VERSION ""

NS_ :

BS_:

BU_: RFA_BLEM TCU GWM _delete GENERIC TSTR
VAL_TABLE_ Null_Passive_Active_NotUsed_1 3 "NotUsed_1" 2 "Active" 1 "Passive" 0 "Null" ;
VAL_TABLE_ VehStrtKeySrc_D_Stat 7 "NotUsed_4" 6 "NotUsed_3" 5 "NotUsed_2" 4 "NotUsed_1" 3 "Legacy_Paak" 2 "Peps_and_Ikt" 1 "Digital_Key" 0 "Null" ;
VAL_TABLE_ StopStrtImccActv_D_St 7 "NotUsed_3" 6 "NotUsed_2" 5 "NotUsed_1" 4 "Deactivated" 3 "OnSuspended" 2 "OnActive" 1 "OnNotActive" 0 "Off" ;
VAL_TABLE_ UpftrEnbl_D_Stat 7 "Error" 6 "AuxAcEnable" 5 "PtoOperation" 4 "FuelEcoModeEnable" 3 "Disable" 2 "Enable" 1 "DisableAttempt" 0 "Reset" ;
VAL_TABLE_ Reset_Off_On_Error 3 "Error" 2 "On" 1 "Off" 0 "Reset" ;
VAL_TABLE_ NfcSerial_D_Rq 3 "PresentAndProvisioned" 2 "PresentAndProvAlertAck" 1 "PresentAndUnprovisioned" 0 "NotPresent" ;
VAL_TABLE_ NoRequest_Disable_Enable_NotUsed 3 "NotUsed_1" 2 "Enable" 1 "Disable" 0 "NoRequest" ;
VAL_TABLE_ AwdLckMde_D_Stat 7 "NotUsed_2" 6 "NotUsed_1" 5 "PrimaryAxleSpeedControl" 4 "DualAxleSpeedControl" 3 "EfficiencySplit" 2 "SecondaryAxleTorqueCtrl" 1 "SecondaryAxleSpeedCtrl" 0 "Off" ;
VAL_TABLE_ EngIdlShutDown_D2_Type 3 "Fleet" 2 "Keyless" 1 "Keyed" 0 "Null" ;
VAL_TABLE_ TlghtTestPrecnd_D2_Stat 7 "TrailerNotConnected" 6 "NotStationary" 5 "InteractionPresent" 4 "PreconditionsPassed" 3 "BattSocLessThan75Percent" 2 "TailLightsOn" 1 "IgnitionNotOn" 0 "Null" ;
VAL_TABLE_ TlghtTestLght_D2_Stat 7 "TestingRearFogLights" 6 "AllOff" 5 "TestingReverseLights" 4 "TestingBrakeLights" 3 "TestingLeftTurnSignal" 2 "TestingRightTurnSignal" 1 "ParkingLightsIlluminated" 0 "Null" ;
VAL_TABLE_ PwTrnkFrontRleas_D_Src 15 "NotUsed_5" 14 "NotUsed_4" 13 "NotUsed_3" 12 "NotUsed_2" 11 "NotUsed_1" 10 "SelfTest" 9 "Diagnostics" 8 "EmergencyReleaseSwitch" 7 "ManualCinch" 6 "ExteriorSwitch" 5 "IpSwitch" 4 "Cpp" 3 "Sync" 2 "Keypad" 1 "Remote" 0 "PowerOff" ;
VAL_TABLE_ StrtrMtrCtlMsgTxt_D_Rq2 15 "Not_Used_12" 14 "Not_Used_11" 13 "Not_Used_10" 12 "Not_Used_9" 11 "Not_Used_8" 10 "Not_Used_7" 9 "Not_Used_6" 8 "Not_Used_5" 7 "Not_Used_4" 6 "Not_Used_3" 5 "Not_Used_2" 4 "Not_Used_1" 3 "Fault_UnableToStrtOrStop" 2 "PressTwiceToStart" 1 "Fault_GoToDealer" 0 "NoMessage" ;
VAL_TABLE_ BptStrtStop_D_Stat 3 "NotUsed_1" 2 "Start" 1 "Stop" 0 "NoRequest" ;
VAL_TABLE_ BptMde_D_Stat 7 "NotUsed_4" 6 "NotUsed_3" 5 "NotUsed_2" 4 "NotUsed_1" 3 "Automatic" 2 "Manual" 1 "Off" 0 "Null" ;
VAL_TABLE_ NoData_Faulty_7FFFFE_7FFFFF 8388607 "Faulty" 8388606 "NoDataExists" ;
VAL_TABLE_ NoData_Faulty_3FFFFE_3FFFFF 4194303 "Faulty" 4194302 "NoDataExists" ;
VAL_TABLE_ BattChrgInhbt_D2_Rq 7 "NotUsed_4" 6 "NotUsed_3" 5 "NotUsed_2" 4 "NotUsed_1" 3 "MaintainTargetSoc" 2 "EndAtTarget" 1 "InhibitCharging" 0 "Enable_Charging" ;
VAL_TABLE_ EngIdlShutDownT_D_Stat 255 "NotUsed_13" 254 "NotUsed_12" 253 "NotUsed_11" 252 "NotUsed_10" 251 "NotUsed_9" 250 "NotUsed_8" 249 "NotUsed_7" 248 "NotUsed_6" 247 "NotUsed_5" 246 "NotUsed_4" 245 "NotUsed_3" 244 "NotUsed_2" 243 "NotUsed_1" 242 "Indefinite_Idle" 241 "Selectable_Idle_Not_Active" 240 "IdleMinutes_240" 239 "IdleMinutes_239" 238 "IdleMinutes_238" 237 "IdleMinutes_237" 236 "IdleMinutes_236" 235 "IdleMinutes_235" 234 "IdleMinutes_234" 233 "IdleMinutes_233" 232 "IdleMinutes_232" 231 "IdleMinutes_231" 230 "IdleMinutes_230" 229 "IdleMinutes_229" 228 "IdleMinutes_228" 227 "IdleMinutes_227" 226 "IdleMinutes_226" 225 "IdleMinutes_225" 224 "IdleMinutes_224" 223 "IdleMinutes_223" 222 "IdleMinutes_222" 221 "IdleMinutes_221" 220 "IdleMinutes_220" 219 "IdleMinutes_219" 218 "IdleMinutes_218" 217 "IdleMinutes_217" 216 "IdleMinutes_216" 215 "IdleMinutes_215" 214 "IdleMinutes_214" 213 "IdleMinutes_213" 212 "IdleMinutes_212" 211 "IdleMinutes_211" 210 "IdleMinutes_210" 209 "IdleMinutes_209" 208 "IdleMinutes_208" 207 "IdleMinutes_207" 206 "IdleMinutes_206" 205 "IdleMinutes_205" 204 "IdleMinutes_204" 203 "IdleMinutes_203" 202 "IdleMinutes_202" 201 "IdleMinutes_201" 200 "IdleMinutes_200" 199 "IdleMinutes_199" 198 "IdleMinutes_198" 197 "IdleMinutes_197" 196 "IdleMinutes_196" 195 "IdleMinutes_195" 194 "IdleMinutes_194" 193 "IdleMinutes_193" 192 "IdleMinutes_192" 191 "IdleMinutes_191" 190 "IdleMinutes_190" 189 "IdleMinutes_189" 188 "IdleMinutes_188" 187 "IdleMinutes_187" 186 "IdleMinutes_186" 185 "IdleMinutes_185" 184 "IdleMinutes_184" 183 "IdleMinutes_183" 182 "IdleMinutes_182" 181 "IdleMinutes_181" 180 "IdleMinutes_180" 179 "IdleMinutes_179" 178 "IdleMinutes_178" 177 "IdleMinutes_177" 176 "IdleMinutes_176" 175 "IdleMinutes_175" 174 "IdleMinutes_174" 173 "IdleMinutes_173" 172 "IdleMinutes_172" 171 "IdleMinutes_171" 170 "IdleMinutes_170" 169 "IdleMinutes_169" 168 "IdleMinutes_168" 167 "IdleMinutes_167" 166 "IdleMinutes_166" 165 "IdleMinutes_165" 164 "IdleMinutes_164" 163 "IdleMinutes_163" 162 "IdleMinutes_162" 161 "IdleMinutes_161" 160 "IdleMinutes_160" 159 "IdleMinutes_159" 158 "IdleMinutes_158" 157 "IdleMinutes_157" 156 "IdleMinutes_156" 155 "IdleMinutes_155" 154 "IdleMinutes_154" 153 "IdleMinutes_153" 152 "IdleMinutes_152" 151 "IdleMinutes_151" 150 "IdleMinutes_150" 149 "IdleMinutes_149" 148 "IdleMinutes_148" 147 "IdleMinutes_147" 146 "IdleMinutes_146" 145 "IdleMinutes_145" 144 "IdleMinutes_144" 143 "IdleMinutes_143" 142 "IdleMinutes_142" 141 "IdleMinutes_141" 140 "IdleMinutes_140" 139 "IdleMinutes_139" 138 "IdleMinutes_138" 137 "IdleMinutes_137" 136 "IdleMinutes_136" 135 "IdleMinutes_135" 134 "IdleMinutes_134" 133 "IdleMinutes_133" 132 "IdleMinutes_132" 131 "IdleMinutes_131" 130 "IdleMinutes_130" 129 "IdleMinutes_129" 128 "IdleMinutes_128" 127 "IdleMinutes_127" 126 "IdleMinutes_126" 125 "IdleMinutes_125" 124 "IdleMinutes_124" 123 "IdleMinutes_123" 122 "IdleMinutes_122" 121 "IdleMinutes_121" 120 "IdleMinutes_120" 119 "IdleMinutes_119" 118 "IdleMinutes_118" 117 "IdleMinutes_117" 116 "IdleMinutes_116" 115 "IdleMinutes_115" 114 "IdleMinutes_114" 113 "IdleMinutes_113" 112 "IdleMinutes_112" 111 "IdleMinutes_111" 110 "IdleMinutes_110" 109 "IdleMinutes_109" 108 "IdleMinutes_108" 107 "IdleMinutes_107" 106 "IdleMinutes_106" 105 "IdleMinutes_105" 104 "IdleMinutes_104" 103 "IdleMinutes_103" 102 "IdleMinutes_102" 101 "IdleMinutes_101" 100 "IdleMinutes_100" 99 "IdleMinutes_99" 98 "IdleMinutes_98" 97 "IdleMinutes_97" 96 "IdleMinutes_96" 95 "IdleMinutes_95" 94 "IdleMinutes_94" 93 "IdleMinutes_93" 92 "IdleMinutes_92" 91 "IdleMinutes_91" 90 "IdleMinutes_90" 89 "IdleMinutes_89" 88 "IdleMinutes_88" 87 "IdleMinutes_87" 86 "IdleMinutes_86" 85 "IdleMinutes_85" 84 "IdleMinutes_84" 83 "IdleMinutes_83" 82 "IdleMinutes_82" 81 "IdleMinutes_81" 80 "IdleMinutes_80" 79 "IdleMinutes_79" 78 "IdleMinutes_78" 77 "IdleMinutes_77" 76 "IdleMinutes_76" 75 "IdleMinutes_75" 74 "IdleMinutes_74" 73 "IdleMinutes_73" 72 "IdleMinutes_72" 71 "IdleMinutes_71" 70 "IdleMinutes_70" 69 "IdleMinutes_69" 68 "IdleMinutes_68" 67 "IdleMinutes_67" 66 "IdleMinutes_66" 65 "IdleMinutes_65" 64 "IdleMinutes_64" 63 "IdleMinutes_63" 62 "IdleMinutes_62" 61 "IdleMinutes_61" 60 "IdleMinutes_60" 59 "IdleMinutes_59" 58 "IdleMinutes_58" 57 "IdleMinutes_57" 56 "IdleMinutes_56" 55 "IdleMinutes_55" 54 "IdleMinutes_54" 53 "IdleMinutes_53" 52 "IdleMinutes_52" 51 "IdleMinutes_51" 50 "IdleMinutes_50" 49 "IdleMinutes_49" 48 "IdleMinutes_48" 47 "IdleMinutes_47" 46 "IdleMinutes_46" 45 "IdleMinutes_45" 44 "IdleMinutes_44" 43 "IdleMinutes_43" 42 "IdleMinutes_42" 41 "IdleMinutes_41" 40 "IdleMinutes_40" 39 "IdleMinutes_39" 38 "IdleMinutes_38" 37 "IdleMinutes_37" 36 "IdleMinutes_36" 35 "IdleMinutes_35" 34 "IdleMinutes_34" 33 "IdleMinutes_33" 32 "IdleMinutes_32" 31 "IdleMinutes_31" 30 "IdleMinutes_30" 29 "IdleMinutes_29" 28 "IdleMinutes_28" 27 "IdleMinutes_27" 26 "IdleMinutes_26" 25 "IdleMinutes_25" 24 "IdleMinutes_24" 23 "IdleMinutes_23" 22 "IdleMinutes_22" 21 "IdleMinutes_21" 20 "IdleMinutes_20" 19 "IdleMinutes_19" 18 "IdleMinutes_18" 17 "IdleMinutes_17" 16 "IdleMinutes_16" 15 "IdleMinutes_15" 14 "IdleMinutes_14" 13 "IdleMinutes_13" 12 "IdleMinutes_12" 11 "IdleMinutes_11" 10 "IdleMinutes_10" 9 "IdleMinutes_9" 8 "IdleMinutes_8" 7 "IdleMinutes_7" 6 "IdleMinutes_6" 5 "IdleMinutes_5" 4 "IdleMinutes_4" 3 "IdleMinutes_3" 2 "IdleMinutes_2" 1 "IdleMinute_1" 0 "Null" ;
VAL_TABLE_ Null_Valid 1 "Valid" 0 "Null" ;
VAL_TABLE_ Null_Factory_User_NotUsed_1 3 "NotUsed_1" 2 "User" 1 "Factory" 0 "Null" ;
VAL_TABLE_ Null_Short_Long_NotUsed_1 3 "NotUsed_1" 2 "Long" 1 "Short" 0 "Null" ;
VAL_TABLE_ NfcDevcDetct_D_Stat 15 "NotUsed_7" 14 "NotUsed_6" 13 "NotUsed_5" 12 "NotUsed_4" 11 "NotUsed_3" 10 "NotUsed_2" 9 "NotUsed_1" 8 "Int2Charging" 7 "Int1Starting" 6 "Ext6FrontEndReader" 5 "Ext5DBackEndReader" 4 "Ext4RrDoorReader" 3 "Ext3RlDoorReader" 2 "Ext2FrDoorReader" 1 "Ext1FlDoorReader" 0 "Null" ;
VAL_TABLE_ NfcDevc_D_Cmd 7 "NotUsed_4" 6 "NotUsed_3" 5 "NotUsed_2" 4 "NotUsed_1" 3 "RemoveAll" 2 "Remove" 1 "Add" 0 "Null" ;
VAL_TABLE_ Null_Fail_Success_NotUsed_1 3 "NotUsed_1" 2 "Success" 1 "Fail" 0 "Null" ;
VAL_TABLE_ NoEve_0_NotSup_FE_Faulty_FF 255 "Faulty" 254 "Not Supported" 0 "No Event" ;
VAL_TABLE_ NoEve_0_NotSup_1FFE_Faulty_1FFF 8191 "Faulty" 8190 "Not Supported" 0 "No Event" ;
VAL_TABLE_ NfcDevc_D_Dsply 15 "Message 15" 14 "Message 14" 13 "Message 13" 12 "Message 12" 11 "Message 11" 10 "Message 10" 9 "Message 9" 8 "Message 8" 7 "Message 7" 6 "Message 6" 5 "Message 5" 4 "Message 4" 3 "Message 3" 2 "Message 2" 1 "Message 1" 0 "No message" ;
VAL_TABLE_ SecondRowBuckle2 7 "Faulty" 6 "OccupiedBelted" 5 "SeatAbsent" 4 "EmptyUnbelted" 3 "OccupiedUnbelted" 2 "BatteryLow" 1 "NotDetermined" 0 "EmptyBelted" ;
VAL_TABLE_ VehOnSrc_D_Stat 15 "NotUsed_11" 14 "NotUsed_10" 13 "NotUsed_9" 12 "NotUsed_8" 11 "NotUsed_7" 10 "NotUsed_6" 9 "EsclRssd" 8 "AutonomousVehicle" 7 "SecureIdle" 6 "FleetVehicleInhibit" 5 "StolenVehicleInhibit" 4 "OverTheAir" 3 "RemoteParkAssist" 2 "RemoteStart" 1 "Manual" 0 "Off" ;
VAL_TABLE_ StrtrMtrCtlMsgTxt_D2_Rq 3 "NoRequestPcmStartingMsgCtl" 2 "ShiftToNeutralToStart" 1 "ShiftToParkToStart" 0 "NoRequestBcmStartingMsgCtl" ;
VAL_TABLE_ GearPrkLck_D_Stat 7 "NotUsed_1" 6 "FetLifeLimitReached" 5 "FetOpenCircuit" 4 "FetOutputShortToPower" 3 "FetOutputShortToGround" 2 "FetNotControlled" 1 "OnPowerToLoad" 0 "OffNoPowerToLoad" ;
VAL_TABLE_ PaakAddErase_D_Rq 3 "EraseAll" 2 "Erase" 1 "Add" 0 "Null" ;
VAL_TABLE_ LcwaMsgTxt_D_Stat 3 "SodXFaulty" 2 "SodXBlocked" 1 "TrailerConnected" 0 "NoMessage" ;
VAL_TABLE_ CamraRearOn_D2_Stat2 7 "Faulty" 6 "NotUsed_3" 5 "NotUsed_2" 4 "NotUsed_1" 3 "Decommission" 2 "Activate" 1 "Deactivate" 0 "Null" ;
VAL_TABLE_ BattChrgTrgtSoC_D_Rq 7 "Percent_50" 6 "Percent_60" 5 "Percent_70" 4 "Percent_80" 3 "Percent_85" 2 "Percent_90" 1 "Percent_95" 0 "Percent_100" ;
VAL_TABLE_ KeyPadCodeProg_D_Rq 7 "NotUsed_3" 6 "NotUsed_2" 5 "NotUsed_1" 4 "DeleteAll" 3 "Delete" 2 "Add" 1 "ProgrammingMode" 0 "Null" ;
VAL_TABLE_ KeyPadCodeProg_D_Stat 7 "NotUsed_2" 6 "Duplicate" 5 "ProgrammingFailure" 4 "DeleteAll" 3 "Delete" 2 "Add" 1 "LearningMode" 0 "NormalMode" ;
VAL_TABLE_ FobTrgtZone_D_Rq 15 "NotUsed_9" 14 "NotUsed_8" 13 "NotUsed_7" 12 "NotUsed_6" 11 "NotUsed_5" 10 "NotUsed_4" 9 "NotUsed_3" 8 "NotUsed_2" 7 "NotUsed_1" 6 "Approach" 5 "RearInterior" 4 "RearExterior" 3 "Passenger" 2 "Driver" 1 "Interior" 0 "Null" ;
VAL_TABLE_ FobTrgtType_D_Rq 7 "NotUsed_4" 6 "NotUsed_3" 5 "NotUsed_2" 4 "NotUsed_1" 3 "Polling" 2 "Registry" 1 "Crypto" 0 "Null" ;
VAL_TABLE_ ModemReset_D_Rq 15 "NotUsed_11" 14 "NotUsed_10" 13 "NotUsed_9" 12 "NotUsed_8" 11 "NotUsed_7" 10 "NotUsed_6" 9 "NotUsed_5" 8 "NotUsed_4" 7 "NotUsed_3" 6 "BrandConnectReset2" 5 "BrandConnectReset1" 4 "CcsReset" 3 "OnlineTrafficReset" 2 "PaakReset" 1 "WifiHotspotReset" 0 "Null" ;
VAL_TABLE_ RstrnOnPsngr_D_RqMnu 15 "Faulty" 14 "NotUsed_11" 13 "NotUsed_10" 12 "ConfiguredOff" 11 "NotUsed_9" 10 "On" 9 "NotUsed_8" 8 "NotUsed_7" 7 "NotUsed_6" 6 "NotUsed_5" 5 "Off" 4 "NotUsed_4" 3 "NotUsed_3" 2 "NotUsed_2" 1 "NotUsed_1" 0 "NoAction" ;
VAL_TABLE_ Null_Low_Med_High 3 "High" 2 "Medium" 1 "Low" 0 "Null" ;
VAL_TABLE_ Null_NotPressed_Pressed 3 "NotUsed" 2 "Pressed" 1 "NotPressed" 0 "Null" ;
VAL_TABLE_ Null_NotAvail_Avail 3 "NotUsed" 2 "Available" 1 "NotAvailable" 0 "Null" ;
VAL_TABLE_ NotDiagnose_FailPass 3 "NotUsed" 2 "Pass" 1 "Fail" 0 "Not_Diagnose_Yet" ;
VAL_TABLE_ Off_On_NotUsed 3 "NotUsed_2" 2 "NotUsed_1" 1 "On" 0 "Off" ;
VAL_TABLE_ OffNoPowerToLoad 7 "FetLowSideOpenOrShort" 6 "FetLifeLimitReached" 5 "FetOpenCircuit" 4 "FetOutputShortToPower" 3 "FetOutputShortToGround" 2 "FetNotControlled" 1 "OnPowerToLoad" 0 "OffNoPowerToLoad" ;
VAL_TABLE_ BrkAppl_D_RqPt 3 "BrakesSlowRelease" 2 "BrakesFastRelease" 1 "BrakesEngage" 0 "NotActive" ;
VAL_TABLE_ Mtr2State_D_ActlMntr 7 "Faulty" 6 "NoDataExists" 5 "NotUsed_1" 4 "ReadinessState" 3 "DeactivationState" 2 "PowerGeneration" 1 "PowerConsumption" 0 "Null" ;
VAL_TABLE_ HybVehMde_D_ActlMntr 7 "Faulty" 6 "NoDataExists" 5 "NotUsed_2" 4 "NotUsed_1" 3 "Fuel" 2 "HybridElectric" 1 "AllElectric" 0 "Null" ;
VAL_TABLE_ ChrgStat_D_ActlMntr 7 "Faulty" 6 "NoDataExists" 5 "NotUsed" 4 "ChargingCompleted" 3 "NotCharging" 2 "ChargingInDrivingState" 1 "ChargingInParkingState" 0 "Null" ;
VAL_TABLE_ Inactive_Enable_Disable_NotUsed 0 "Inactive" 2 "Disable" 1 "Enable" ;
VAL_TABLE_ TrailCtl_D_Stat 7 "Faulty" 6 "DescentOnly" 5 "EnabledDeny" 4 "StandbyOverThreshold" 3 "StandbyOverride" 2 "Active" 1 "EnabledDescent" 0 "Off" ;
VAL_TABLE_ NoFault_Fault 1 "Fault" 0 "NoFault" ;
VAL_TABLE_ PaakTrgtType_D_Rq 7 "NotUsed_4" 6 "NotUsed_3" 5 "NotUsed_2" 4 "NotUsed_1" 3 "Polling" 2 "Registry" 1 "Crypto" 0 "Null" ;
VAL_TABLE_ PaakTrgtZone_D_Rq 15 "NotUsed_9" 14 "NotUsed_8" 13 "NotUsed_7" 12 "NotUsed_6" 11 "NotUsed_5" 10 "NotUsed_4" 9 "NotUsed_3" 8 "NotUsed_2" 7 "NotUsed_1" 6 "Approach" 5 "RearInterior" 4 "RearExterior" 3 "Passenger" 2 "Driver" 1 "Interior" 0 "Null" ;
VAL_TABLE_ PaakTrgtData_D_Rq 5 "NotUsed_2" 4 "Not_Used1" 3 "Target1_IdBlock2" 2 "Target1_IdBlock1" 1 "Challenge" 0 "Idle" 7 "NotUsed_4" 6 "NotUsed_3" ;
VAL_TABLE_ PaakCtlActv_D_Rq 31 "NotUsed_13" 30 "NotUsed_12" 29 "NotUsed_11" 28 "NotUsed_10" 27 "NotUsed_9" 26 "NotUsed_8" 25 "NotUsed_7" 24 "NotUsed_6" 23 "NotUsed_5" 22 "NotUsed_4" 21 "NotUsed_3" 20 "TrunkFrontRelease" 19 "RemoteStop" 18 "RemoteStart" 17 "PowerDecklid" 16 "RightPowerSlidingDoor" 15 "LeftPowerSlidingDoor" 14 "PowerLiftgate" 13 "GlobalClose" 12 "GlobalOpen" 11 "PanicOff" 10 "PanicOn" 9 "LiftgateGlassRelease" 8 "LiftgateRelease" 7 "DecklidRelease" 6 "DoubleLock" 5 "LockAll" 4 "UnlockAllDoorsPlusCargo" 3 "UnlockCargoDoor" 2 "UnlockAllDoors" 1 "UnlockDriverDoor" 0 "Null" ;
VAL_TABLE_ Null_Invalid_Valid 3 "NotUsed" 2 "Valid" 1 "Invalid" 0 "Null" ;
VAL_TABLE_ PaakCtlData_D_Stat 7 "NotUsed_3" 6 "NotUsed_2" 5 "NotUsed_1" 4 "Response" 3 "EchoTargetIdBlock1" 2 "RequestTargetIdBlock2" 1 "RequestTargetIdBlock1" 0 "Idle" ;
VAL_TABLE_ ElPwPoint_D_Rq 3 "On" 2 "Off2" 1 "Off1" 0 "Null" ;
VAL_TABLE_ EngExhMdeQuiet_D2_Rq 7 "NotUsed_3" 6 "NotUsed_2" 5 "NotUsed_1" 4 "Track" 3 "Sport" 2 "Normal" 1 "Stealth" 0 "Null" ;
VAL_TABLE_ NoInhibit_Inhibit 1 "Inhibit" 0 "NoInhibit" ;
VAL_TABLE_ BattTracChiller_D_Stat 3 "NotUsed" 2 "ChillerNotAvailable" 1 "ChillerBrieflyAvailable" 0 "ChillerAvailable" ;
VAL_TABLE_ CakActvtn_D_ 3 "DeactivatedAll" 2 "Deactivated" 1 "Activated" 0 "Null" ;
VAL_TABLE_ Null_NotInUse_InUse 3 "NotUsed" 2 "InUse" 1 "NotInUse" 0 "Null" ;
VAL_TABLE_ PaaKMyKeyChng_D_Stat 3 "NotUsed" 2 "ClearAll" 1 "MyKey" 0 "Null" ;
VAL_TABLE_ FALSE_TRUE 1 "TRUE" 0 "FALSE" ;
VAL_TABLE_ ApnlPsswrdType_D_Stat 15 "NotUsed_3" 14 "NotUsed_2" 13 "NotUsed_1" 12 "ElevatedVehicleBackup" 11 "Elevated" 10 "DriverVehicleBackup" 9 "Driver" 8 "ServiceVehicleBackup" 7 "Service" 6 "UnloaderBackup" 5 "Unloader" 4 "LoaderBackup" 3 "Loader" 2 "RiderBackup" 1 "Rider" 0 "Null" ;
VAL_TABLE_ AuthctnStatChnl_D_Stat 15 "NotUsed_7" 14 "NotUsed_6" 13 "NotUsed_5" 12 "NotUsed_4" 11 "NotUsed_3" 10 "NotUsed_2" 9 "NotUsed_1" 8 "Sync" 7 "SDM_D" 6 "SDM_C" 5 "SDM_B" 4 "SDM_A" 3 "DAP_R" 2 "DAP_L" 1 "Mobile" 0 "Null" ;
VAL_TABLE_ AuthctnInfoLoc_D_Stat 7 "NotUsed_1" 6 "Approach" 5 "RearInterior" 4 "RearExterior" 3 "Passenger" 2 "Driver" 1 "Interior" 0 "Null" ;
VAL_TABLE_ Null_NotAuthen_AuthenFailed_Auth 3 "Authenticated" 2 "AuthenticationFailed" 1 "NotAuthenticated" 0 "Null" ;
VAL_TABLE_ Null_Failed_NotValid_Success 3 "Success" 2 "NotValid" 1 "Failed" 0 "Null" ;
VAL_TABLE_ VehCurbside_D_Stat 7 "NotUsed_3" 6 "NotUsed_2" 5 "NotUsed_1" 4 "Neither" 3 "Both" 2 "Right" 1 "Left" 0 "Null" ;
VAL_TABLE_ VehTvf_D_Stat 223 "NotUsed_202" 222 "NotUsed_201" 221 "NotUsed_200" 220 "NotUsed_199" 219 "NotUsed_198" 218 "NotUsed_197" 217 "NotUsed_196" 216 "NotUsed_195" 215 "NotUsed_194" 214 "NotUsed_193" 213 "NotUsed_192" 212 "NotUsed_191" 211 "NotUsed_190" 210 "NotUsed_189" 209 "NotUsed_188" 208 "NotUsed_187" 207 "NotUsed_186" 206 "NotUsed_185" 205 "NotUsed_184" 204 "NotUsed_183" 203 "NotUsed_182" 202 "NotUsed_181" 201 "NotUsed_180" 200 "NotUsed_179" 199 "NotUsed_178" 198 "NotUsed_177" 197 "NotUsed_176" 196 "NotUsed_175" 195 "NotUsed_174" 194 "NotUsed_173" 193 "NotUsed_172" 192 "NotUsed_171" 191 "NotUsed_170" 190 "NotUsed_169" 189 "NotUsed_168" 188 "NotUsed_167" 187 "NotUsed_166" 186 "NotUsed_165" 185 "NotUsed_164" 184 "NotUsed_163" 183 "NotUsed_162" 182 "NotUsed_161" 181 "NotUsed_160" 180 "NotUsed_159" 179 "NotUsed_158" 178 "NotUsed_157" 177 "NotUsed_156" 176 "NotUsed_155" 175 "NotUsed_154" 174 "NotUsed_153" 173 "NotUsed_152" 172 "NotUsed_151" 171 "NotUsed_150" 170 "NotUsed_149" 169 "NotUsed_148" 168 "NotUsed_147" 167 "NotUsed_146" 166 "NotUsed_145" 165 "NotUsed_144" 164 "NotUsed_143" 163 "NotUsed_142" 162 "NotUsed_141" 161 "NotUsed_140" 160 "NotUsed_139" 159 "NotUsed_138" 158 "NotUsed_137" 157 "NotUsed_136" 156 "NotUsed_135" 155 "NotUsed_134" 154 "NotUsed_133" 153 "NotUsed_132" 152 "NotUsed_131" 151 "NotUsed_130" 150 "NotUsed_129" 149 "NotUsed_128" 148 "NotUsed_127" 147 "NotUsed_126" 146 "NotUsed_125" 145 "NotUsed_124" 144 "NotUsed_123" 143 "NotUsed_122" 142 "NotUsed_121" 141 "NotUsed_120" 140 "NotUsed_119" 139 "NotUsed_118" 138 "NotUsed_117" 137 "NotUsed_116" 136 "NotUsed_115" 135 "NotUsed_114" 134 "NotUsed_113" 133 "NotUsed_112" 132 "NotUsed_111" 131 "NotUsed_110" 130 "NotUsed_109" 129 "NotUsed_108" 128 "NotUsed_107" 127 "NotUsed_106" 126 "NotUsed_105" 125 "NotUsed_104" 124 "NotUsed_103" 123 "NotUsed_102" 122 "NotUsed_101" 121 "NotUsed_100" 120 "NotUsed_99" 119 "NotUsed_98" 118 "NotUsed_97" 117 "NotUsed_96" 116 "NotUsed_95" 115 "NotUsed_94" 114 "NotUsed_93" 113 "NotUsed_92" 112 "NotUsed_91" 111 "NotUsed_90" 110 "NotUsed_89" 109 "NotUsed_88" 108 "NotUsed_87" 107 "NotUsed_86" 106 "NotUsed_85" 105 "NotUsed_84" 104 "NotUsed_83" 103 "NotUsed_82" 102 "NotUsed_81" 101 "NotUsed_80" 100 "NotUsed_79" 99 "NotUsed_78" 98 "NotUsed_77" 97 "NotUsed_76" 96 "NotUsed_75" 95 "NotUsed_74" 94 "NotUsed_73" 93 "NotUsed_72" 92 "NotUsed_71" 91 "NotUsed_70" 90 "NotUsed_69" 89 "NotUsed_68" 88 "NotUsed_67" 87 "NotUsed_66" 86 "NotUsed_65" 85 "NotUsed_64" 84 "NotUsed_63" 83 "NotUsed_62" 82 "NotUsed_61" 81 "NotUsed_60" 80 "NotUsed_59" 79 "NotUsed_58" 78 "NotUsed_57" 77 "NotUsed_56" 76 "NotUsed_55" 75 "NotUsed_54" 74 "NotUsed_53" 73 "NotUsed_52" 72 "NotUsed_51" 71 "NotUsed_50" 70 "NotUsed_49" 69 "NotUsed_48" 68 "NotUsed_47" 67 "NotUsed_46" 66 "NotUsed_45" 65 "NotUsed_44" 64 "NotUsed_43" 63 "NotUsed_42" 62 "NotUsed_41" 61 "NotUsed_40" 60 "NotUsed_39" 59 "NotUsed_38" 58 "NotUsed_37" 57 "NotUsed_36" 56 "NotUsed_35" 55 "NotUsed_34" 54 "NotUsed_33" 53 "NotUsed_32" 52 "NotUsed_31" 51 "NotUsed_30" 50 "NotUsed_29" 49 "NotUsed_28" 48 "NotUsed_27" 47 "NotUsed_26" 46 "NotUsed_25" 45 "NotUsed_24" 44 "NotUsed_23" 43 "NotUsed_22" 42 "NotUsed_21" 41 "NotUsed_20" 40 "NotUsed_19" 39 "NotUsed_18" 38 "NotUsed_17" 37 "NotUsed_16" 36 "NotUsed_15" 35 "NotUsed_14" 34 "NotUsed_13" 33 "NotUsed_12" 32 "NotUsed_11" 31 "NotUsed_10" 30 "NotUsed_9" 29 "NotUsed_8" 28 "NotUsed_7" 27 "NotUsed_6" 26 "NotUsed_5" 25 "NotUsed_4" 24 "NotUsed_3" 23 "NotUsed_2" 22 "NotUsed_1" 21 "GoodsUnloadAuthenticated" 20 "GoodsLoadAuthenticated" 19 "GoodsUnloading" 18 "GoodsLoading" 17 "ApproachingPickupOccupied" 16 "ApproachingDropoff" 15 "InitDriveOccupied" 14 "OnboardingAuthenticated" 13 "ApproachingPickupUnoccup" 12 "AtLogistics" 11 "OffboardingAndOnboarding" 10 "OffboardingMultiple" 9 "OffboardingSingle" 8 "OnboardingOccupiedToSta" 7 "OnboardingMultiple" 6 "OnboardingSingle" 5 "DrivingToBackup" 4 "DrivingToLogistics" 3 "DrivingToDropOff" 2 "DrivingToPickupOccupied" 1 "DrivingToPickupEmpty" 0 "Unassigned" 255 "NotUsed_234" 254 "NotUsed_233" 253 "NotUsed_232" 252 "NotUsed_231" 251 "NotUsed_230" 250 "NotUsed_229" 249 "NotUsed_228" 248 "NotUsed_227" 247 "NotUsed_226" 246 "NotUsed_225" 245 "NotUsed_224" 244 "NotUsed_223" 243 "NotUsed_222" 242 "NotUsed_221" 241 "NotUsed_220" 240 "NotUsed_219" 239 "NotUsed_218" 238 "NotUsed_217" 237 "NotUsed_216" 236 "NotUsed_215" 235 "NotUsed_214" 234 "NotUsed_213" 233 "NotUsed_212" 232 "NotUsed_211" 231 "NotUsed_210" 230 "NotUsed_209" 229 "NotUsed_208" 228 "NotUsed_207" 227 "NotUsed_206" 226 "NotUsed_205" 225 "NotUsed_204" 224 "NotUsed_203" ;
VAL_TABLE_ AplReas_D_Stat 3 "UserOverride" 2 "SystemOverride" 1 "Faulted" 0 "Commanded" ;
VAL_TABLE_ AprReas_D_Stat 3 "UserOverride" 2 "SystemOverride" 1 "Faulted" 0 "Commanded" ;
VAL_TABLE_ BrkCtlSys_D_Stat 15 "ESCDis_TCSDis" 14 "ESCDis_TCSRed" 13 "ESCDis_TCSFull" 12 "ESCDis_TCSNde" 11 "ESCRed_TCSDis" 10 "ESCRed_TCSRed" 9 "ESCRed_TCSFull" 8 "ESCRed_TCSNde" 7 "ESCFull_TCSDis" 6 "ESCFull_TCSRed" 5 "ESCFull_TCSFull" 4 "ESCFull_TCSNde" 3 "ESCNde_TCSDis" 2 "ESCNde_TCSRed" 1 "ESCNde_TCSFull" 0 "ESCNde_TCSNde" ;
VAL_TABLE_ NoResponse_NotSeen_Seen_NotU 3 "NotUsed_1" 2 "Seen" 1 "NotSeen" 0 "NoResponse" ;
VAL_TABLE_ AprSnd_D_Rq 63 "NotUsed_24" 62 "NotUsed_23" 61 "NotUsed_22" 60 "NotUsed_21" 59 "NotUsed_20" 58 "NotUsed_19" 57 "NotUsed_18" 56 "NotUsed_17" 55 "NotUsed_16" 54 "NotUsed_15" 53 "NotUsed_14" 52 "NotUsed_13" 51 "NotUsed_12" 50 "NotUsed_11" 49 "NotUsed_10" 48 "NotUsed_9" 47 "NotUsed_8" 46 "NotUsed_7" 45 "NotUsed_6" 44 "NotUsed_5" 43 "NotUsed_4" 42 "NotUsed_3" 41 "NotUsed_2" 40 "ROpenDoor" 39 "MgMercOpenDoor" 38 "MgRecAuthFail_Max" 37 "RCustCareCalling" 36 "MgRecCustCareCalling" 35 "RCallCustCare" 34 "MgRecCallCustCare" 33 "RItemDetection" 32 "MgRecItemDetection" 31 "MgMercItemDetection" 30 "MgRecOpenDoor" 29 "MgMercLoadOrder" 28 "MgRecBarcodeError" 27 "MgRecBarcode" 26 "RAuthFailMax" 25 "MgMercAuthFailMax" 24 "RAuthFail" 23 "MgMercAuthFail" 22 "R_6ft" 21 "MgRec_6ft" 20 "RAuthSucc" 19 "MgRecAuthSucc" 18 "MgMercAuthSucc" 17 "RMaxTime" 16 "MgRecMaxTime" 15 "MgMercMaxTime" 14 "RExtendTimeUnloading" 13 "RExtendTimeLoading" 12 "MgReciExtendTime" 11 "MgMercExtendTime" 10 "RTimeOutLoading" 9 "RTimeOutUnloading" 8 "MgMercTimeOut" 7 "MgRecTimeOut" 6 "RBttnPressKeypad" 5 "MgRecBttnPressKeypad" 4 "MgMercBttnPressKeypad" 3 "MgMercBttnPressOrder" 2 "RNudge" 1 "MgMercNudge" 0 "NoSound" ;
VAL_TABLE_ NotAvail_OffOn_Faulty 3 "Faulty" 2 "On" 1 "Off" 0 "NotAvailable" ;
VAL_TABLE_ ApaDrvRq2MsgTxt_D_Rq 15 "NotUsed_7" 14 "NotUsed_6" 13 "NotUsed_5" 12 "NotUsed_4" 11 "NotUsed_3" 10 "NotUsed_2" 9 "NotUsed_1" 8 "CloseDoor" 7 "TakeControl" 6 "ReleaseEpb" 5 "ReleaseSteering" 4 "ReleaseBrake" 3 "DriveBackward" 2 "DriveForward" 1 "Stop" 0 "NoRequest" ;
VAL_TABLE_ ApaDrvRq1MsgTxt_D_Rq 7 "NotUsed" 6 "ExitVehicle" 5 "PressApaButton" 4 "ShiftToP" 3 "ShiftToN" 2 "ShiftToD" 1 "ShiftToR" 0 "NoRequest" ;
VAL_TABLE_ DcacFaltMsgTxt_D2_Rq 35 "NotUsed_1" 34 "FrontTrnkPlgWarnDertExceed" 33 "FrontTrnkPlgWarnDerate" 32 "FrontTrnkPlgWarnFullPw" 31 "IpcPlugWarnDrive" 30 "DcacbOvercurrentLp" 29 "DcacbService" 28 "DcacbNotAvailable" 27 "DcacbAcOnOutput" 26 "DcacbTemperature" 25 "DcacbGfci" 24 "DcacbOvercurrent" 23 "PpoUsageWhenVehlsCharging" 22 "RpsNewKeyCycleWarning" 21 "LowSocRpsWarning" 20 "RpsResetWarn_ChngDrvToPark" 19 "RpsResetWarning" 18 "FirstRpsWarning" 63 "NotUsed_29" 17 "PowerTakeoff" 16 "HevDerate" 15 "HvacOn" 14 "OvercurrentLP" 13 "EngineRun" 12 "Service" 11 "NotAvailable" 10 "PlugWarn" 9 "PlugWarnDrive" 8 "BreakerC" 7 "BreakerB" 6 "BreakerA" 5 "FuelLow" 4 "AcOnOutput" 3 "Temperature" 2 "Gfci" 1 "Overcurrent" 0 "Ok" ;
VAL_TABLE_ Hour5bitNull 31 "NotUsed_7" 30 "NotUsed_6" 29 "NotUsed_5" 28 "NotUsed_4" 27 "NotUsed_3" 26 "NotUsed_2" 25 "NotUsed_1" 24 "Hour23_11pm" 23 "Hour22_10pm" 22 "Hour21_9pm" 21 "Hour20_8pm" 20 "Hour19_7pm" 19 "Hour18_6pm" 18 "Hour17_5pm" 17 "Hour16_4pm" 16 "Hour15_3pm" 15 "Hour14_2pm" 14 "Hour13_1pm" 13 "Hour12_12pm" 12 "Hour11_11am" 11 "Hour10_10am" 10 "Hour9_9am" 9 "Hour8_8am" 8 "Hour7_7am" 7 "Hour6_6am" 6 "Hour5_5am" 5 "Hour4_4am" 4 "Hour3_3am" 3 "Hour2_2am" 2 "Hour1_1am" 1 "Hour0_12am" 0 "Null" ;
VAL_TABLE_ Null_Dis_En_NotConfig 3 "NotConfigured" 2 "Enabled" 1 "Disabled" 0 "Null" ;
VAL_TABLE_ TelematicsSrvc_D_St2 7 "NotUsed_1" 6 "NotifyNotActivatedYet" 5 "NotActivatedYet" 4 "NotifyExpired" 3 "Expired" 2 "ExpiringSoon" 1 "Active" 0 "Null" ;
VAL_TABLE_ Null_8bit_GenericValues 255 "Value254" 2 "Value1_up_to_0xFE_Value253" 1 "Value0" 0 "Null" ;
VAL_TABLE_ RmtCtlConfgSrc_D_Stat 7 "NotUsed_2" 6 "NotUsed_1" 5 "BPO" 4 "ApaHmi" 3 "FAP_Handover" 2 "User" 1 "None" 0 "NotDetermined" ;
VAL_TABLE_ RmtCtlPathPlan_D_Stat 7 "NotUsed_3" 6 "NotUsed_2" 5 "NotUsed_1" 4 "FinishedMovesExceeded" 3 "FinishedDistanceExceeded" 2 "Finished" 1 "Ongoing" 0 "None" ;
VAL_TABLE_ RmtCtlAdas_D_Stat 7 "Paused" 6 "Abort" 5 "ManeuverFinished" 4 "EndPositionReached" 3 "Backward" 2 "Forward" 1 "ManeuverBegin" 0 "Inactive" ;
VAL_TABLE_ RmtCtlSns_D_Stat 3 "Zone3" 2 "Zone2" 1 "Zone1" 0 "Off" ;
VAL_TABLE_ PrkMde_D_ET 3 "NotUsed" 2 "FreeDrive" 1 "ParkIn" 0 "None" ;
VAL_TABLE_ RmtCtlPrkInSlot_D_ET 7 "NotUsed_3" 6 "NotUsed_2" 5 "NotUsed_1" 4 "Right" 3 "Left" 2 "Rear" 1 "Front" 0 "None" ;
VAL_TABLE_ Orientation_D_ET 3 "NotUsed" 2 "Backward" 1 "Forward" 0 "Null" ;
VAL_TABLE_ MoveDir_D_ET 3 "NotUsed" 2 "Backward" 1 "Forward" 0 "None" ;
VAL_TABLE_ RmtCtlOrientAvail_D_ET 7 "NotUsed_3" 6 "NotUsed_2" 5 "NotUsed_1" 4 "Both" 3 "Backward" 2 "Forward" 1 "None" 0 "NotDetermined" ;
VAL_TABLE_ ApaSys_D2_Stat 15 "NotUsed_5" 14 "NotUsed_4" 13 "NotUsed_3" 12 "NotUsed_2" 11 "NotUsed_1" 10 "NoSideSelectable" 9 "RightSideSelectable" 8 "LeftSideSelectable" 7 "BothSidesSelectable" 6 "Faulty" 5 "Finished" 4 "Cancelled" 3 "NotAvailable" 2 "Overspeed" 1 "Pause" 0 "NormalOperation" ;
VAL_TABLE_ ApaSlotTrgt_D_Stat 15 "NotUsed_7" 14 "NotUsed_6" 13 "NotUsed_5" 12 "NotUsed_4" 11 "NotUsed_3" 10 "NotUsed_2" 9 "NotUsed_1" 8 "Front" 7 "Rear" 6 "Right3" 5 "Right2" 4 "Right1" 3 "Left3" 2 "Left2" 1 "Left1" 0 "None" ;
VAL_TABLE_ ApaMsgTxt_D2_Stat 15 "ReducedFunction" 14 "TrailerFeatureNotAvailable" 13 "AcceleratorPedalInactive" 12 "SensorsBlocked" 11 "TrailerAttached" 10 "TcsDeactivated" 9 "WheelSlip" 8 "HighInclination" 7 "DoorOpen" 6 "SteeringInteraction" 5 "WrongDirection" 4 "SpeedLimitExceeded" 3 "BrakeEvent" 2 "ObstacleInPath" 1 "WaitForSteering" 0 "None" ;
VAL_TABLE_ DisplayMode 3 "NotUsed" 2 "FullScreen" 1 "Menu" 0 "Off" ;
VAL_TABLE_ ClrExitAsstMsgTxt_D_Rq 15 "NotUsed_8" 14 "NotUsed_7" 13 "NotUsed_6" 12 "NotUsed_5" 11 "NotUsed_4" 10 "NotUsed_3" 9 "NotUsed_2" 8 "NotUsed_1" 7 "SystemFault" 6 "ChildLockMaintained" 5 "WarningRight" 4 "WarningLeft" 3 "InformationRight" 2 "InformationLeft" 1 "Shutdown" 0 "NoMessage" ;
VAL_TABLE_ ClrExitAsstChime_D_Rq 7 "NotUsed_4" 6 "NotUsed_3" 5 "NotUsed_2" 4 "NotUsed_1" 3 "WarningChimeFront" 2 "WarningChimeRear" 1 "InformationChime" 0 "Off" ;
VAL_TABLE_ Disp_LangSel2_Rq 33 "Ukrainian" 32 "Indian_English" 31 "Thai" 30 "Slovak" 29 "Arabic" 28 "Taiwanese" 27 "Mandarin_Chinese" 26 "Korean" 25 "AU_English" 24 "Japanese" 23 "Braz_Portuguese" 22 "EU_Portuguese" 21 "Finish" 20 "Norwegian" 19 "Danish" 18 "Swedish" 17 "Hungarian" 16 "Greek" 15 "Czech" 14 "Polish" 13 "Flemish" 12 "Dutch" 11 "Russian" 10 "Turkish" 9 "Mex_Spanish" 8 "EU_Spanish" 7 "Cana_French" 6 "EU_French" 5 "Italian" 4 "German" 3 "NA_English" 2 "UK_English" 1 "Unknown" 0 "Invalid" ;
VAL_TABLE_ VehHorn_D_Rq 15 "NotUsed_7" 14 "NotUsed_6" 13 "NotUsed_5" 12 "NotUsed_4" 11 "NotUsed_3" 10 "NotUsed_2" 9 "NotUsed_1" 8 "Chirp_3" 7 "ManualOn" 6 "Honk" 5 "ChirpHonk" 4 "Chirp_2H" 3 "Chirp_2" 2 "Chirp_1" 1 "Null" 0 "Off" ;
VAL_TABLE_ Audio_Demo_CMND 2 "On" 1 "Off" 0 "Inactive" ;
VAL_TABLE_ Audio_Visualizer 2 "On" 1 "Off" 0 "Inactive" ;
VAL_TABLE_ Disengaged_Engaged 1 "Engaged" 0 "Disengaged" ;
VAL_TABLE_ AplSnd_D_Rq 63 "NotUsed_24" 62 "NotUsed_23" 61 "NotUsed_22" 60 "NotUsed_21" 59 "NotUsed_20" 58 "NotUsed_19" 57 "NotUsed_18" 56 "NotUsed_17" 55 "NotUsed_16" 54 "NotUsed_15" 53 "NotUsed_14" 52 "NotUsed_13" 51 "NotUsed_12" 50 "NotUsed_11" 49 "NotUsed_10" 48 "NotUsed_9" 47 "NotUsed_8" 46 "NotUsed_7" 45 "NotUsed_6" 44 "NotUsed_5" 43 "NotUsed_4" 42 "NotUsed_3" 41 "NotUsed_2" 40 "ROpenDoor" 39 "MgMercOpenDoor" 38 "MgRecAuthFail_Max" 37 "RCustCareCalling" 36 "MgRecCustCareCalling" 35 "RCallCustCare" 34 "MgRecCallCustCare" 33 "RItemDetection" 32 "MgRecItemDetection" 31 "MgMercItemDetection" 30 "MgRecOpenDoor" 29 "MgMercLoadOrder" 28 "MgRecBarcodeError" 27 "MgRecBarcode" 26 "RAuthFailMax" 25 "MgMercAuthFailMax" 24 "RAuthFail" 23 "MgMercAuthFail" 22 "R_6ft" 21 "MgRec_6ft" 20 "RAuthSucc" 19 "MgRecAuthSucc" 18 "MgMercAuthSucc" 17 "RMaxTime" 16 "MgRecMaxTime" 15 "MgMercMaxTime" 14 "RExtendTimeUnloading" 13 "RExtendTimeLoading" 12 "MgReciExtendTime" 11 "MgMercExtendTime" 10 "RTimeOutLoading" 9 "RTimeOutUnloading" 8 "MgMercTimeOut" 7 "MgRecTimeOut" 6 "RBttnPressKeypad" 5 "MgRecBttnPressKeypad" 4 "MgMercBttnPressKeypad" 3 "MgMercBttnPressOrder" 2 "RNudge" 1 "MgMercNudge" 0 "NoSound" ;
VAL_TABLE_ NoCallRequest_RequestCall_Cancel 3 "PwFailed" 2 "CancelCall" 1 "RequestCall" 0 "NoCallRequest" ;
VAL_TABLE_ TrnkFrontRleas_D_Src 7 "NotUsed_3" 6 "NotUsed_2" 5 "NotUsed_1" 4 "Cpp" 3 "Sync" 2 "Keypad" 1 "Remote" 0 "Null" ;
VAL_TABLE_ Null_InProcess_Complete 3 "NotUsed" 2 "Complete" 1 "InProcess" 0 "Null" ;
VAL_TABLE_ TrlrAlarmSpprt_D_Stat 3 "SupportedByBrakesAndLights" 2 "SupportedByLights" 1 "SupportedByBrakes" 0 "NotSupported" ;
VAL_TABLE_ Null_Extend_Retract 3 "NotUsed" 2 "Retract" 1 "Extend" 0 "Null" ;
VAL_TABLE_ CellLock_D_Rq_Rsm 7 "NotUsed3" 6 "NotUsed2" 5 "NotUsed1" 4 "TrunkRelPopGlassLgCargo" 3 "LockAllDoorsandTailgate" 2 "UnlockDriversDoor" 1 "UnlockAllDoorsandTailgate" 0 "NoRequest" ;
VAL_TABLE_ VehInhbtMde_D_Stat 7 "NotUsed_3" 6 "NotUsed_2" 5 "NotUsed_1" 4 "FullVehicleOta" 3 "Iviota" 2 "SyncOta" 1 "NoOtaSupport" 0 "Unconfigured" ;
VAL_TABLE_ RmtCtlTrgt_D_Rq 3 "NotUsed" 2 "Null" 1 "RemoteParkAssist" 0 "ManeuverId" ;
VAL_TABLE_ RmtCtlBody_D_Stat 15 "NotUsed_6" 14 "NotUsed_5" 13 "NotUsed_4" 12 "NotUsed_3" 11 "NotUsed_2" 10 "NotUsed_1" 9 "Shutdown" 8 "ManeuverFinished" 7 "ReadyForResume" 6 "Pause" 5 "Maneuvering" 4 "ReadyForManeuvering" 3 "Activation" 2 "Initialize" 1 "Preparation" 0 "Disabled" ;
VAL_TABLE_ RmtCtl_D_RqBody 7 "NotUsed_2" 6 "NotUsed_1" 5 "Error" 4 "Abort" 3 "PauseKeypad" 2 "PauseHazard" 1 "PauseDoorHandle" 0 "Null" ;
VAL_TABLE_ Null_Disabled_Enabled 3 "NotUsed" 2 "Enabled" 1 "Disabled" 0 "Null" ;
VAL_TABLE_ RmtCtlRngSet_D_Rq 3 "NotUsed" 2 "RangeSetB" 1 "RangeSetA" 0 "None" ;
VAL_TABLE_ Null_NoPolling_Polling 3 "NotUsed" 2 "Polling" 1 "NoPolling" 0 "Null" ;
VAL_TABLE_ RmtCtl_D_Stat 15 "Faulty" 14 "NotUsed_5" 13 "NotUsed_4" 12 "NotUsed_3" 11 "NotUsed_2" 10 "NotUsed_1" 9 "Shutdown" 8 "ManeuverFinished" 7 "ReadyForResume" 6 "Pause" 5 "Maneuvering" 4 "ReadyForManeuvering" 3 "Activation" 2 "Initialize" 1 "Preparation" 0 "Disabled" ;
VAL_TABLE_ PaakLoclzd_D_Stat 15 "NotUsed_12" 14 "NotUsed_11" 13 "NotUsed_10" 12 "NotUsed_9" 11 "NotUsed_8" 10 "NotUsed_7" 9 "NotUsed_6" 8 "NotUsed_5" 7 "NotUsed_4" 6 "NotUsed_3" 5 "NotUsed_2" 4 "NotUsed_1" 3 "FullLoc" 2 "PausedLoc" 1 "MaintainLink" 0 "BackgroundScan" ;
VAL_TABLE_ SelDrvMdeChassis2_D_Rq 31 "Faulty" 30 "NotUsed17" 29 "NotUsed16" 28 "NotUsed15" 27 "NotUsed14" 26 "NotUsed13" 25 "NotUsed12" 24 "NotUsed11" 23 "NotUsed10" 22 "NotUsed9" 21 "NotUsed8" 20 "NotUsed7" 19 "NotUsed6" 18 "NotUsed5" 17 "NotUsed4" 16 "OnePedalDrive" 15 "DragMode" 14 "RoughRoadMode" 13 "TrackMode" 12 "HighSpeedDesertMode" 11 "TowHaulMode" 10 "RockCrawlMode" 9 "SandMode" 8 "MudAndRutsMode" 7 "LowMuMode" 6 "ComfortAdaptiveMode" 5 "ComfortMode" 4 "SportAdaptiveMode" 3 "SportMode" 2 "EconomyMode" 1 "NormalAdaptiveMode" 0 "NormalMode" ;
VAL_TABLE_ CCOI_Policy 15 "NotUsed_4" 14 "NotUsed_3" 13 "NotUsed_2" 12 "NotUsed_1" 11 "DataStorageError" 10 "StateMachineInconsistent" 9 "UnrecoverableSyncError" 8 "OnBoardSyncFailed" 7 "OnBoardImplemented" 6 "OnBoardSynchronized" 5 "OnBoardSynchronizing" 4 "OnBoardSyncNeeded" 3 "OffBoardUpdatePending" 2 "OnBoardUpdatePending" 1 "Waiting" 0 "Null" ;
VAL_TABLE_ TelematicsSrvc_D_St 7 "NotUsed" 6 "NotifyNotActivatedYet" 5 "NotActivatedYet" 4 "NotifyExpired" 3 "Expired" 2 "ExpiringSoon" 1 "Active" 0 "Null" ;
VAL_TABLE_ TCU_ESN_D_Rq 3 "NotUsed" 2 "TCU_ESN_Request" 1 "NoRequest" 0 "Inactive" ;
VAL_TABLE_ FactoryReset_Rq 1 "ResetFactoryDefaults" 0 "Inactive" ;
VAL_TABLE_ Telematics_D_Falt 7 "NotUsed_5" 6 "NotUsed_4" 5 "NotUsed_3" 4 "NotUsed_2" 3 "NotUsed_1" 2 "RunTimeError" 1 "ChipsetInitializationFailu" 0 "Null" ;
VAL_TABLE_ Null_NotConnected_Conn 3 "NotUsed" 2 "Connected" 1 "NotConnected" 0 "Null" ;
VAL_TABLE_ Null_Disable_Enable 3 "NotUsed" 2 "Enable" 1 "Disable" 0 "Null" ;
VAL_TABLE_ WaitToStartLamp_D_Falt 3 "NotUsed" 2 "Wait_to_start_lamp_failed" 1 "Diagnosis_not_ready" 0 "Wait_to_start_lamp_OK" ;
VAL_TABLE_ WifiHtsptTrial_D_RqDrv 3 "NotUsed_1" 2 "StopReminders" 1 "RemindMeLater" 0 "Null" ;
VAL_TABLE_ ModemTechnology_D2_Stat 7 "Lte" 6 "HspaPlus" 5 "Umts" 4 "Edge" 3 "Gprs" 2 "Gsm" 1 "NoNetwork" 0 "Null" ;
VAL_TABLE_ BattClntVlvOvrrd_D_Rq 3 "NotUsed" 2 "OverrideTbcvToChiller" 1 "OverrideTbcvToRadiator" 0 "NoOverrideToTbcvCLogic" ;
VAL_TABLE_ AutoTowAllw_D_StatMnu 3 "TowHaulCommandedOn" 2 "AutoTowHaulEnabled" 1 "AutoTowHaulDisabled" 0 "NoSelection" ;
VAL_TABLE_ EmgcyCall_D_Stat 7 "NotUsed_3" 6 "NotUsed_2" 5 "NotUsed_1" 4 "ManualEmergencyCall" 3 "AutoEmergencyCall" 2 "NoEvent" 1 "EmergencyCallNotSupported" 0 "Null" ;
VAL_TABLE_ NotAsserted_Asserted 1 "Asserted" 0 "NotAsserted" ;
VAL_TABLE_ GearLvr_D_ActlDrv 15 "Fault" 14 "Unknown_Position" 13 "NotUsed_2" 12 "NotUsed_1" 11 "Range6" 10 "Range5" 9 "Range4" 8 "Range3_M3_L3" 7 "Range2_M2_L2" 6 "Range1_M1_L1" 5 "Low" 4 "Sport_DriveSport_Mposition" 3 "Drive" 2 "Neutral" 1 "Reverse" 0 "Park" ;
VAL_TABLE_ TrnPrkSys_D_Actl 15 "Faulty" 14 "NotUsed_5" 13 "NotUsed_4" 12 "NotUsed_3" 11 "NotUsed_2" 10 "NotUsed_1" 9 "FrequencyError" 8 "OutOfRangeHigh" 7 "OutOfRangeLow" 6 "Override" 5 "OutOfPark" 4 "TransitionCloseToOutOfPark" 3 "AtNoSpring" 2 "TransitionCloseToPark" 1 "Park" 0 "NotKnown" ;
VAL_TABLE_ OKLowUnknownInvalid 3 "Invalid" 2 "Unknown" 1 "Low" 0 "OK" ;
VAL_TABLE_ PrkAidDrvDir_D_Stat 7 "NotUsed_2" 6 "NotUsed_1" 5 "BackwardNegative" 4 "ForwardNegative" 3 "BackwardPositive" 2 "ForwardPositive" 1 "NoMotion" 0 "DirectionNotKnown" ;
VAL_TABLE_ Pers1Phone_D_Stat 7 "SevenPhoneAssociated" 6 "SixPhoneAssociated" 5 "FivePhoneAssociated" 4 "FourPhoneAssociated" 3 "ThreePhoneAssociated" 2 "TwoPhoneAssociated" 1 "OnePhoneAssociated" 0 "NoPhoneAssociated" ;
VAL_TABLE_ EmgcyCallHmi_D_Stat 15 "NotUsed_1" 14 "Standby" 13 "Disabled" 12 "Malfunction" 11 "CallCompleted" 10 "CallDisconnected" 9 "CallNotPossible" 8 "CallCancelled" 7 "CallRetry" 6 "CallConnected" 5 "CallInProgress" 4 "CallMsdTransfer" 3 "CallDial" 2 "CallCancelTimer" 1 "NoEvent" 0 "Null" ;
VAL_TABLE_ GasPrtc_D_RqDsply 7 "NotUsed_5" 6 "NotUsed_4" 5 "NotUsed_3" 4 "NotUsed_2" 3 "NotUsed_1" 2 "GpfOverLimit" 1 "GpfAtLimit" 0 "NormalOperation" ;
VAL_TABLE_ EmgcyCallMute_D_Stat 7 "NotUsed4" 6 "NotUsed3" 5 "NotUsed2" 4 "NotUsed1" 3 "ManualEmergencyCallMute" 2 "AutomaticEmergencyCallMute" 1 "EmergencyCallUnmute" 0 "Null" ;
VAL_TABLE_ WifiHtsptEnbl_D_Rq 3 "Not used" 2 "On" 1 "Off" 0 "Null" ;
VAL_TABLE_ WifiHtsptVisbl_D_Rq 3 "Not used" 2 "On" 1 "Off" 0 "Null" ;
VAL_TABLE_ WifiRemoveDevc_D_Rq 3 "NotUsed_1" 2 "FromBlockedList" 1 "FromConnectedList" 0 "Null" ;
VAL_TABLE_ WifiHtsptEnbl_D_Stat 3 "OnDisabled" 2 "On" 1 "Off" 0 "Null" ;
VAL_TABLE_ WifiDevcListNew_B_Stat 1 "Available" 0 "NotAvailable" ;
VAL_TABLE_ WifiHtsptScrty_D_Rq 3 "NotUsed_1" 2 "Wapi" 1 "Wpa2_Wpa" 0 "Null" ;
VAL_TABLE_ WifiDevcList_D_Rq 3 "NoEntry" 2 "BlockedList" 1 "ConnectedList" 0 "Null" ;
VAL_TABLE_ WifiCarrierInfo_B_Rq 1 "Request" 0 "No  request" ;
VAL_TABLE_ WifiHtsptScrty_D_Stat 3 "NotUsed_1" 2 "Wapi" 1 "Wpa2_Wpa" 0 "Null" ;
VAL_TABLE_ WifiDataUsage_D_Rq 3 "RetriveDataFromBackend" 2 "RefreshData" 1 "CurrentData" 0 "Null" ;
VAL_TABLE_ WifiHtsptVisbl_D_Stat 3 "Not  used" 2 "On" 1 "Off" 0 "Null" ;
VAL_TABLE_ ModemSigStren_D_Stat 7 "NotUsed_1" 6 "NotDetermined" 5 "FiveBars" 4 "FourBars" 3 "ThreeBars" 2 "TwoBars" 1 "OneBar" 0 "ZeroBars" ;
VAL_TABLE_ WifiHtsptMacAddr_B_Rq 1 "Request" 0 "No request" ;
VAL_TABLE_ WifiDataUsage_D_Stat 3 "PercentDataUsed" 2 "DataPlanExpired" 1 "FreeTrialPeriodWaiting" 0 "Null" ;
VAL_TABLE_ WakeAlarm0_B_Typ 1 "CanAndEcuDriveCircuit" 0 "CanOnly" ;
VAL_TABLE_ WiprFront_D_Stat2 15 "NO_DATA_EXISTS" 14 "STALLED" 13 "NotUsed" 12 "AUTO_ADJUST" 11 "COURTESYWIPE" 10 "AUTO_HIGH" 9 "AUTO_LOW" 8 "WASH" 7 "MIST_FLICK" 6 "MAN_HIGH" 5 "MAN_LOW" 4 "MAN_INT_ON" 3 "MAN_INT_OFF" 2 "OFF_MOVING" 1 "AUTO_OFF" 0 "OFF" ;
VAL_TABLE_ TurnLghtSwtch_D_Stat2 3 "NotUsed" 2 "Right" 1 "Left" 0 "Off" ;
VAL_TABLE_ Closed_Open_Active_Denied 3 "Denied" 2 "Active" 1 "Open" 0 "Closed" ;
VAL_TABLE_ Fault_Occupied_Empty_Un 3 "Unknown" 2 "Empty" 1 "Occupied" 0 "Fault" ;
VAL_TABLE_ KeyOffMde_D_Actl 15 "NotUsed_11" 14 "NotUsed_10" 13 "NotUsed_9" 12 "NotUsed_8" 11 "NotUsed_7" 10 "NotUsed_6" 9 "NotUsed_5" 8 "NotUsed_4" 7 "NotUsed_3" 6 "NotUsed_2" 5 "NotUsed_1" 4 "CriticalBattery" 3 "Hibernate" 2 "Transport" 1 "Factory" 0 "Normal" ;
VAL_TABLE_ IaccVLim_D_Rq 252 "NotUsed_2" 250 "LimitSpeed_250" 240 "LimitSpeed_240" 230 "LimitSpeed_230" 220 "LimitSpeed_220" 210 "LimitSpeed_210" 200 "LimitSpeed_200" 190 "LimitSpeed_190" 150 "LimitSpeed_150" 140 "LimitSpeed_140" 130 "LimitSpeed_130" 120 "LimitSpeed_120" 110 "LimitSpeed_110" 100 "LimitSpeed_100" 90 "LimitSpeed_90" 80 "LimitSpeed_80" 70 "LimitSpeed_70" 60 "LimitSpeed_60" 50 "LimitSpeed_50" 40 "LimitSpeed_40" 30 "LimitSpeed_30" 20 "LimtSpeed_20" 251 "NotUsed_1" 255 "Faulty" 254 "NoDataExists" 253 "NotUsed_3" 180 "LimitSpeed_180" 179 "LimitSpeed_179" 178 "LimitSpeed_178" 177 "LimitSpeed_177" 176 "LimitSpeed_176" 175 "LimitSpeed_175" 174 "LimitSpeed_174" 173 "LimitSpeed_173" 172 "LimitSpeed_172" 171 "LimitSpeed_171" 170 "LimitSpeed_170" 169 "LimitSpeed_169" 168 "LimitSpeed_168" 167 "LimitSpeed_167" 166 "LimitSpeed_166" 165 "LimitSpeed_165" 164 "LimitSpeed_164" 163 "LimitSpeed_163" 162 "LimitSpeed_162" 161 "LimitSpeed_161" 160 "LimitSpeed_160" 15 "LimitSpeed_15" 14 "LimitSpeed_14" 13 "LimitSpeed_13" 12 "LimitSpeed_12" 11 "LimitSpeed_11" 10 "LimitSpeed_10" 9 "LimitSpeed_9" 8 "LimitSpeed_8" 7 "LimitSpeed_7" 6 "LimitSpeed_6" 5 "LimitSpeed_5" 4 "LimitSpeed_4" 3 "LimitSpeed_3" 2 "LimitSpeed_2" 1 "LimitSpeed_1" 0 "LimitSpeed_0" ;
VAL_TABLE_ IaccVLimUnit_D_Rq 3 "NoDataExists" 2 "Mph" 1 "Kph" 0 "Null" ;
VAL_TABLE_ SelDrvMdeAwd_D_Rq 31 "Faulty" 30 "NotUsed_17" 29 "NotUsed_16" 28 "NotUsed_15" 27 "NotUsed_14" 26 "NotUsed_13" 25 "NotUsed_12" 24 "NotUsed_11" 23 "NotUsed_10" 22 "NotUsed_9" 21 "NotUsed_8" 20 "CustomMode" 19 "OnePedalDrive" 18 "DragMode" 17 "EvLaterChargeMode" 16 "EvNowMode" 15 "TrackMode" 14 "RoughRoadMode" 13 "NotAvailable" 12 "HighSpeedDesertMode_Baja" 11 "SportAdaptiveMode" 10 "RockCrawlMode" 9 "MudRutsMode" 8 "SandMode" 7 "EconomyMode" 6 "GrassGravelSnow" 5 "TowHaulMode" 4 "SportMode" 3 "Normal_4L" 2 "Normal_4A" 1 "Normal_2H" 0 "NormalMode" ;
VAL_TABLE_ HeadLghtHiPrmsn_D_Stat 3 "CancelAndSuppress" 2 "Cancel" 1 "Hold" 0 "AllowChange" ;
VAL_TABLE_ SelDrvMdeSwtch 3 "Faulty" 2 "SwitchState2" 1 "SwitchState1" 0 "NotPressed" ;
VAL_TABLE_ AwdDrvMde 7 "Faulty" 6 "NotAvailable" 5 "RockCrawl" 4 "Baja" 3 "MudAndSand" 2 "Weather" 1 "Sport" 0 "Normal" ;
VAL_TABLE_ SelDrvMdePt_D_Rq 31 "Faulty" 30 "NotUsed15" 29 "NotUsed14" 28 "NotUsed13" 27 "NotUsed12" 26 "NotUsed11" 25 "NotUsed10" 24 "NotUsed9" 23 "NotUsed8" 22 "NotUsed7" 21 "CustomMode" 20 "TrackMode" 19 "OnePedalDrive" 18 "EvLaterChargerMode" 17 "EvNowMode" 16 "DragMode" 15 "HighSpeedDesertMode_Baja" 14 "SportAdaptiveMode" 13 "NotAvailable_13" 12 "NotAvailable_12" 11 "NotAvailable_11" 10 "NotAvailable_10" 9 "RockCrawlMode" 8 "MudRutsMode" 7 "SandMode" 6 "EconomyMode" 5 "GrassGravelSnow" 4 "NotAvailable_04" 3 "TowHaulMode" 2 "NotAvailable_02" 1 "SportMode" 0 "NormalMode" ;
VAL_TABLE_ OffLockUnlockFaulty 3 "Faulty" 2 "Unlock" 1 "Lock" 0 "Off" ;
VAL_TABLE_ OffOnOutOfRange 3 "NotUsed" 2 "OutOfRange" 1 "On" 0 "Off" ;
VAL_TABLE_ NoMessage_Msg1_15 15 "Message15" 14 "Message14" 13 "Message13" 12 "Message12" 11 "Message11" 10 "Message10" 9 "Message9" 8 "Message8" 7 "Message7" 6 "Message6" 5 "Message5" 4 "Message4" 3 "Message3" 2 "Message2" 1 "Message1" 0 "NoMessage" ;
VAL_TABLE_ SelDrvMdeChassis_D_Rq 31 "Faulty" 30 "NotUsed17" 29 "NotUsed16" 28 "NotUsed15" 27 "NotUsed14" 26 "NotUsed13" 25 "NotUsed12" 24 "NotUsed11" 23 "NotUsed10" 22 "NotUsed9" 21 "NotUsed8" 20 "NotUsed7" 19 "NotUsed6" 18 "NotUsed5" 17 "NotUsed4" 16 "OnePedalDrive" 15 "DragMode" 14 "RoughRoadMode" 13 "TrackMode" 12 "HighSpeedDesertMode" 11 "TowHaulMode" 10 "RockCrawlMode" 9 "SandMode" 8 "MudAndRutsMode" 7 "LowMuMode" 6 "ComfortAdaptiveMode" 5 "ComfortMode" 4 "SportAdaptiveMode" 3 "SportMode" 2 "EconomyMode" 1 "NormalAdaptiveMode" 0 "NormalMode" ;
VAL_TABLE_ NotAvailable_Available 1 "Available" 0 "NotAvailable" ;
VAL_TABLE_ VehTrvlDir_D_Stat 7 "Faulty" 6 "NoDataExists" 5 "NotUsed2" 4 "NotUsed1" 3 "Reverse" 2 "LikelyReverse" 1 "Forward" 0 "LikelyForward" ;
VAL_TABLE_ ApaBrk_D_Stat 3 "Denied" 2 "Active" 1 "Open" 0 "Closed" ;
VAL_TABLE_ OffLowMedHigh 3 "High" 2 "Medium" 1 "Low" 0 "Off" ;
VAL_TABLE_ HeadLghtHiCtrl_D_RqAhb 7 "NotUsed2" 6 "NotUsed1" 5 "Auto_HiBeam" 4 "Auto_LoBeam" 3 "Flash" 2 "Man_HiBeam" 1 "Man_LoBeam" 0 "Null" ;
VAL_TABLE_ WiprFrontSwtch_D_Stat 15 "NotUsed6" 14 "NotUsed5" 13 "NotUsed4" 12 "NotUsed3" 11 "NotUsed2" 10 "NotUsed1" 9 "PositionNotDetermined" 8 "High" 7 "Low" 6 "Position6" 5 "Position5" 4 "Position4" 3 "Position3" 2 "Position2" 1 "Position1" 0 "Off" ;
VAL_TABLE_ Off_On_Unknown_Invalid 3 "Invalid" 2 "Unknown" 1 "On" 0 "Off" ;
VAL_TABLE_ OffOnNotUsedFaulty 3 "Faulty" 2 "NotUsed" 1 "On" 0 "Off" ;
VAL_TABLE_ HeadLghtOn_D_Rq 7 "NotUsed2" 6 "NotUsed1" 5 "DrlBoth" 4 "DrlRight" 3 "DrlLeft" 2 "High" 1 "Low" 0 "Off" ;
VAL_TABLE_ BrkBstrVac_D_Stat 3 "NotUsed" 2 "BoosterVacEstimator" 1 "BoosterVacSensor" 0 "NoBoosterVacuumMonitor" ;
VAL_TABLE_ AwdMde_D_RqArb 7 "Faulty" 6 "NotUsed2" 5 "NoRequest" 4 "Neutral" 3 "FourByFourLow" 2 "FourByFourHigh" 1 "FourByFourAuto" 0 "FourByTwo" ;
VAL_TABLE_ PoliceIdlMde_D_Stat 15 "NotUsed_7" 14 "NotUsed_6" 13 "NotUsed_5" 12 "NotUsed_4" 11 "NotUsed_3" 10 "UtilityIdleActive" 9 "PepsActive" 8 "Decommissioned" 7 "ActiveFault" 6 "ArmFault" 5 "PrearmedFault" 4 "OffFault" 3 "Active" 2 "Arm" 1 "Prearmed" 0 "Off" ;
VAL_TABLE_ TripComputerMetricImperial 0 "TripComputer_metric" 1 "TripComputer_imperial" ;
VAL_TABLE_ PrkBrkMsgTxt_D_Rq 15 "Message15" 14 "Message14" 13 "Message13" 12 "Message12" 11 "Message11" 10 "Message10" 9 "Message9" 8 "Message8" 7 "Message7" 6 "Message6" 5 "Message5" 4 "Message4" 3 "Message3" 2 "Message2" 1 "Message1" 0 "No_Message" ;
VAL_TABLE_ AutoHoldMsgTxt_D_Rq 15 "Message15" 14 "Message14" 13 "Message13" 12 "Message12" 11 "Message11" 10 "Message10" 9 "Message9" 8 "Message8" 7 "Message7" 6 "Message6" 5 "Message5" 4 "Message4" 3 "Message3" 2 "Message2" 1 "Message1" 0 "NoMessage" ;
VAL_TABLE_ AutoHoldMde_D_Ind 3 "Indication_3" 2 "Indication_2" 1 "Indication_1" 0 "Off" ;
VAL_TABLE_ AutoRgenTxt_B_RqDsply 1 "AutExhFilterCleanOFF" 0 "AutExhFilterCleanON" ;
VAL_TABLE_ EngExhMdeQuiet_D_Stat 3 "Faulty" 2 "QuietExhaust" 1 "LoudExhaust" 0 "Null" ;
VAL_TABLE_ BrkPadMsgTxt_D_Rq 3 "Faulty" 2 "PadsOk" 1 "ReplacePads" 0 "Null" ;
VAL_TABLE_ TracKeyMde_D_Stat 3 "NotUsed" 2 "NotActive" 1 "Active" 0 "ModeNotDetermined" ;
VAL_TABLE_ TrnManShifGear_D_IndDrv 7 "Indicate_Reverse_Gear" 6 "Indicate_Gear6" 5 "Indicate_Gear5" 4 "Indicate_Gear4" 3 "Indicate_Gear3" 2 "Indicate_Gear2" 1 "Indicate_Gear1" 0 "No_Indication" ;
VAL_TABLE_ LsmcBrkDecel_D_Stat 7 "NotUsed_3" 6 "NotUsed_2" 5 "NotUsed_1" 4 "Denied" 3 "FaultDegraded" 2 "FaultExt" 1 "On" 0 "Off" ;
VAL_TABLE_ StePinOffst_D_Stat 3 "FineOffset" 2 "CoarseOffset" 1 "StoredOffset" 0 "OffsetNotCalculated" ;
VAL_TABLE_ OffOn_RampUpDown 3 "Ramp_Down" 2 "Ramp_Up" 1 "On" 0 "Off" ;
VAL_TABLE_ DieslMsgTxt_D_Rq 3 "NotUsed2" 2 "NotUsed1" 1 "ReducedEnginePower" 0 "NoMessage" ;
VAL_TABLE_ NoMessage_Msg1_7 7 "Message7" 6 "Message6" 5 "Message5" 4 "Message4" 3 "Message3" 2 "Message2" 1 "Message1" 0 "NoMessage" ;
VAL_TABLE_ BrkLineLck_D_Rq 3 "Off" 2 "Engage" 1 "Initiate" 0 "NoRequest" ;
VAL_TABLE_ BrkLineLck_D_Stat 7 "NotUsed_3" 6 "NotUsed_2" 5 "NotUsed_1" 4 "NotAvailable" 3 "Off" 2 "Engaged" 1 "Initiated" 0 "Available" ;
VAL_TABLE_ LnchCtlSys_D_Stat 7 "NotUsed" 6 "On_LC_Unavailable_TC_Off" 5 "On_LC_Available_TC_Off" 4 "On_LC_Unavailable_TC_On" 3 "On_LC_Unavailable" 2 "On_LC_Available" 1 "On_LC_Active" 0 "LC_OFF" ;
VAL_TABLE_ Rght_Lefthand_Traffic 1 "Left_Hand_Traffic" 0 "Right_Hand_Traffic" ;
VAL_TABLE_ IsaVLimUnit_D_Rq 3 "NoDataExists" 2 "Mph" 1 "Kph" 0 "Null" ;
VAL_TABLE_ BrkDrvMde_D_Rq 7 "Faulty" 6 "RockCrawl" 5 "Baja" 4 "DragOrMudAndSand" 3 "Track" 2 "Snow_Wet" 1 "Sport" 0 "Normal" ;
VAL_TABLE_ NoYesNoDataFaulty 3 "Faulty" 2 "NoDataExists" 1 "Yes" 0 "No" ;
VAL_TABLE_ PtDrvMde_D_Rq 15 "Faulty" 14 "NotUsed11" 13 "NotUsed10" 12 "NotUsed9" 11 "NotUsed8" 10 "NotUsed7" 9 "NotUsed6" 8 "Track" 7 "Drag" 6 "Rock" 5 "Baja" 4 "Sand" 3 "TowHaulGradeAssist" 2 "SnowWet" 1 "Sport" 0 "Normal" ;
VAL_TABLE_ SteEffort_D_Stat 7 "NotUsed_3" 6 "NotUsed_2" 5 "NotUsed_1" 4 "SpecialMode_2" 3 "SpecialMode_1" 2 "Comfort" 1 "Sport" 0 "Normal" ;
VAL_TABLE_ Null_Off_On 3 "NotUsed" 2 "On" 1 "Off" 0 "Null" ;
VAL_TABLE_ TrlrBrkMde_D_Rq 1 "ElectricOverHydraulic" 0 "Electric" ;
VAL_TABLE_ TrlrAidMsgTxt_D_Rq 31 "Message31" 30 "Message30" 29 "Message29" 28 "Message28" 27 "Message27" 26 "Message26" 25 "Message25" 24 "Message24" 23 "Message23" 22 "Message22" 21 "Message21" 20 "Message20" 19 "Message19" 18 "Message18" 17 "Message17" 16 "Message16" 15 "Message15" 14 "Message14" 13 "Message13" 12 "Message12" 11 "Message11" 10 "Message10" 9 "Message9" 8 "Message8" 7 "Message7" 6 "Message6" 5 "Message5" 4 "Message4" 3 "Message3" 2 "Message2" 1 "Message1" 0 "NoMessage" ;
VAL_TABLE_ Invalid_7F 127 "Invalid" ;
VAL_TABLE_ Faulty_1FFF 8191 "Faulty" ;
VAL_TABLE_ VehStab_D_Stat 15 "Faulty" 14 "No_Data_Exists" 13 "NotUsed6" 12 "NotUsed5" 11 "NotUsed4" 10 "NotUsed3" 9 "NotUsed2" 8 "Combined_OS_and_US" 7 "High_SSRA_no_OS" 6 "Straight" 5 "Post_Oversteer" 4 "Post_Transition" 3 "Countersteer" 2 "Understeer" 1 "Oversteer" 0 "Linear" ;
VAL_TABLE_ NoData_Faulty_1FF_1FE 511 "Faulty" 510 "NoDataExists" ;
VAL_TABLE_ FohEng_D_Rq 3 "AutoEnable_ParkEnable" 2 "AutoDisable_ParkEnable" 1 "AutoEnable_ParkDisable" 0 "Disable_Stop" ;
VAL_TABLE_ OffOn_Null_NotUsed 3 "NotUsed" 2 "Null" 1 "On" 0 "Off" ;
VAL_TABLE_ PrkLckCtlEnbl_D_RqIpc 3 "Rq_Towing" 2 "Rq_Enable" 1 "Rq_Disable" 0 "Null" ;
VAL_TABLE_ PrkLckCtlUnlck_D_Stat 3 "Trans_And_Steer_Unlckd" 2 "Steering_Unlckd" 1 "Transmission_Unlckd" 0 "Null" ;
VAL_TABLE_ VehLckInd_D_Rq 3 "NotUsed" 2 "On_Day" 1 "On_Night" 0 "Off" ;
VAL_TABLE_ PrkBrkDynmc_D_Allw 3 "NotUsed" 2 "EPB_ECD_NotPossible" 1 "EPB_ECD_Possible" 0 "Used_at_Start_Up" ;
VAL_TABLE_ TowBarMsgTxt_D_Rq 7 "NotUsed3" 6 "NotUsed2" 5 "NotUsed1" 4 "TowBar_Ext_No_Trlr" 3 "Error_Dealer_Fix" 2 "Start_Engine_Swivel" 1 "Check_Tow_Bar" 0 "Null" ;
VAL_TABLE_ NoData_Faulty_3E_3F 63 "Faulty" 62 "NoDataExists" ;
VAL_TABLE_ NoData_Faulty_1FFF_1FFE 8191 "Faulty" 8190 "NoDataExists" ;
VAL_TABLE_ AirSusp_D_RqDrv 3 "NotUsed" 2 "On" 1 "Off" 0 "NoModeSelected" ;
VAL_TABLE_ AutoRgen_D_Rq 3 "NotUsed" 2 "AutExhFilterCleanOFF" 1 "AutExhFilterCleanON" 0 "No_Mode_Selected" ;
VAL_TABLE_ TrnSrvcRqd_B_Rq 1 "On" 0 "Off" ;
VAL_TABLE_ immoSecureIdleMode 3 "NotUsed2" 2 "NotUsed1" 1 "Active" 0 "Inactive" ;
VAL_TABLE_ SteMdule_D_Stat 7 "NotUsed" 6 "EPAS_Failure3" 5 "EPAS_Failure2" 4 "System_Failure" 3 "EPAS_Shutdown" 2 "Normal_Op_Full_Assist" 1 "Normal_Op_Limited_Assist" 0 "EPAS_Initialization" ;
VAL_TABLE_ Faulty_FFF 4095 "Faulty" ;
VAL_TABLE_ Faulty_3FF 1023 "Faulty" ;
VAL_TABLE_ NoData_Faulty_FE_FF 255 "Faulty" 254 "NoDataExists" ;
VAL_TABLE_ ChkPlgtoStrt_D_Dsply 3 "NotUsed" 2 "Is_VehicleUnplugged_Prompt" 1 "Check_Plug_to_Start" 0 "No_Message_Display" ;
VAL_TABLE_ PwrFlowTxt_D_Dsply 15 "NotUsed7" 14 "NotUsed6" 13 "NotUsed5" 12 "NotUsed4" 11 "Disply_Rgen_Chrg_Txt" 10 "Disp_Fast_Charge_Txt" 9 "Disp_Fast_Charge_Cmplt_Txt" 8 "Disp_Charge_Cmplt_Txt" 7 "Disp_Remote_Start_Txt" 6 "Disp_Eng_Drv_Txt" 5 "Disp_Elec_Drv_Txt" 4 "Disp_Idle_with_Chrg_Txt" 3 "Disp_Idle_Txt" 2 "Disp_Charg_HV_Batt_Txt" 1 "Disp_Hyb_Drive_Txt" 0 "No_Text" ;
VAL_TABLE_ EngOnMsg_D_Dsply 14 "_0xE_to_1F_NotUsed" 12 "Battery_Temperature" 11 "Hill_Decent_Control" 10 "Fuel_Maintenance" 9 "Oil_Maintenance" 8 "Normal_Operation" 7 "Low_Gear" 6 "Batt_Charging" 5 "Engine_Cold" 4 "Neutral_Gear" 3 "Heater_Setting" 2 "High_Speed" 1 "Acceleration" 0 "No_Display" 13 "Drive_Mode_Selection" ;
VAL_TABLE_ FuelMaintMde_D_Dsply 3 "Feature_Not_Present" 2 "In_Fuel_Maint_Mode" 1 "Close_to_Fuel_Maint" 0 "OK" ;
VAL_TABLE_ DynoMde_B_Cmd 1 "DynomometerMode" 0 "NormalOperation" ;
VAL_TABLE_ HvacPrecondRecirc_D_Rq 3 "Last_User_Setting" 2 "Auto" 1 "Recirc" 0 "Outside" ;
VAL_TABLE_ HvacPrecondAC_D_Rq 3 "Last_User_Setting" 2 "Auto" 1 "On" 0 "Off" ;
VAL_TABLE_ HybMdeLimMsgTxt_D_Rq 3 "Limited_Req_Full_Defrost" 2 "Limited_Climate_Defrost" 1 "Limited_System_Performance" 0 "Null" ;
VAL_TABLE_ NoData_Faulty_FFFE_FFFF 65535 "Faulty" 65534 "NoDataExists" ;
VAL_TABLE_ NoData_Faulty_FFE_FFF 4095 "Faulty" 4094 "NoDataExists" ;
VAL_TABLE_ NoData_Faulty_7FFE_7FFF 32767 "Faulty" 32766 "NoDataExists" ;
VAL_TABLE_ OffOn_NotUsed 3 "NotUsed2" 2 "NotUsed1" 1 "On" 0 "Off" ;
VAL_TABLE_ PepsKeyActv_D_Stat 15 "NotUsed11" 14 "NotUsed10" 13 "NotUsed9" 12 "NotUsed8" 11 "NotUsed7" 10 "NotUsed6" 9 "NotUsed5" 8 "Key4Active" 7 "NotUsed4" 6 "NotUsed3" 5 "NotUsed2" 4 "Key3Active" 3 "NotUsed1" 2 "Key2Active" 1 "Key1Active" 0 "NoKeyActive" ;
VAL_TABLE_ CellRstrt_D_Rq 3 "NotUsed" 2 "RemoteCancel" 1 "RemoteStart" 0 "NoRequest" ;
VAL_TABLE_ CellChirp_D_Rq 7 "NotUsed3" 6 "NotUsed2" 5 "NotUsed1" 4 "Honk" 3 "ChirpHonk" 2 "Chirp2" 1 "Chirp1" 0 "NoRequest" ;
VAL_TABLE_ KeyPadCodeDgt1_D_Stat 15 "NotUsed_4" 14 "NotUsed_3" 13 "NotUsed_2" 12 "NotUsed_1" 11 "Button7_8and9_0" 10 "Button0" 9 "Button9_0or9" 8 "Button8" 7 "Button7_8or7" 6 "Button6" 5 "Button5_6or5" 4 "Button4" 3 "Button3_4or3" 2 "Button2" 1 "Button1_2or1" 0 "EndofString" ;
VAL_TABLE_ ULoBattTransfer_D_Stat 7 "NotUsed_2" 6 "NotUsed_1" 5 "TransferError" 4 "TransferComplete" 3 "TransferThroughGridEnergy" 2 "InsufficientEnergyToXfer" 1 "TransferInProgress" 0 "NoTransfer" ;
VAL_TABLE_ LongCtrlEnbl_D_Rq 7 "Faulty" 6 "NotUsed_3" 5 "NotUsed_2" 4 "NotUsed_1" 3 "RemoteParking" 2 "Autohitch" 1 "AutomaticParking" 0 "None" ;
VAL_TABLE_ BrkHold_D_Stat 7 "NotUsed_3" 6 "NotUsed_2" 5 "NotUsed_1" 4 "HeldSecondary" 3 "HeldSecure" 2 "Held" 1 "Inactive" 0 "Off" ;
VAL_TABLE_ Null_Left_Right 3 "NotUsed" 2 "Right" 1 "Left" 0 "Null" ;
VAL_TABLE_ NoRequest_Up 1 "Up" 0 "NoRequest" ;
VAL_TABLE_ HybMdeMsgTxt_D2_Rq 15 "NotUsed_4" 14 "NotUsed_3" 13 "NotUsed_2" 12 "NotUsed_1" 11 "EvOverride_Avail" 10 "EvLaterActv_EvAuto_NowAvai" 9 "EvNowActv_EvAuto_LaterAvai" 8 "EvAutoActv_EvNow_LaterAvai" 7 "EvAutoActv_NoOtherMdeAvail" 6 "EvChrgActv_EvAutoMdeAvail" 5 "EvAutoActv_EvChrgMdeAvail" 4 "EvChrgActv_AllPhevMdeAvail" 3 "EvLaterActv_AllPhevMdeAvai" 2 "EvNowActv_AllPhevMdeAvail" 1 "EvAutoActv_AllPhevMdeAvail" 0 "Null" ;
VAL_TABLE_ TsrRegionTxt_D_Stat 31 "Faulty" 30 "NotUsed_8" 29 "NotUsed_7" 28 "NotUsed_6" 27 "NotUsed_5" 26 "NotUsed_4" 25 "NotUsed_3" 24 "NotUsed_2" 23 "NotUsed_1" 22 "Region_22" 21 "Region_21" 20 "Region_20" 19 "Region_19" 18 "Region_18" 17 "Region_17" 16 "Region_16" 15 "Region_15" 14 "Region_14" 13 "Region_13" 12 "Region_12" 11 "Region_11" 10 "Region_10" 9 "Region_09" 8 "Region_08" 7 "Region_07" 6 "Region_06" 5 "Region_05" 4 "Region_04" 3 "Region_03" 2 "Region_02" 1 "Region_01" 0 "NotDetermined" ;
VAL_TABLE_ Inactive_On_NotUsed 7 "NotUsed_6" 6 "NotUsed_5" 5 "NotUsed_4" 4 "NotUsed_3" 0 "Inactive" 1 "On" 2 "NotUsed_1" 3 "NotUsed_2" ;
VAL_TABLE_ UpDownNotUsedFaulty 3 "Faulty" 2 "NotUsed" 1 "Down" 0 "Up" ;
VAL_TABLE_ PtWakeReas_D_Stat 15 "NotUsed_9" 14 "NotUsed_8" 13 "NotUsed_7" 12 "NotUsed_6" 11 "NotUsed_5" 10 "NotUsed_4" 9 "NotUsed_3" 8 "NotUsed_2" 7 "NotUsed_1" 6 "ElapsedTime" 5 "ThirdPartyWakeup" 4 "DoorAjar" 3 "EarlyWake" 2 "NonMotiveStart" 1 "MotiveStart" 0 "Null" ;
VAL_TABLE_ ModemAuthrz_D_Stat2 3 "Null" 2 "RemoveKeys" 1 "Authorized" 0 "NotAuthorized" ;
VAL_TABLE_ PaakSerial_D2_Rq2 7 "NotUsed_3" 6 "NotUsed_1" 5 "NotUsed_1" 4 "PresentKeyDelivered" 3 "PresentReadyForKeyDelivery" 2 "PresentBlemProvAlertAck" 1 "PresentUnprovisioned" 0 "NotPresent" ;
VAL_TABLE_ Null_Band1_2 3 "NotUsed_1" 2 "Band_2" 1 "Band_1" 0 "Null" ;
VAL_TABLE_ Null_Error1_15 15 "Error15" 14 "Error14" 13 "Error13" 12 "Error12" 11 "Error11" 10 "Error10" 9 "Error9" 8 "Error8" 7 "Error7" 6 "Error6" 5 "Error5" 4 "Error4" 3 "Error3" 2 "Error2" 1 "Error1" 0 "Null" ;
VAL_TABLE_ WifiHtsptFq_D_Avail 7 "NotUsed_3" 6 "NotUsed_2" 5 "NotUsed_1" 4 "AllAvailable" 3 "Band_2_Only" 2 "Band_1_Only" 1 "AllRestricted" 0 "Null" ;
VAL_TABLE_ BattTracClntVlv_D_Stat 7 "FetLowSideOpenOrShort" 6 "FetLifeLimitReached" 5 "FetOpenCircuit" 4 "FetOutputShortToPower" 3 "FetOutputShortToGround" 2 "FetNotControlled" 1 "OnPowerToLoad" 0 "OffNoPowerToLoad" ;
VAL_TABLE_ ChrgStat_D2_Dsply 15 "ChargeStopCommanded" 14 "ChargeStartCommanded" 13 "ChargeTargetReached" 12 "DriveConditioning" 11 "CabinPreconditioning" 10 "ChargingSystemMaintain" 9 "ChargingInductive" 8 "ChargingDCFastCharge" 7 "ChargingAC" 6 "ChargeScheduled" 5 "EvsePaused" 4 "EvseNotDetected" 3 "EvseNotCompatible" 2 "FaultOutsideCar" 1 "FaultInsideCar" 0 "NotReady" ;
VAL_TABLE_ EngMdeMsgTxt_D_Rq 7 "NotUsed_3" 6 "NotUsed_2" 5 "NotUsed_1" 4 "Charge" 3 "GlowingCharge" 2 "Hybrid" 1 "Ev" 0 "NoMessage" ;
VAL_TABLE_ NoReqHiDecelLowDecel 3 "NotUsed" 2 "LowDecel" 1 "HighDecel" 0 "NoRequest" ;
VAL_TABLE_ OpenClosedRetainDisable 3 "Disable" 2 "Retain" 1 "Closed" 0 "Open" ;
VAL_TABLE_ _S_Inactive_1_Off_2_On 2 "On" 1 "Off" 0 "Inactive" ;
VAL_TABLE_ _S_SurndSndUpmix 4 "Audience" 3 "On_Stage" 2 "Surround" 1 "Stereo" 0 "Inactive" ;
VAL_TABLE_ _S_Level1_to_127_8Bit 255 "NotUsed_127" 254 "NotUsed_126" 253 "NotUsed_125" 252 "NotUsed_124" 251 "NotUsed_123" 250 "NotUsed_122" 249 "NotUsed_121" 248 "NotUsed_120" 247 "NotUsed_119" 246 "NotUsed_118" 245 "NotUsed_117" 244 "NotUsed_116" 243 "NotUsed_115" 242 "NotUsed_114" 241 "NotUsed_113" 240 "NotUsed_112" 239 "NotUsed_111" 238 "NotUsed_110" 237 "NotUsed_109" 236 "NotUsed_108" 235 "NotUsed_107" 234 "NotUsed_106" 233 "NotUsed_105" 232 "NotUsed_104" 231 "NotUsed_103" 230 "NotUsed_102" 229 "NotUsed_101" 228 "NotUsed_100" 227 "NotUsed_99" 226 "NotUsed_98" 225 "NotUsed_97" 224 "NotUsed_96" 223 "NotUsed_95" 222 "NotUsed_94" 221 "NotUsed_93" 220 "NotUsed_92" 219 "NotUsed_91" 218 "NotUsed_90" 217 "NotUsed_89" 216 "NotUsed_88" 215 "NotUsed_87" 214 "NotUsed_86" 213 "NotUsed_85" 212 "NotUsed_84" 211 "NotUsed_83" 210 "NotUsed_82" 209 "NotUsed_81" 208 "NotUsed_80" 207 "NotUsed_79" 206 "NotUsed_78" 205 "NotUsed_77" 204 "NotUsed_76" 203 "NotUsed_75" 202 "NotUsed_74" 201 "NotUsed_73" 200 "NotUsed_72" 199 "NotUsed_71" 198 "NotUsed_70" 197 "NotUsed_69" 196 "NotUsed_68" 195 "NotUsed_67" 194 "NotUsed_66" 193 "NotUsed_65" 192 "NotUsed_64" 191 "NotUsed_63" 190 "NotUsed_62" 189 "NotUsed_61" 188 "NotUsed_60" 187 "NotUsed_59" 186 "NotUsed_58" 185 "NotUsed_57" 184 "NotUsed_56" 183 "NotUsed_55" 182 "NotUsed_54" 181 "NotUsed_53" 180 "NotUsed_52" 179 "NotUsed_51" 178 "NotUsed_50" 177 "NotUsed_49" 176 "NotUsed_48" 175 "NotUsed_47" 174 "NotUsed_46" 173 "NotUsed_45" 172 "NotUsed_44" 171 "NotUsed_43" 170 "NotUsed_42" 169 "NotUsed_41" 168 "NotUsed_40" 167 "NotUsed_39" 166 "NotUsed_38" 165 "NotUsed_37" 164 "NotUsed_36" 163 "NotUsed_35" 162 "NotUsed_34" 161 "NotUsed_33" 160 "NotUsed_32" 159 "NotUsed_31" 158 "NotUsed_30" 157 "NotUsed_29" 156 "NotUsed_28" 155 "NotUsed_27" 154 "NotUsed_26" 153 "NotUsed_25" 152 "NotUsed_24" 151 "NotUsed_23" 150 "NotUsed_22" 149 "NotUsed_21" 148 "NotUsed_20" 147 "NotUsed_19" 146 "NotUsed_18" 145 "NotUsed_17" 144 "NotUsed_16" 143 "NotUsed_15" 142 "NotUsed_14" 141 "NotUsed_13" 140 "NotUsed_12" 139 "NotUsed_11" 138 "NotUsed_10" 137 "NotUsed_9" 136 "NotUsed_8" 135 "NotUsed_7" 134 "NotUsed_6" 133 "NotUsed_5" 132 "NotUsed_4" 131 "NotUsed_3" 130 "NotUsed_2" 129 "NotUsed_1" 128 "Level127" 127 "Level126" 126 "Level125" 125 "Level124" 124 "Level123" 123 "Level122" 122 "Level121" 121 "Level120" 120 "Level119" 119 "Level118" 118 "Level117" 117 "Level116" 116 "Level115" 115 "Level114" 114 "Level113" 113 "Level112" 112 "Level111" 111 "Level110" 110 "Level109" 109 "Level108" 108 "Level107" 107 "Level106" 106 "Level105" 105 "Level104" 104 "Level103" 103 "Level102" 102 "Level101" 101 "Level100" 100 "Level99" 99 "Level98" 98 "Level97" 97 "Level96" 96 "Level95" 95 "Level94" 94 "Level93" 93 "Level92" 92 "Level91" 91 "Level90" 90 "Level89" 89 "Level88" 88 "Level87" 87 "Level86" 86 "Level85" 85 "Level84" 84 "Level83" 83 "Level82" 82 "Level81" 81 "Level80" 80 "Level79" 79 "Level78" 78 "Level77" 77 "Level76" 76 "Level75" 75 "Level74" 74 "Level73" 73 "Level72" 72 "Level71" 71 "Level70" 70 "Level69" 69 "Level68" 68 "Level67" 67 "Level66" 66 "Level65" 65 "Level64" 64 "Level63" 63 "Level62" 62 "Level61" 61 "Level60" 60 "Level59" 59 "Level58" 58 "Level57" 57 "Level56" 56 "Level55" 55 "Level54" 54 "Level53" 53 "Level52" 52 "Level51" 51 "Level50" 50 "Level49" 49 "Level48" 48 "Level47" 47 "Level46" 46 "Level45" 45 "Level44" 44 "Level43" 43 "Level42" 42 "Level41" 41 "Level40" 40 "Level39" 39 "Level38" 38 "Level37" 37 "Level36" 36 "Level35" 35 "Level34" 34 "Level33" 33 "Level32" 32 "Level31" 31 "Level30" 30 "Level29" 29 "Level28" 28 "Level27" 27 "Level26" 26 "Level25" 25 "Level24" 24 "Level23" 23 "Level22" 22 "Level21" 21 "Level20" 20 "Level19" 19 "Level18" 18 "Level17" 17 "Level16" 16 "Level15" 15 "Level14" 14 "Level13" 13 "Level12" 12 "Level11" 11 "Level10" 10 "Level9" 9 "Level8" 8 "Level7" 7 "Level6" 6 "Level5" 5 "Level4" 4 "Level3" 3 "Level2" 2 "Level1" 1 "Level0" 0 "Inactive" ;
VAL_TABLE_ EngIdlShutDwnTxt_D_Rq 3 "NotUsed" 2 "EngineShutdownOnPrevDrive" 1 "FeatureDisabledDueToFault" 0 "NoMessage" ;
VAL_TABLE_ DrvPerfMde 3 "Sport" 2 "Normal" 1 "NotUsed" 0 "NoModeSelected" ;
VAL_TABLE_ NoData_Fault_1FF_1FE 511 "Fault" 510 "NoDataExists" ;
VAL_TABLE_ NoData_Fault_FFE_FFF 4095 "Fault" 4094 "NoDataExists" ;
VAL_TABLE_ EngIdlShutDown_D_Stat 3 "Not_used" 2 "Engine_Shutdown" 1 "Initiated_Countdown" 0 "Normal_Operation" ;
VAL_TABLE_ StopStrtDrvMde_D_RqMnu 3 "NotUsed2" 2 "NotUsed1" 1 "StopStart_Deselected" 0 "StopStart_Selected" ;
VAL_TABLE_ Quality_Faulty 3 "OK" 2 "Degraded" 1 "No_Data_Exists" 0 "Faulty" ;
VAL_TABLE_ Fault_3FFF 16383 "Fault" ;
VAL_TABLE_ NoRequest_Request 1 "Request" 0 "NoRequest" ;
VAL_TABLE_ Fault_FFF_NoData 4094 "NoDataExists" 4095 "Fault" ;
VAL_TABLE_ Fault_3FF_NoData 1022 "NoDataExists" 1023 "Fault" ;
VAL_TABLE_ ActiveStoragePassenger 7 "Unused3" 6 "Unused2" 5 "Unused1" 4 "StoreDipMemoryButton4" 3 "StoreDipMemoryButton3" 2 "StoreDipMemoryButton2" 1 "StoreDipMemoryButton1" 0 "Off" ;
VAL_TABLE_ DipMirror 1 "Dipped" 0 "Off" ;
VAL_TABLE_ WindowCmd 7 "Unused2" 6 "Unused1" 5 "NotDefined" 4 "Audo_Down" 3 "Manual_Down" 2 "Auto_Up" 1 "Manual_Up" 0 "Idle" ;
VAL_TABLE_ MirrorCmd 7 "Unused" 6 "Unfold" 5 "Fold" 4 "Right" 3 "Left" 2 "Down" 1 "Up" 0 "Idle" ;
VAL_TABLE_ WindowPosition 7 "Unused2" 6 "Unused1" 5 "Fully_Open" 4 "Bet60Percent_FullyOpen" 3 "Bet10Percent_60Percent" 2 "BetFully_10PercentOpen" 1 "Fully_Closed" 0 "Undefined" ;
VAL_TABLE_ OKLowVeryLow 3 "NotUsed" 2 "VeryLow" 1 "Low" 0 "OK" ;
VAL_TABLE_ NoMessage_DisplayMessage 1 "DisplayMessage" 0 "NoMessage" ;
VAL_TABLE_ EngineBrakeOff_Active 1 "Engine_Braking_Activated" 0 "Engine_Braking_Off" ;
VAL_TABLE_ EngSrvcRqd_B_Rq 1 "Engine_Service_Required" 0 "No_engine_service_required" ;
VAL_TABLE_ Allowed_Denied 1 "Denied" 0 "Allowed" ;
VAL_TABLE_ FrostWarn_D_Stat 3 "NotUsed" 2 "On_Amber" 1 "On_Red" 0 "Off" ;
VAL_TABLE_ SteWhlLckMsgTxt_D_Rq 3 "Message_3" 2 "Message_2" 1 "Message_1" 0 "No_Message" ;
VAL_TABLE_ GearRvrse_D_Actl 7 "Fault" 6 "NotUsed_3" 5 "NotUsed_2" 4 "NotUsed_1" 3 "Active_confirmed" 2 "Active_not_confirmed" 1 "Inactive_confirmed" 0 "Inactive_not_confirmed" ;
VAL_TABLE_ DcacElPw_D_Rq 3 "NotUsed" 2 "AC_HighPower_Requested" 1 "AC_LowPower_Requested" 0 "AC_Power_NotRequested" ;
VAL_TABLE_ False_True 1 "True" 0 "False" ;
VAL_TABLE_ Null_Ack_Nack_NotUsed 3 "Not_Used" 2 "Nack" 1 "Ack" 0 "Null" ;
VAL_TABLE_ Null_Reset 1 "Reset" 0 "Null" ;
VAL_TABLE_ Unknown_FFFD_Invalid_NotSup 65535 "Not_Supported" 65534 "Invalid" 65533 "Unknown" ;
VAL_TABLE_ immoMsgTxt_D_Rq 15 "Immo_Msg_15" 14 "Immo_Msg_14" 13 "Immo_Msg_13" 12 "Immo_Msg_12" 11 "Immo_Msg_11" 10 "Immo_Msg_10" 9 "Immo_Msg_9" 8 "Immo_Msg_8" 7 "Immo_Msg_7" 6 "Immo_Msg_6" 5 "Immo_Msg_5" 4 "Immo_Msg_4" 3 "Immo_Msg_3" 2 "Immo_Msg_2" 1 "Immo_Msg_1" 0 "Immo_Msg_0_Null" ;
VAL_TABLE_ NoData_Faulty_7E_7F 127 "Faulty" 126 "NoDataExists" ;
VAL_TABLE_ Disp_LangSel_St 31 "Thai" 30 "Slovak" 29 "Arabic" 28 "Taiwanese" 27 "Mandarin_Chinese" 26 "Korean" 25 "AU_English" 24 "Japanese" 23 "Braz_Portuguese" 22 "EU_Portuguese" 21 "Finish" 20 "Norwegian" 19 "Danish" 18 "Swedish" 17 "Hungarian" 16 "Greek" 15 "Czech" 14 "Polish" 13 "Flemish" 12 "Dutch" 11 "Russian" 10 "Turkish" 9 "Mex_Spanish" 8 "EU_Spanish" 7 "Cana_French" 6 "EU_French" 5 "Italian" 4 "German" 3 "NA_English" 2 "UK_English" 1 "Unknown" 0 "Invalid" ;
VAL_TABLE_ Diagnostic_Operation_Rq 7 "SignalStrength" 6 "SDARSESNNumber" 5 "SpeakerWalkAround" 4 "CalibrationPartNumber" 15 "Reserved" 3 "HardwarePartNumber" 2 "SoftwarePartNumber" 1 "GetAllBackgroundDiagRq" 0 "Inactive" ;
VAL_TABLE_ Bezel_Diag_Module_Rq 15 "Reserved" 3 "EFP" 2 "DSP_AMP" 1 "AHU" 0 "Inactive" ;
VAL_TABLE_ Surround_Sound_Upmix 2 "Surround" 1 "Stereo" 0 "Inactive" ;
VAL_TABLE_ HMI_HMIMode_St 7 "NotUsed2" 6 "NotUsed1" 5 "Load_Shed_Active" 0 "Invalid" 1 "OffMode" 2 "On" 3 "Phone" 4 "Climate" ;
VAL_TABLE_ FuelPumpPwr_D_Stat 7 "NotUsed3" 6 "NotUsed2" 5 "NotUsed1" 4 "Power_Off_Default" 3 "Power_Off_Command" 2 "Power_Off_Service" 1 "Power_Off_Impact" 0 "Power_On" ;
VAL_TABLE_ PrmtrAlrmEvnt_D_Stat 15 "Diag_Tamper" 14 "Trailer" 13 "Shock_Sensor" 12 "Post_Crash" 11 "Panic" 10 "Intrusion" 9 "Inclination" 8 "Ign_Tamper" 7 "LG_Door" 6 "Decklid" 5 "Hood" 4 "PR_Door" 3 "PF_Door" 2 "DR_Door" 1 "DF_Door" 0 "Null" ;
VAL_TABLE_ SecurityMsgTxt_D_Rq 3 "Message3" 2 "Message2" 1 "Message1" 0 "NoMessage" ;
VAL_TABLE_ BattChrgInhbt_D_Rq 3 "MaintainTargetSoc" 2 "NotUsed" 1 "InhibitChargingThermal" 0 "Enable_Charging" ;
VAL_TABLE_ PtcHtr_D_Stat 3 "Faulty" 2 "NotUsed" 1 "On" 0 "Off" ;
VAL_TABLE_ PtcHtr_D_Cmd 3 "TurnOn" 2 "AutoMode" 1 "TurnOff" 0 "NoDecision_Initializing" ;
VAL_TABLE_ NoData_Fault_FFFE_FFFF 65535 "Fault" 65534 "NoDataExists" ;
VAL_TABLE_ EngOffTe_B_Dsply 1 "Eng_warm_engh_for_pd" 0 "Eng_not_warm_engh_for_pd" ;
VAL_TABLE_ Fault_1FFF 8191 "Fault" ;
VAL_TABLE_ TrlrBattChrg_D_Stat 3 "Reverse" 2 "Normal" 1 "Low" 0 "Null" ;
VAL_TABLE_ TrlrLampCtl_D_Stat 3 "NotUsed" 2 "TrlrLampCnnctDrvFailure" 1 "TrlrLampNotCnnctDrvFailure" 0 "Null" ;
VAL_TABLE_ ElPw_D_StatStrtStop 15 "NotUsed6" 14 "NotUsed5" 13 "NotUsed4" 12 "NotUsed3" 11 "NotUsed2" 10 "NotUsed1" 9 "Supported_Level_4" 8 "Supported_Level_3" 7 "Supported_Level_2" 6 "Supported_Level_1" 5 "Limited_Support" 4 "Fault_Limited" 3 "LV_Event_in_Progress" 2 "Not_Supported_Imminent" 1 "Supported_All" 0 "Not_Supported" ;
VAL_TABLE_ ImpactEvntFdbck_D_Stat 3 "NotUsed" 2 "EventComplete" 1 "EventInProgress" 0 "Normal" ;
VAL_TABLE_ NoData_Fault_3E_3F 63 "Fault" 62 "NoDataExists" ;
VAL_TABLE_ DrvSte_D_Stat 15 "NotUsed10" 14 "NotUsed9" 13 "NotUsed8" 12 "NotUsed7" 11 "NotUsed6" 10 "NotUsed5" 9 "NotUsed4" 8 "NotUsed3" 7 "NotUsed2" 6 "NotUsed1" 5 "Request_Active" 4 "Ignition_Off" 3 "DSR_in_Normal_Idle_Mode" 2 "EPAS_Comm_Disturbed" 1 "DSR_Request_Not_Applicable" 0 "DSR_Deactivated" ;
VAL_TABLE_ StrtrMtrCtlMsgTxt_D_Rq 7 "Start_In_Gear_Allowed" 6 "Pending_Start_Cancelled" 5 "Start_Pending_Please_Wait" 4 "Cranking_Limit_Exceeded" 3 "Press_Brk_and_Shift_to_P_N" 2 "Press_Clutch_and_Brake" 1 "Press_Clutch_To_Start" 0 "No_Display" ;
VAL_TABLE_ Null_Open 1 "Open" 0 "Null" ;
VAL_TABLE_ TempDegreesC_DegreesF 0 "Temperature_deg_c" 1 "Temperature_deg_f" ;
VAL_TABLE_ Invalid_DayNight 2 "Night" 1 "Day" 0 "Invalid" ;
VAL_TABLE_ Invalid_12h_24h 2 "24h_mode" 1 "12h_mode" 0 "Invalid" ;
VAL_TABLE_ Invalid_Theme1_2 2 "Theme_2" 1 "Theme_1" 0 "Invalid" ;
VAL_TABLE_ LanguageSelect_St 33 "Ukrainian" 32 "Indian_English" 31 "Thai" 30 "Slovak" 29 "Arabic" 28 "Taiwanese" 27 "Mandarin_Chinese" 26 "Korean" 25 "AU_English" 24 "Japanese" 23 "Braz_Portuguese" 22 "EU_Portuguese" 21 "Finish" 20 "Norwegian" 19 "Danish" 18 "Swedish" 17 "Hungarian" 16 "Greek" 15 "Czech" 14 "Polish" 13 "Flemish" 12 "Dutch" 11 "Russian" 10 "Turkish" 9 "Mex_Spanish" 8 "EU_Spanish" 7 "Cana_French" 6 "EU_French" 5 "Italian" 4 "German" 3 "NA_English" 2 "UK_English" 1 "Unknown" 0 "Invalid" ;
VAL_TABLE_ HeadLghtHiFdbck_D_Stat 3 "NotUsed" 2 "Cancel" 1 "Hold" 0 "Allow_Change" ;
VAL_TABLE_ Backlit_LED_Status 15 "Unused3" 14 "Unused2" 13 "Unused1" 12 "Night_12" 11 "Night_11" 10 "Night_10" 9 "Night_9" 8 "Night_8" 7 "Night_7" 6 "Night_6" 5 "Night_5" 4 "Night_4" 3 "Night_3" 2 "Night_2" 1 "Night_1" 0 "Off" ;
VAL_TABLE_ Veh_Lock_Status 3 "UNLOCK_DRV" 2 "UNLOCK_ALL" 1 "LOCK_ALL" 0 "LOCK_DBL" ;
VAL_TABLE_ PrkLckCtlMsgTxt_D_Rq 3 "BTSI_DI_3" 2 "BTSI_DI_2" 1 "BTSI_DI_1" 0 "Null_BTSI_DI" ;
VAL_TABLE_ NoShift_Shift 1 "Shift" 0 "NoShift" ;
VAL_TABLE_ CrashEvnt_D_Stat 3 "Invalid" 2 "Fuel_Cutoff_Event" 1 "Deploy_Event" 0 "No_Event" ;
VAL_TABLE_ ReducedGuard_D_Stat 3 "NotUsed" 2 "Alarm_On" 1 "Alarm_Off_Previously_On" 0 "Alarm_Off" ;
VAL_TABLE_ HvacPrecondBlwr_D_Rq 15 "NotUsed6" 14 "NotUsed5" 13 "NotUsed4" 12 "NotUsed3" 11 "NotUsed2" 10 "NotUsed1" 9 "Last_User_Setting" 8 "Auto" 7 "Speed7" 6 "Speed6" 5 "Speed5" 4 "Speed4" 3 "Speed3" 2 "Speed2" 1 "Speed1" 0 "Off" ;
VAL_TABLE_ HvacPrecondMode_D_Rq 15 "NotUsed4" 14 "NotUsed3" 13 "NotUsed2" 12 "Low_Blower_Auto" 11 "Last_User_Settings" 10 "Auto" 9 "Max_Defrost" 8 "Windshield_Panel_Floor" 7 "Windshield_Panel" 6 "Windshield" 5 "Windshield_Floor" 4 "Floor" 3 "Panel_Floor" 2 "Panel" 1 "MAX_AC" 0 "Off" ;
VAL_TABLE_ ButtonNotPressed 1 "Button_Pressed" 0 "Button_Not_Pressed" ;
VAL_TABLE_ FobComm_D_Stat 3 "NotUsed" 2 "RemEngStartOK" 1 "RemEngStartFail" 0 "Null" ;
VAL_TABLE_ PudLamp_D_Rq 3 "RAMP_DOWN" 2 "RAMP_UP" 1 "ON" 0 "OFF" ;
VAL_TABLE_ WndwGlbl_D_Cmd 7 "NotUsed3" 6 "NotUsed2" 5 "NotUsed1" 4 "GLEARN" 3 "GCLOSE" 2 "GOPEN" 1 "GSTOP" 0 "Null" ;
VAL_TABLE_ LockMsg 7 "MSG7" 6 "MSG6" 5 "MSG5" 4 "MSG4" 3 "MSG3" 2 "MSG2" 1 "MSG1" 0 "NO_WARNING" ;
VAL_TABLE_ ChildLockDisplay 3 "NOT_SUPPORTED" 2 "ERROR" 1 "CHILD_UNLOCK" 0 "CHILD_LOCK" ;
VAL_TABLE_ Null_Lock_Unlock 3 "NotUsed" 2 "Unlock" 1 "Lock" 0 "Null" ;
VAL_TABLE_ Wiper 15 "NO_DATA_EXISTS" 14 "STALLED" 13 "RESERVED" 12 "AUTO_ADJUST" 11 "COURTESYWIPE" 10 "AUTO_HIGH" 9 "AUTO_LOW" 8 "WASH" 7 "MIST_FLICK" 6 "MAN_HIGH" 5 "MAN_LOW" 4 "MAN_INT_ON" 3 "MAN_INT_OFF" 2 "OFF_MOVING" 1 "AUTO_OFF" 0 "OFF" ;
VAL_TABLE_ Turn_switch 3 "Unused_Treat_As_Off" 2 "Right" 1 "Left" 0 "Off" ;
VAL_TABLE_ PrkLght_D_Stat 3 "Park_Both" 2 "Park_Right" 1 "Park_Left" 0 "Off" ;
VAL_TABLE_ LghtAmb_D_Sns 7 "No_Data_Exists" 6 "Unused2" 5 "Unused1" 4 "Tunnel_Off" 3 "Tunnel_On" 2 "Twilight" 1 "Light" 0 "Dark" ;
VAL_TABLE_ HeadLghtSwtch_D_Stat 3 "Autolamp" 2 "Headlamp" 1 "Parklamp" 0 "Off" ;
VAL_TABLE_ EmgcyBrkLamp_D_Rq 3 "NotUsed" 2 "Active_at_standstill" 1 "Active_at_speed" 0 "Inactive" ;
VAL_TABLE_ OpenPressedFault 3 "Fault" 2 "Unused" 1 "Pressed" 0 "Open" ;
VAL_TABLE_ LifeCycMde_D_Actl 3 "Transport" 2 "NotUsed" 1 "Factory" 0 "Normal" ;
VAL_TABLE_ ClimtHeat_D_Rq 7 "NotUsed4" 6 "NotUsed3" 5 "HtrCoreClntFlwOnly" 4 "PtcHtrTestMde" 3 "Defrost_Defog" 2 "FastTempPullDownHeatingReq" 1 "OpportunisticHeatingReq" 0 "NoHeatingRequest" ;
VAL_TABLE_ NoData_Fault_3FE_3FF 1023 "Fault" 1022 "NoDataExists" ;
VAL_TABLE_ ClimtCool_D_Rq 7 "NotUsed4" 6 "NotUsed3" 5 "NotUsed2" 4 "ElACTestMde" 3 "Defrost_Defog" 2 "FastTempPullDownCoolReq" 1 "OpportunisticCoolingReq" 0 "NoCoolingRequest" ;
VAL_TABLE_ EngFuelCutFull_B_Inhbt 1 "Inhibit_DFSO" 0 "Normal" ;
VAL_TABLE_ VehStrtStop_D_Rq 3 "NotUsed" 2 "Vehicle_Start_Request" 1 "Vehicle_Stop_Request" 0 "NoRequest" ;
VAL_TABLE_ PrkBrkStatus 7 "GeneralFault_MaintenceMode" 6 "ECD_by_Brake_ECU_Active" 5 "EPB_Limphome_Active" 4 "Rear_Caliper_Open" 3 "RWU_By_EPB_Active" 2 "Rear_Caliper_Transition" 1 "Rear_Caliper_Closed" 0 "Not_Supported" ;
VAL_TABLE_ BattTracCool 3 "NotUsed" 2 "DCDC_Overtemperature" 1 "CoolingRequiredbyDCDC" 0 "NoCoolingRequiredbyDCDC" ;
VAL_TABLE_ Quality_Data 3 "OK" 2 "Not_Within_Specifications" 1 "Eval_In_Progress" 0 "Fault" ;
VAL_TABLE_ PwSrcULoFalt_D_Stat 3 "Fault_No_Output" 2 "Fault_Reduced_Output" 1 "Fault_NonSpecific" 0 "No_Fault" ;
VAL_TABLE_ Connect_Discon_Loose 1 "Loose_or_Disconnected" 0 "Connected" ;
VAL_TABLE_ DontCare_StartInhibit 1 "Start_Inhibit" 0 "Dont_Care" ;
VAL_TABLE_ BattULoChrg_D_Rq 3 "Low_Battery_Temperature" 2 "Charging_Requested" 1 "Chrg_Requested_HighCurrent" 0 "No_Request" ;
VAL_TABLE_ PwSysULoFalt_D_Stat 15 "Not_Used_6" 14 "LowBatterySOC" 13 "PSS_Shed2_Contin" 12 "Not_Used_4" 11 "Not_Used_3" 10 "Not_Used_2" 9 "BattMonitoringSensorFault" 8 "LowBattVoltDuringPwSrcOn" 7 "LowBatt2_PowerSaveMode" 6 "LowBatt1_Warning" 5 "Overvoltage" 4 "Fault_NoOutput" 3 "Fault_ReducedOutput" 2 "Fault_Nonspecific" 1 "Cluster_Proveout" 0 "No_Fault" ;
VAL_TABLE_ AccStopMde_D_Rq 3 "Stop_Mode_Active" 2 "EPBApplyOrBrakeReleaseWarn" 1 "Limit_Rolling_Speed" 0 "Stop_Mode_Not_Active" ;
VAL_TABLE_ Eng_D_Stat 3 "NotUsed" 2 "EngAutoStopped" 1 "EngOn" 0 "EngOff" ;
VAL_TABLE_ ElPw_D_Stat 7 "NotUsed_3" 6 "NotUsed_2" 5 "NotUsed_1" 4 "Fault_Limited" 3 "LV_Event_In_Progress" 2 "Not_Supported_Imminent" 1 "Supported" 0 "Not_Supported" ;
VAL_TABLE_ PwPckTq_D_Stat 3 "PwPckOn_TqAvailable" 2 "StartInPrgrss_TqNotAvail" 1 "PwPckOn_TqNotAvailable" 0 "PwPckOff_TqNotAvailable" ;
VAL_TABLE_ Fault_FF 255 "Fault" ;
VAL_TABLE_ PsngrFrntDetct_D_Actl 3 "Unknown" 2 "Empty" 0 "Faulty" 1 "Occupied" ;
VAL_TABLE_ Normal_Mode1_2 3 "Undefined" 2 "Mode2" 1 "Mode1" 0 "Normal_Mode" ;
VAL_TABLE_ Fault_3FF 1023 "Fault" ;
VAL_TABLE_ VedsEvnt_6 5 "Unused_3" 4 "Unused_2" 3 "Unused_1" 2 "NotBelted" 1 "Belted" 0 "NoEvent" 7 "Fault" 6 "NotSupported" ;
VAL_TABLE_ VedsEvnt_5 7 "Fault" 6 "NotSupported" 5 "Unused_3" 4 "Unused_2" 3 "Unused_1" 2 "ChildNotDetected" 1 "ChildDetected" 0 "NoEvent" ;
VAL_TABLE_ VedsEvnt_4 7 "Fault" 6 "NotSupported" 5 "Unused_3" 4 "Unused_2" 3 "Unused_1" 2 "NotDeployed" 1 "Deployed" 0 "NoEvent" ;
VAL_TABLE_ VedsEvnt_3 0 "NoEvent" 255 "Fault" 254 "NotSupported" ;
VAL_TABLE_ VedsEvnt_2 7 "Fault" 6 "NotSupported" 5 "Unused_3" 4 "Unused_2" 3 "Unused_1" 2 "Yes" 1 "No" 0 "NoEvent" ;
VAL_TABLE_ VedsEvnt_1 7 "Fault" 6 "NotSupported" 5 "Unused" 4 "Rolllover" 3 "Rear" 2 "Side" 1 "Frontal" 0 "NoEvent" ;
VAL_TABLE_ LockInhibit 1 "Inhibit" 0 "No_Inhibit" ;
VAL_TABLE_ DieslFuelBio_B_ActlDrv 1 "Biodiesel_User" 0 "Non_Biodiesel_User" ;
VAL_TABLE_ Invalid_FFF 4095 "Invalid" ;
VAL_TABLE_ Shed_Feature_Group_ID 16 "PtcHeater" 30 "NotUsed_7" 29 "NotUsed_6" 28 "NotUsed_5" 27 "NotUsed_4" 26 "NotUsed_3" 25 "NotUsed_2" 24 "NotUsed_1" 23 "Dcac" 22 "UpFitter_6" 21 "UpFitter_5" 20 "UpFitter_4" 19 "UpFitter_3" 18 "UpFitter_2" 17 "UpFitter_1" 14 "HtdMirr" 13 "HvacRearBlwr_Third" 12 "HvacRearBlwr_Second" 11 "HvacRearBlwr_First" 31 "All LSHED1 Features" 10 "Htd_Windscrn" 9 "SpltHtdBcklight_HtdMirr" 8 "HtdBcklight_HtdMirr" 7 "HtdCoolSeat_FrtDriver" 6 "HtdCoolSeat_FrtPass" 5 "HtdCoolSeat_RearPass" 4 "HtdCoolSeat_RearDriver" 3 "SmartTrlrTowBattCharge" 2 "Htd_StrWhl" 1 "Htd_Washer_Fluid" 0 "No_LSHED1_Features" 15 "Engine_Coolant_Fan" ;
VAL_TABLE_ CoolantFanStepAct 31 "Unused7" 30 "Unused6" 29 "Unused5" 28 "Unused4" 27 "Unused3" 26 "Unused2" 25 "Unused1" 23 "Step23" 22 "Step22" 21 "Step21" 20 "Step20" 19 "Step19" 18 "Step18" 17 "Step17" 16 "Step16" 15 "Step15" 14 "Step14" 13 "Step13" 12 "Step12" 11 "Step11" 10 "Step10" 9 "Step9" 8 "Step8" 7 "Step7" 6 "Step6" 5 "Step5" 4 "Step4" 3 "Step3" 2 "Step2" 1 "Step1" 24 "Max_Fan_Speed_Req" 0 "Fan_Cmd_Off" ;
VAL_TABLE_ Null_Cancel 1 "Cancel" 0 "Null" ;
VAL_TABLE_ Veh_Lock_Requestor 31 "Walk_Away_Locking" 30 "Remote_Park_Assist" 29 "DoorsOffToOn_Smart_Unlock" 28 "Rgtm_Shutlock_Switch" 27 "Boundary_Alert" 26 "Transit_Vehicle_Relock" 25 "Transit_Cargo_Relock" 24 "Transit_Ajar_Lock" 23 "Diagnostics" 22 "Console_Lock" 21 "Child_Lock" 20 "Double_Lock" 19 "Passive_Pasenger" 18 "Passive_Driver" 17 "Slam_Lock_Protect" 16 "SYNC" 15 "Passport" 14 "Passive_Smart_Unlock" 13 "Autorelock" 12 "RemoteStart" 0 "Null" 1 "Autolock" 11 "Smart_Unlock" 10 "Sliding_Door" 9 "Passive" 8 "Remote" 7 "Programming" 6 "Powerslide" 5 "Keypad" 4 "Key_Cylinder" 3 "Interior" 2 "Auto_Unlock" ;
VAL_TABLE_ EPAS_FAILURE 3 "SERVICE_POWER_STEERING_NOW" 2 "SERVICE_POWER_STEERING" 1 "POWER_STRG_ASSIST_FAULT" 0 "EPAS_OK_NO_MESSAGE" ;
VAL_TABLE_ Perimeter_Alarm_Mode 3 "Activated" 2 "Armed" 1 "Prearmed" 0 "Disarmed" ;
VAL_TABLE_ Invalid_FFFF 65535 "Invalid" ;
VAL_TABLE_ OilPressureWarning 1 "Low_Pressure_Lamp_On" 0 "Normal_Pressure_Lamp_Off" ;
VAL_TABLE_ MyKey_KeyTypeChangeReq 3 "Search_PE_BackupSlot" 2 "Clear_All_MyKeys" 1 "Request_New_MyKey" 0 "None" ;
VAL_TABLE_ MyKey_Key_Count 13 "Thirteen" 12 "Twelve" 11 "Eleven" 10 "Ten" 9 "Nine" 8 "Eight" 7 "Seven" 6 "Six" 5 "Five" 4 "Four" 3 "Three" 2 "Two" 1 "One" 0 "Zero" 15 "Invalid" 14 "Unlimited" ;
VAL_TABLE_ GearEngag_D_Actl 7 "Undefined" 6 "Fwd_Clutch_Fully_Engaged" 5 "Neutral_Idle" 4 "Disengaged_to_Neutral_Idle" 3 "Disengaged_to_Neutral_Park" 2 "Engagement_in_Progress" 1 "InitializeFwdClutchEngagmt" 0 "Park_Neutral" ;
VAL_TABLE_ Shed_Level_Req 7 "SHED3" 6 "Loads_On" 5 "SHED_ENG_OFF" 4 "SOON_ENG_OFF" 3 "SHED2_CONTIN" 2 "SHED2_TRANS" 1 "SHED1" 0 "NO_SHED" ;
VAL_TABLE_ BpedMove_D_Actl 3 "Unknown" 2 "DriverApplyingBrakePedal" 1 "NoAutonomousBrkPdlMovement" 0 "AutonomousBrkPedalMove" ;
VAL_TABLE_ ChargeMode 7 "Undefined_2" 6 "Undefined_1" 5 "Battery_Identify" 4 "Battery_Refresh" 3 "SlowRegenAllowNoDischarge" 2 "Fast_Regen_Allowed" 1 "Slow_Regen_Allowed" 0 "Conventional_Charging" ;
VAL_TABLE_ Unknown_FFFE_Invalid_FFFF 65535 "Invalid" 65534 "Unknown" ;
VAL_TABLE_ eCallNotification 3 "Not_Used" 2 "Active" 1 "Normal" 0 "Not_Supported" ;
VAL_TABLE_ SAPPAngleControlStat5 1 "StrgColTorqueExceed_EAROn" 0 "ExternalSigContentOKforEAC" ;
VAL_TABLE_ Closed_Open_Active_Fault 3 "Fault" 2 "Active" 1 "Open" 0 "Closed" ;
VAL_TABLE_ SAPPAngleControlStat2 1 "Rel_ExtSteeringAngleReqx" 0 "NoRel_ExtSteeringAngleReqx" ;
VAL_TABLE_ SAPPAngleControlStat3 1 "EARactiveNoReverseEngage" 0 "ExternalSigContentOKforEAC" ;
VAL_TABLE_ RstrnImpactEvntStatus 7 "Invalid" 6 "Not_Used_4" 5 "Threshold_2_Exceeded" 4 "Not_Used_3" 3 "Threshold_1_Exceeded" 2 "Not_Used_2" 1 "Not_Used_1" 0 "Normal" ;
VAL_TABLE_ EDRTriggerEvntSync 1 "Threshold_Exceeded" 0 "Normal" ;
VAL_TABLE_ HILL_DESC_MC 7 "Fault_Detected" 6 "Cooling_Down" 5 "Abort_Apply_Brakes" 4 "Active" 3 "Disabled" 2 "Enabled" 1 "Off_Road" 0 "Normal" ;
VAL_TABLE_ Closed_Ajar 1 "Ajar" 0 "Closed" ;
VAL_TABLE_ Quality_Factor 3 "OK" 2 "Not_Within_Specifications" 1 "No_Data_Exists" 0 "Faulty" ;
VAL_TABLE_ Null_Day_Night 3 "NotUsed" 2 "Night" 1 "Day" 0 "Null" ;
VAL_TABLE_ Null_Flash_High 3 "NotUsed" 2 "High" 1 "Flash_to_Pass" 0 "Null" ;
VAL_TABLE_ GearPos_D_Actl 15 "Unknown" 14 "Reverse" 13 "Undefined_5" 12 "Undefined_4" 11 "Undefined_3" 10 "Tenth" 9 "Ninth" 8 "Eighth" 7 "Seventh" 6 "Sixth" 5 "Fifth" 4 "Fourth" 3 "Third" 2 "Second" 1 "First" 0 "Neutral" ;
VAL_TABLE_ OffOn_SlowFast_Flash 3 "Fast_Flash" 2 "Slow_Flash" 1 "On" 0 "Off" ;
VAL_TABLE_ AngleReached 1 "RequestedAngleNotReached" 0 "RequestedAngleCanBeReached" ;
VAL_TABLE_ WhlDir 3 "Faulty" 2 "NoDataExists" 1 "Backward" 0 "Forward" ;
VAL_TABLE_ VehVLimStat_D_Actl 7 "Undefined_3" 6 "Undefined_2" 5 "Undefined_1" 4 "ASL_Fault_Condition" 3 "Active_and_Limiting" 2 "Active_but_Not_Limiting" 1 "Standby" 0 "Off" ;
VAL_TABLE_ Fault_NoFault 1 "Fault" 0 "No_Fault" ;
VAL_TABLE_ TerrMde_D_Actl 7 "Fail_Safe_Default" 6 "Dynamic_Mode" 5 "Rock_Crawl_Mode" 4 "Mud_Ruts_Mode" 3 "Sand_Mode" 2 "Undefined" 1 "Low_Mu_Mode" 0 "Special_Operating_Mode_Off" ;
VAL_TABLE_ TerrMdeChng_D_Rdy 7 "Fault" 6 "Undefined_2" 5 "Undefined_1" 4 "ModeUnavailDrInputRqd" 3 "SpOpModes_NotSupported" 2 "ModeUnavailDynamicCond" 1 "Module_In_Initialization" 0 "Mode_Change_Available" ;
VAL_TABLE_ Unknown_Fault_FFFE_FFFF 65535 "Fault" 65534 "Unknown" ;
VAL_TABLE_ Invalid_FFFFFF 16777215 "Invalid" ;
VAL_TABLE_ AutoParkSpdExitCond 1 "SpeedLimitExceededEAROn" 0 "ExternalSigContentOKforEAC" ;
VAL_TABLE_ EngOilLvlDsply_D_Rq 15 "EngOil_LevelSys_CheckFault" 14 "Reserved_2" 13 "Reserved_1" 12 "Conditions_Unsuitable" 11 "Dipstick_Below_Minimum" 10 "Dipstick_Above_Maximum" 9 "Dipstick_Minimum" 8 "Dipstick_12_5_MinMaxRange" 7 "Dipstick_25_MinMaxRange" 6 "Dipstick_37_5_MinMaxRange" 5 "Dipstick_50_MinMaxRange" 4 "Dipstick_62_5_MinMaxRange" 3 "Dipstick_75_MinMaxRange" 2 "Dipstick_87_5_MinMaxRange" 1 "Dipstick_Maximum_Displayed" 0 "No_Message" ;
VAL_TABLE_ HdcMde_D_Actl 7 "Fault" 6 "Temporarily_Unavailable" 5 "NotEnabled_WrongGearSel" 4 "NotEnabled_SpdLimitExceed" 3 "Active_Braking" 2 "Not_Active_Braking" 1 "Off" 0 "Undefined" ;
VAL_TABLE_ GearLvrPos_D_Actl 15 "Fault" 14 "Unknown_Position" 13 "Undefined_Treat_as__Fault" 12 "Undefined_Treat_as_Fault" 11 "sixth" 10 "fifth" 9 "fourth" 8 "third" 7 "second" 6 "first" 5 "Low" 4 "Sport_DriveSport" 3 "Drive" 2 "Neutral" 1 "Reverse" 0 "Park" ;
VAL_TABLE_ DrvHdcMsg_D_Rq 7 "Undefined" 6 "Speed_too_High" 5 "Temporarily_Unavailable" 4 "System_Fault" 3 "Select_Gear" 2 "Off" 1 "On" 0 "No_Message" ;
VAL_TABLE_ CcStat_D_Actl 7 "Undefined_2" 6 "Undefined_1" 5 "Active" 4 "Active_Que_Assist" 3 "Standby" 2 "Standby_Denied" 1 "Denied" 0 "Off" ;
VAL_TABLE_ BpedDrvAppl_D_Actl 3 "_Not_Allowed" 2 "Driver_Braking" 1 "Driver_Not_Braking" 0 "Not_Allowed" ;
VAL_TABLE_ AslIconDsply_D_Rq 3 "On_Passive_Overridden" 2 "On_Active" 1 "On_Passive" 0 "Off" ;
VAL_TABLE_ AccEngStat_D_Actl 7 "Undefined_2" 6 "Undefined_1" 5 "ACCSoonCancel_due_Low_Spd" 4 "Shift_Down_Recommendation" 3 "Shift_Up_Recommendation" 2 "ACCNotAllowedToBeActivated" 1 "ACCStandby_due_Auto_Cancel" 0 "Normal_Operation" ;
VAL_TABLE_ NotPressed_Pressed 1 "Pressed" 0 "Not_Pressed" ;
VAL_TABLE_ No_Crank_Req 1 "Crank_Request" 0 "No_Crank_Request" ;
VAL_TABLE_ DrvSlipCtlMde_D_Rq 3 "App_Specific_Off_Mode_3" 2 "App_Specific_Off_Mode_2" 1 "App_Specific_Off_Mode_1" 0 "Default_Mode" ;
VAL_TABLE_ Normal_AdaptiveCruise 1 "Adaptive_Cruise" 0 "Normal_Cruise" ;
VAL_TABLE_ Remote_Device_Feedback 7 "Unused3" 6 "Unused2" 5 "Unused1" 4 "Shutdown" 3 "Running" 2 "Starting" 1 "Acknowledge" 0 "Null" ;
VAL_TABLE_ TrnManShif_D_IndDrv 7 "Undefined_3" 6 "Undefined_2" 5 "Shift_to_Neutral" 4 "Downshift_Recommendation" 3 "Upshift_Warning" 2 "Upshift_Performance" 1 "Upshift_Fuel_Economy" 0 "No_Indication" ;
VAL_TABLE_ Unlock_Lock 1 "Locked" 0 "Unlock" ;
VAL_TABLE_ PE_BackupSlot_Status 3 "No_Valid_FOB_In_Slot" 2 "MyKey_FOB_In_Slot" 1 "Standard_FOB_In_Slot" 0 "Null" ;
VAL_TABLE_ Unknown_Fault_FFE_FFF 4095 "Fault" 4094 "Unknown" ;
VAL_TABLE_ Unknown_Fault_1FFE_1FFF 8191 "Fault" 8190 "Unknown" ;
VAL_TABLE_ TrnCnvtClu_D_Actl 3 "Transition_or_Micro_Slip" 2 "Lock_Up_Fixed" 1 "Lock_Up_Slip" 0 "No_Lock_Up" ;
VAL_TABLE_ InhibitNoinhibit 1 "Inhibit" 0 "No_Inibit" ;
VAL_TABLE_ DisableEnable 1 "Enable" 0 "Disable" ;
VAL_TABLE_ Litval_values 255 "Invalid" 254 "Unknown" 5 "Day" 4 "Twilight_4" 3 "Twilight_3" 2 "Twilight_2" 1 "Twilight_1" 0 "Night" ;
VAL_TABLE_ Dimming_Lvl 255 "Invalid" 254 "Unknown" 18 "Day_6" 17 "Day_5" 16 "Day_4" 15 "Day_3" 14 "Day_2" 13 "Day_1" 12 "Night_12" 11 "Night_11" 10 "Night_10" 9 "Night_9" 8 "Night_8" 7 "Night_7" 6 "Night_6" 5 "Night_5" 4 "Night_4" 3 "Night_3" 2 "Night_2" 1 "Night_1" 0 "Off" ;
VAL_TABLE_ NotOperating 1 "Operating" 0 "Not_Operating" ;
VAL_TABLE_ EngPtoMde_D_Actl 7 "Undefined" 6 "Split_Shaft_Stationary" 5 "Not_Used_2" 4 "PTO_Mobile" 3 "Not_Used_1" 2 "PTO_Stationary" 1 "BCP" 0 "Off" ;
VAL_TABLE_ ManRgen_D_Rq 3 "NotUsed2" 2 "NotUsed1" 1 "CustInitManExhFilterClean" 0 "No_Customer_Request" ;
VAL_TABLE_ Remote_Start_Status 3 "Invalid" 2 "Unknown" 1 "Remote" 0 "Null" ;
VAL_TABLE_ Lock_Subld 15 "Unused7" 14 "Unused6" 13 "Unused5" 12 "Unused4" 11 "Unused3" 10 "Unused2" 9 "Unused1" 8 "Customer_8" 7 "Customer_7" 6 "Customer_6" 5 "Customer_5" 4 "Customer_4" 3 "Customer_3" 2 "Customer_2" 1 "Customer_1" 0 "Null" ;
VAL_TABLE_ Brake_Fluid 3 "Invalid" 2 "Unknown" 1 "Low" 0 "OK" ;
VAL_TABLE_ Unknown_Invalid_FE_FF 255 "Invalid" 254 "Unknown" ;
VAL_TABLE_ Invalid_FF 255 "Invalid" ;
VAL_TABLE_ NotLow_Low 1 "Low" 0 "Not_Low" ;
VAL_TABLE_ Key_In_Ignition_Status 1 "In" 0 "Out" ;
VAL_TABLE_ Ignition_Status 0 "Unknown" 1 "Off" 15 "Invalid" 8 "Start" 4 "Run" 2 "Accessory" ;
VAL_TABLE_ Unknown_Fault_FE_FF 255 "Fault" 254 "Unknown" ;
VAL_TABLE_ Null_Active 1 "Active" 0 "Null" ;
VAL_TABLE_ HsaStat_D_Actl 7 "Faulty" 6 "FaultyWithDriverIndication" 5 "SlowRelease" 4 "FastRelease" 3 "ActiveBrakePedalReleased" 2 "ActiveBrakePedalPressed" 1 "FindingGradient" 0 "Inactive" ;
VAL_TABLE_ Off_Auto_Manual 3 "Undefined" 2 "Manual" 1 "Automatic" 0 "Off" ;
VAL_TABLE_ HsaStat_D_Dsply 7 "NotUsed3" 6 "NotUsed2" 5 "NotUsed1" 4 "NotAvailable" 3 "SlowReleaseWithChime" 2 "SlowReleaseWithoutChime" 1 "Active" 0 "Inactive" ;
VAL_TABLE_ PassRstrnInd_Req 3 "ABOnNotIllum_OffNotIllum" 2 "AirbagOnNot_Illum_OffIllum" 1 "AirbagOn_Illum_OffNotIllum" 0 "AirbagOn_Illum_Off_Illum" ;
VAL_TABLE_ DrvHdcWarnInfo_D_Rq 3 "Undefined" 2 "Lamp_On_Continuously" 1 "Lamp_Flashing" 0 "Lamp_Off_Continuously" ;
VAL_TABLE_ Off_On 1 "On" 0 "Off" ;
VAL_TABLE_ CcMde_D_Actl 7 "TapDownWaiting" 6 "TapUpWaiting" 5 "Resuming_Low" 4 "Resuming_High" 3 "Decelerating" 2 "Accelerating" 1 "Keeping_Speed" 0 "Not_Active" ;
VAL_TABLE_ InactiveActive 1 "Active" 0 "Inactive" ;
VAL_TABLE_ ManRgenTxt_D_RqDsply 7 "NotUsed3" 6 "NotUsed2" 5 "NotUsed1" 4 "Cleaning_Aborted_Stopped" 3 "Cleaning_Completed" 2 "Cleaning_In_Progress" 1 "Cleaning_Allowed" 0 "Cleaning_Not_Allowed" ;
VAL_TABLE_ Fault_FFFF 65535 "Fault" ;
VAL_TABLE_ Fault_7F 127 "Fault" ;
VAL_TABLE_ NoYes 1 "Yes" 0 "No" ;
VAL_TABLE_ AwdRnge_D_Actl 7 "Unknown" 6 "High_Range_2wd" 5 "High_Range_Auto" 4 "High_Range_Locked" 3 "Neutral" 2 "Low_Range_2wd" 1 "Low_Range_Auto" 0 "Low_Range_Locked" ;
VAL_TABLE_ Unknown_Fault_3FE_3FF 1023 "Fault" 1022 "Unknown" ;
VAL_TABLE_ Off_On_Flash 3 "Not_Used" 2 "Flash" 1 "On" 0 "Off" ;
VAL_TABLE_ BeltBuckle 3 "Unknown" 2 "Unbelted" 1 "Belted" 0 "Faulty" ;
VAL_TABLE_ RILReqCoding 3 "Not_Used" 2 "Plant_Mode" 1 "On" 0 "Off" ;
VAL_TABLE_ Tire_Pressure_Stat 4 "Alert" 15 "Not_Supported" 3 "Fault" 2 "Low" 1 "Normal" 0 "Unknown" ;
VAL_TABLE_ Tire_Pressure_System2 13 "Training_Complete" 12 "Train_InsideLeftRear_tire" 11 "Train_OutsideLeftRear_tire" 10 "Train_LeftRear_tire" 9 "Train_InsideRtRear_tire" 8 "Train_OutsideRtRear_tire" 7 "Train_RightRear_tire" 14 "Tires_not_trained" 6 "Train_RightFront_tire" 5 "Train_LeftFront_tire" 4 "Systm_Activ_Composite_Stat" 3 "Low_Composite_Stat" 2 "Sensr_Fault_Composite_Stat" 1 "Systm_Fault_Composite_Stat" 0 "Unknown_Composite_Stat" ;
VAL_TABLE_ Running_Board 3 "Unused" 2 "Manually_Deployed" 1 "All_Enabled" 0 "All_Disabled" ;
VAL_TABLE_ Turn_Seq 3 "Seq" 2 "On" 1 "Off" 0 "Null" ;
VAL_TABLE_ NotPark 1 "Park" 0 "Not_Park" ;
VAL_TABLE_ CCOverridden 1 "Cruise_Overridden" 0 "Cruise_Req_Not_Overridden" ;
VAL_TABLE_ Ign_Key_Device_Type 15 "Invalid" 14 "Unknown" 3 "Key_Not_Prgrm_Read_Failure" 2 "Key_In_Ign_My_Key" 1 "Key_In_Ign_Standard_Key" 0 "Key_Read_In_Progress" ;
VAL_TABLE_ Off_No_Eff_Unknown_Invalid 3 "Invalid" 2 "Unknown" 1 "No_Effect" 0 "Off" ;
VAL_TABLE_ Null_Out 1 "Out" 0 "Null" ;
VAL_TABLE_ FUEL_SENSORS 1 "Dual_Sensors" 0 "Single_Sensor" ;

BO_ 3221225472 VECTOR__INDEPENDENT_SIG_MSG: 0 Vector__XXX
 SG_ OTAPhysGWM_ECGtoWBCM : 0|29@0+ (1,0) [0|536870911] "unitless" Vector__XXX
 SG_ PARSEDPhysGWM_ECGtoWBCM : 0|29@0+ (1,0) [0|536870911] "unitless" Vector__XXX
 SG_ PARSEDPushFcGWM_ECGtoWBCM : 0|29@0+ (1,0) [0|536870911] "unitless" Vector__XXX
 SG_ OTAPhysGWM_ECGtoNFAM : 0|29@0+ (1,0) [0|536870911] "unitless" Vector__XXX
 SG_ PARSEDPhysGWM_ECGtoNFAM : 0|29@0+ (1,0) [0|536870911] "unitless" Vector__XXX
 SG_ PARSEDPushFcGWM_ECGtoNFAM : 0|29@0+ (1,0) [0|536870911] "unitless" Vector__XXX
 SG_ PARSEDPhysGWM_ECGtoRDAPM : 0|29@0+ (1,0) [0|536870911] "unitless" Vector__XXX
 SG_ PARSEDPhysGWM_ECGtoLDAPM : 0|29@0+ (1,0) [0|536870911] "unitless" Vector__XXX
 SG_ OTAPhysGWM_ECGtoLDAPM : 0|29@0+ (1,0) [0|536870911] "unitless" Vector__XXX
 SG_ OTAPhysGWM_ECGtoRDAPM : 0|29@0+ (1,0) [0|536870911] "unitless" Vector__XXX
 SG_ PARSEDPushFcGWM_ECGtoRDAPM : 0|29@0+ (1,0) [0|536870911] "unitless" Vector__XXX
 SG_ PARSEDPhysGWM_ECGtoTCUB : 0|29@0+ (1,0) [0|536870911] "unitless" Vector__XXX
 SG_ OTAPhysGWM_ECGtoTCUB : 0|29@0+ (1,0) [0|536870911] "unitless" Vector__XXX
 SG_ PARSEDPushFcGWM_ECGtoLDAPM : 0|29@0+ (1,0) [0|536870911] "unitless" Vector__XXX
 SG_ PARSEDPushFcGWM_ECGtoTCUB : 0|29@0+ (1,0) [0|536870911] "unitless" Vector__XXX
 SG_ SymKeyPhysGWM_ECGtoWBCM : 0|29@0+ (1,0) [0|536870911] "unitless" Vector__XXX
 SG_ SymKeyPhysGWM_ECGtoNFAM : 0|29@0+ (1,0) [0|536870911] "unitless" Vector__XXX
 SG_ SymKeyPhysGWM_ECGtoRDAPM : 0|29@0+ (1,0) [0|536870911] "unitless" Vector__XXX
 SG_ SymKeyPhysGWM_ECGtoLDAPM : 0|29@0+ (1,0) [0|536870911] "unitless" Vector__XXX
 SG_ SymKeyPhysGWM_ECGtoTCUB : 0|29@0+ (1,0) [0|536870911] "unitless" Vector__XXX
 SG_ EngMnfldChrg_Te_Actl : 0|7@0+ (1,-20) [-20|105] "degC" Vector__XXX
 SG_ EngInnrClnt_Te_Actl : 0|7@0+ (1,50) [50|175] "degC" Vector__XXX
 SG_ DcacOut2_Pw2_Dsply : 0|13@0+ (1,0) [0|8189] "watts" Vector__XXX
 SG_ DcacOut1_Pw2_Dsply : 0|13@0+ (1,0) [0|8189] "watts" Vector__XXX
 SG_ DcacFaltMsgTxt_D2_Rq : 0|6@0+ (1,0) [0|63] "SED" Vector__XXX
 SG_ ClimtCool_D_RqPt : 0|2@0+ (1,0) [0|3] "SED" Vector__XXX
 SG_ BtsiShifInhbt_B_RqPt : 0|1@0+ (1,0) [0|1] "SED" Vector__XXX
 SG_ TCU_RFA_WORD_Tx : 0|64@0+ (1,0) [0|1.84467440737096E+019] "unitless" Vector__XXX
 SG_ APIM_NFAM_Word_Tx : 0|64@0+ (1,0) [0|1.84467440737096E+019] "unitless" Vector__XXX
 SG_ ECG_NFAM_Word_Tx : 0|64@0+ (1,0) [0|1.84467440737096E+019] "unitless" Vector__XXX
 SG_ APIM_TCUB_Word_Tx : 0|64@0+ (1,0) [0|1.84467440737096E+019] "unitless" Vector__XXX
 SG_ ECG_MRCMB_Word_Tx : 0|64@0+ (1,0) [0|1.84467440737096E+019] "unitless" Vector__XXX
 SG_ ECG_MRCMA_Word_Tx : 0|64@0+ (1,0) [0|1.84467440737096E+019] "unitless" Vector__XXX
 SG_ AplPrimForUnload_D_Rq : 0|2@0+ (1,0) [0|3] "SED" Vector__XXX
 SG_ AplPrimForLoad_D_Rq : 0|2@0+ (1,0) [0|3] "SED" Vector__XXX
 SG_ AplReas_D_Stat : 0|2@0+ (1,0) [0|3] "SED" Vector__XXX
 SG_ AplHelpButtn_D_Stat : 0|2@0+ (1,0) [0|3] "SED" Vector__XXX
 SG_ AplReas_No_Actl : 0|64@0+ (1,0) [0|1.84467440737096E+019] "unitless" Vector__XXX
 SG_ AprForNextOrder_D_Rq : 0|2@0+ (1,0) [0|3] "SED" Vector__XXX

BO_ 926 UtcDateTime: 8 GWM
 SG_ UtcDateTZone_No_Actl : 7|64@0+ (1,0) [0|1.84467440737096E+019] "unitless"  RFA_BLEM

BO_ 581 TRAFFIC_RDISP_WORD_Tx: 8 TCU
 SG_ TRAFFIC_RDISP_WORD_Tx : 7|64@0+ (1,0) [0|1.84467440737096E+019] "unitless"  GENERIC,GWM

BO_ 1088 PreCond_Hev_Data1_FD2: 16 GWM
 SG_ TrlrRngId_No_Dsply : 3|4@0+ (1,0) [0|15] "unitless"  GENERIC
 SG_ ChrgStat_D2_Dsply : 7|4@0+ (1,0) [0|15] "SED"  GENERIC,TCU
 SG_ BattDcChrgRms_I_Lim : 15|15@0+ (0.05,0) [0|1638.35] "ampere"  GENERIC
 SG_ TrlrRng_L_Dsply : 31|13@0+ (0.1,0) [0|819.1] "kilometer"  GENERIC
 SG_ HvacPrecond_Te_Rq : 44|5@0+ (0.5,14.5) [14.5|30] "degC"  GENERIC
 SG_ HvacPrecondMode2_D_Rq : 51|4@0+ (1,0) [0|15] "SED"  GENERIC
 SG_ BattChrgInhbt_D_Rq : 53|2@0+ (1,0) [0|3] "SED"  GENERIC
 SG_ ChrgTMatch_B_Stat : 55|1@0+ (1,0) [0|1] "SED"  GENERIC
 SG_ HvacPrecondAC_D_Rq : 57|2@0+ (1,0) [0|3] "SED"  GENERIC
 SG_ HvacPrecondBlwr2_D_Rq : 61|4@0+ (1,0) [0|15] "SED"  GENERIC
 SG_ HvacPrecondRecirc_D_Rq : 63|2@0+ (1,0) [0|3] "SED"  GENERIC

BO_ 954 Body_Info_10_FD2: 16 GWM
 SG_ ExtLght_D_Falt : 1|2@0+ (1,0) [0|3] "SED"  GENERIC
 SG_ GenericSwtch2_No_Actl : 4|3@0+ (1,0) [0|7] "unitless"  GENERIC
 SG_ GenericSwtch1_No_Actl : 7|3@0+ (1,0) [0|7] "unitless"  GENERIC
 SG_ ExtLghtLeft_D_Stat : 9|2@0+ (1,0) [0|3] "SED"  GENERIC
 SG_ ExtLghtFront_D_Stat : 11|2@0+ (1,0) [0|3] "SED"  GENERIC
 SG_ ExtLghtAlrt_B_Rq : 12|1@0+ (1,0) [0|1] "SED"  GENERIC
 SG_ GenericSwtch3_No_Actl : 15|3@0+ (1,0) [0|7] "unitless"  GENERIC
 SG_ PudSptLghtRight_D_Rq : 17|2@0+ (1,0) [0|3] "SED"  GENERIC
 SG_ PudSptLghtLeft_D_Rq : 19|2@0+ (1,0) [0|3] "SED"  GENERIC
 SG_ ExtLghtRight_D_Stat : 21|2@0+ (1,0) [0|3] "SED"  GENERIC
 SG_ ExtLghtRear_D_Stat : 23|2@0+ (1,0) [0|3] "SED"  GENERIC
 SG_ TrukBedLght_B_Stat : 24|1@0+ (1,0) [0|1] "SED"  GENERIC
 SG_ TrlrHitchLamp_D_Stat : 25|1@0+ (1,0) [0|1] "SED"  GENERIC
 SG_ LicPlateLght_B_Stat : 26|1@0+ (1,0) [0|1] "SED"  GENERIC
 SG_ VehWlcmFrwlMde_D_Stat : 29|3@0+ (1,0) [0|7] "SED"  GENERIC
 SG_ VehWlcmFrwl_D_Stat : 31|2@0+ (1,0) [0|3] "SED"  GENERIC
 SG_ TlghtTest_D_Stat : 33|2@0+ (1,0) [0|3] "SED"  GENERIC
 SG_ LghtAmbDrvMde_B_Stat : 34|1@0+ (1,0) [0|1] "SED"  GENERIC
 SG_ PwRnngBoardPoll_D_Stat : 36|2@0+ (1,0) [0|3] "SED"  GENERIC
 SG_ PoliceDmngLvl_D_Stat : 39|3@0+ (1,0) [0|7] "SED"  GENERIC,TCU
 SG_ LoadShedRelay_B_Rq : 40|1@0+ (1,0) [0|1] "SED"  GENERIC
 SG_ KeylessIdl_B_Stat : 41|1@0+ (1,0) [0|1] "SED"  GENERIC
 SG_ TlghtTestLght_D_Stat : 44|3@0+ (1,0) [0|7] "SED"  GENERIC
 SG_ TlghtTestPrecnd_D_Stat : 47|3@0+ (1,0) [0|7] "SED"  GENERIC
 SG_ PosLghtFr_D_Stat : 49|2@0+ (1,0) [0|3] "SED"  GENERIC
 SG_ PosLghtFl_D_Stat : 51|2@0+ (1,0) [0|3] "SED"  GENERIC
 SG_ LoadShedRelayMde_D_Stat : 53|2@0+ (1,0) [0|3] "SED"  GENERIC
 SG_ CargoLght_D_Stat : 55|2@0+ (1,0) [0|3] "SED"  GENERIC
 SG_ TrlrHitchLamp_D2_Stat : 57|2@0+ (1,0) [0|3] "SED"  GENERIC
 SG_ ChildLckMaint_D_Stat : 59|2@0+ (1,0) [0|3] "SED"  GENERIC
 SG_ ExtLghtFront_D_RqBody : 61|2@0+ (1,0) [0|3] "SED"  GENERIC
 SG_ CrtsyLghtRear_D_Stat : 63|2@0+ (1,0) [0|3] "SED"  GENERIC

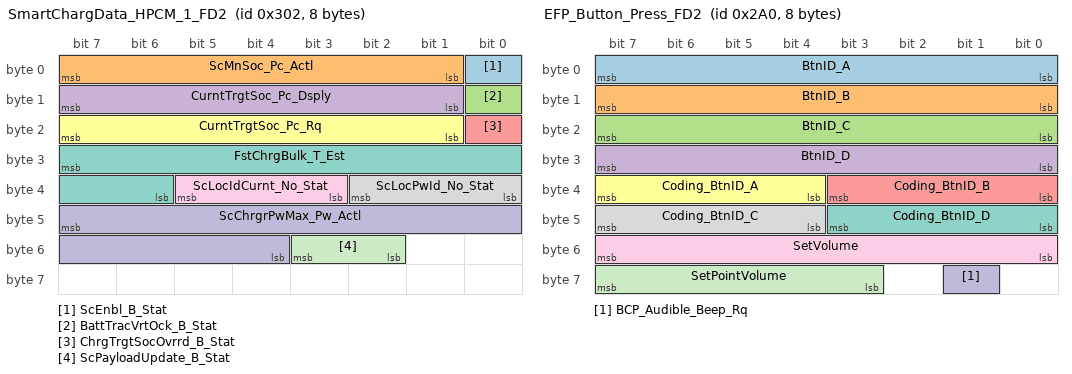
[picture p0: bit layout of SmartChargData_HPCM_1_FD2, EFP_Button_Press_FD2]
BO_ 770 SmartChargData_HPCM_1_FD2: 8 GWM
 SG_ ScEnbl_B_Stat : 0|1@0+ (1,0) [0|1] "SED"  GENERIC
 SG_ ScMnSoc_Pc_Actl : 7|7@0+ (1,0) [0|127] "percent"  GENERIC
 SG_ BattTracVrtOck_B_Stat : 8|1@0+ (1,0) [0|1] "SED"  GENERIC
 SG_ CurntTrgtSoc_Pc_Dsply : 15|7@0+ (1,0) [0|127] "percent"  GENERIC
 SG_ ChrgTrgtSocOvrrd_B_Stat : 16|1@0+ (1,0) [0|1] "SED"  GENERIC
 SG_ CurntTrgtSoc_Pc_Rq : 23|7@0+ (1,0) [0|127] "percent"  GENERIC
 SG_ FstChrgBulk_T_Est : 31|10@0+ (1,0) [0|1023] "minute"  GENERIC,TCU
 SG_ ScLocPwId_No_Stat : 34|3@0+ (1,0) [0|7] "unitless"  GENERIC
 SG_ ScLocIdCurnt_No_Stat : 37|3@0+ (1,0) [0|7] "unitless"  GENERIC
 SG_ ScChrgrPwMax_Pw_Actl : 47|12@0+ (50,0) [0|204700] "watts"  GENERIC
 SG_ ScPayloadUpdate_B_Stat : 51|2@0+ (1,0) [0|3] "SED"  GENERIC

BO_ 672 EFP_Button_Press_FD2: 8 GWM
 SG_ BtnID_A : 7|8@0+ (1,0) [0|255] "unitless"  GENERIC
 SG_ BtnID_B : 15|8@0+ (1,0) [0|255] "unitless"  GENERIC
 SG_ BtnID_C : 23|8@0+ (1,0) [0|255] "unitless"  GENERIC
 SG_ BtnID_D : 31|8@0+ (1,0) [0|255] "unitless"  GENERIC
 SG_ Coding_BtnID_B : 35|4@0+ (1,0) [0|15] "SED"  GENERIC
 SG_ Coding_BtnID_A : 39|4@0+ (1,0) [0|15] "SED"  GENERIC
 SG_ Coding_BtnID_D : 43|4@0+ (1,0) [0|15] "SED"  GENERIC
 SG_ Coding_BtnID_C : 47|4@0+ (1,0) [0|15] "SED"  GENERIC
 SG_ SetVolume : 55|8@0+ (1,-30) [-30|30] "unitless"  GENERIC,TCU
 SG_ BCP_Audible_Beep_Rq : 57|1@0+ (1,0) [0|1] "SED"  GENERIC
 SG_ SetPointVolume : 63|5@0+ (1,0) [0|31] "unitless"  GENERIC

BO_ 591 RFA_TCU_WORD_Tx: 8 RFA_BLEM
 SG_ RFA_TCU_WORD_Tx : 7|64@0+ (1,0) [0|1.84467440737096E+019] "unitless"  GENERIC,TCU

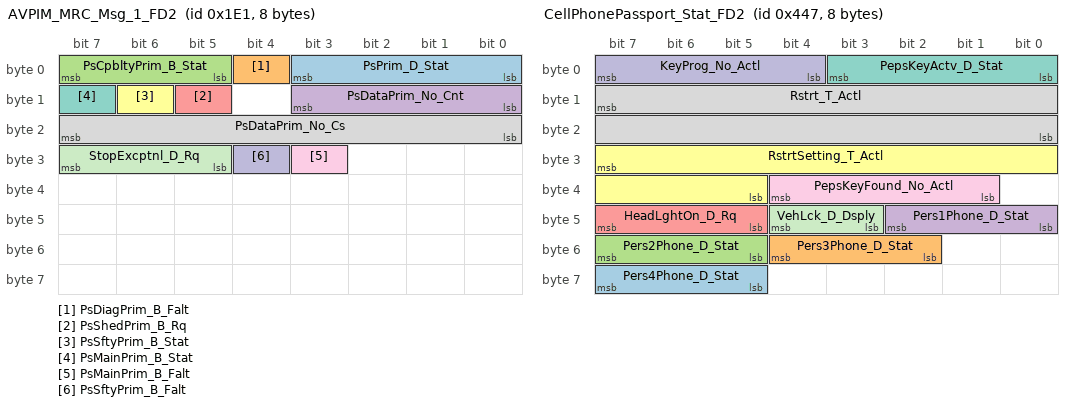
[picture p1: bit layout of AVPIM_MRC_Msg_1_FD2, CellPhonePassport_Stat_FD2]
BO_ 481 AVPIM_MRC_Msg_1_FD2: 8 GWM
 SG_ PsPrim_D_Stat : 3|4@0+ (1,0) [0|15] "SED"  GENERIC
 SG_ PsDiagPrim_B_Falt : 4|1@0+ (1,0) [0|1] "SED"  GENERIC
 SG_ PsCpbltyPrim_B_Stat : 7|3@0+ (1,0) [0|7] "SED"  GENERIC
 SG_ PsDataPrim_No_Cnt : 11|4@0+ (1,0) [0|15] "unitless"  GENERIC
 SG_ PsShedPrim_B_Rq : 13|1@0+ (1,0) [0|1] "SED"  GENERIC
 SG_ PsSftyPrim_B_Stat : 14|1@0+ (1,0) [0|1] "SED"  GENERIC
 SG_ PsMainPrim_B_Stat : 15|1@0+ (1,0) [0|1] "SED"  GENERIC
 SG_ PsDataPrim_No_Cs : 23|8@0+ (1,0) [0|255] "unitless"  GENERIC
 SG_ PsMainPrim_B_Falt : 27|1@0+ (1,0) [0|1] "SED"  GENERIC
 SG_ PsSftyPrim_B_Falt : 28|1@0+ (1,0) [0|1] "SED"  GENERIC
 SG_ StopExcptnl_D_Rq : 31|3@0+ (1,0) [0|7] "SED"  GENERIC,TCU

BO_ 388 HEV_Powertrain_Data10_FD2: 8 GWM
 SG_ BattDchrg_E_ActlMntr : 7|15@0+ (0.1,-999.9) [-999.9|-672.25] "kilowatt"  GENERIC,TCU
 SG_ BattFdbck_E_ActlMntr : 23|14@0+ (0.1,-999.9) [-999.9|-836.09] "kilowatt"  GENERIC,TCU

BO_ 909 Body_Info_6_FD2: 16 GWM
 SG_ IgnPsswrdDsply_B_Rq : 57|1@0+ (1,0) [0|1] "SED"  GENERIC
 SG_ ElPwPoint_D_Rq : 59|2@0+ (1,0) [0|3] "SED"  GENERIC
 SG_ PoliceIdlMde_D_Stat : 55|4@0+ (1,0) [0|15] "SED"  GENERIC,_delete
 SG_ DrLatchMsgTxt_D_Rq : 43|3@0+ (1,0) [0|7] "SED"  GENERIC
 SG_ HazrdLght_B_Stat : 56|1@0+ (1,0) [0|1] "SED"  GENERIC
 SG_ WiprFront_D_Stat2 : 63|4@0+ (1,0) [0|15] "SED"  GENERIC
 SG_ SecurityMsgTxt_D_Rq : 47|2@0+ (1,0) [0|3] "SED"  GENERIC
 SG_ PrmtrAlrmEvnt_D_Stat : 35|4@0+ (1,0) [0|15] "SED"  GENERIC
 SG_ TurnLghtSwtch_D_Stat2 : 49|2@0+ (1,0) [0|3] "SED"  GENERIC
 SG_ HeadLghtHiPrmsn_D_Stat : 51|2@0+ (1,0) [0|3] "SED"  GENERIC
 SG_ SteWhlLckMsgTxt_D_Rq : 25|2@0+ (1,0) [0|3] "SED"  GENERIC
 SG_ immoMsgTxt_D_Rq : 39|4@0+ (1,0) [0|15] "SED"  GENERIC
 SG_ PrsnlDevcChrgEnbl_B_Rq : 40|1@0+ (1,0) [0|1] "SED"  GENERIC
 SG_ TracKeyMde_D_Stat : 45|2@0+ (1,0) [0|3] "SED"  GENERIC
 SG_ PEBackupSlot_Stats : 27|2@0+ (1,0) [0|3] "SED"  GENERIC
 SG_ KeyMykeyTot_No_Cnt : 3|4@0+ (1,0) [0|15] "Counts"  GENERIC
 SG_ Keycode_Status : 15|20@0+ (1,0) [0|1048575] "unitless"  GENERIC
 SG_ KeyAdmnTot_No_Cnt : 7|4@0+ (1,0) [0|15] "Counts"  GENERIC

BO_ 949 Tire_Pressure_Data_FD2: 16 GWM
 SG_ Tire_Press_RR_ORR_Data : 39|16@0+ (1,0) [0|65533] "kilopascal"  GENERIC,_delete
 SG_ Tire_Press_LR_OLR_Data : 55|16@0+ (1,0) [0|65533] "kilopascal"  GENERIC,_delete
 SG_ Tire_Press_LF_Data : 7|16@0+ (1,0) [0|65533] "kilopascal"  GENERIC,_delete
 SG_ Tire_Press_RF_Data : 23|16@0+ (1,0) [0|65533] "kilopascal"  GENERIC,_delete

BO_ 952 Tire_Pressure_Data_DRW_FD2: 8 GWM
 SG_ Tire_Press_IRR_Data : 23|16@0+ (1,0) [0|65533] "kilopascal"  GENERIC,_delete
 SG_ Tire_Press_ILR_Data : 7|16@0+ (1,0) [0|65533] "kilopascal"  GENERIC,_delete

BO_ 1044 BrakeSnData_6_FD2: 16 GWM
 SG_ ApaBrkErrDStat_No_Cnt : 55|4@0+ (1,0) [0|15] "Unitless"  GENERIC,_delete,RFA_BLEM
 SG_ ApaBrkErrDStat_No_Cs : 47|8@0+ (1,0) [0|255] "Unitless"  GENERIC,_delete,RFA_BLEM
 SG_ ApaBrkErr_D_Stat : 17|2@0+ (1,0) [0|3] "SED"  GENERIC,_delete,RFA_BLEM
 SG_ StePinOffst_An_Est : 7|16@0+ (0.1,-3200) [-3200|3353.3] "degrees"  GENERIC
 SG_ StePinOffst_No_Cs : 31|8@0+ (1,0) [0|255] "unitless"  GENERIC
 SG_ StePinOffst_No_Cnt : 21|4@0+ (1,0) [0|15] "unitless"  GENERIC
 SG_ StePinOffst_D_Stat : 23|2@0+ (1,0) [0|3] "SED"  GENERIC
 SG_ PrplBrkTqAsst_Pw_Rq : 39|8@0+ (100,0) [0|25500] "watts"  GENERIC

BO_ 1095 CellPhonePassport_Stat_FD2: 8 GWM
 SG_ Pers4Phone_D_Stat : 63|3@0+ (1,0) [0|7] "SED"  GENERIC
 SG_ Pers3Phone_D_Stat : 52|3@0+ (1,0) [0|7] "SED"  GENERIC
 SG_ Pers2Phone_D_Stat : 55|3@0+ (1,0) [0|7] "SED"  GENERIC
 SG_ Pers1Phone_D_Stat : 42|3@0+ (1,0) [0|7] "SED"  GENERIC
 SG_ HeadLghtOn_D_Rq : 47|3@0+ (1,0) [0|7] "SED"  GENERIC
 SG_ RstrtSetting_T_Actl : 31|11@0+ (1,0) [0|2047] "second"  GENERIC
 SG_ PepsKeyActv_D_Stat : 3|4@0+ (1,0) [0|15] "SED"  GENERIC
 SG_ Rstrt_T_Actl : 15|16@0+ (1,0) [0|65535] "seconds"  GENERIC
 SG_ PepsKeyFound_No_Actl : 36|4@0+ (1,0) [0|15] "unitless"  GENERIC
 SG_ KeyProg_No_Actl : 7|4@0+ (1,0) [0|15] "unitless"  GENERIC
 SG_ VehLck_D_Dsply : 44|2@0+ (1,0) [0|3] "SED"  GENERIC

BO_ 1076 Cluster_Info_3_FD3: 8 GWM
 SG_ IpcGearDsplyRdy_B_Stat : 36|1@0+ (1,0) [0|1] "SED"  GENERIC
 SG_ FogLghtRearButtn_B_Rq : 3|1@0+ (1,0) [0|1] "SED"  GENERIC
 SG_ FogLghtFrontButtn_B_Rq : 4|1@0+ (1,0) [0|1] "SED"  GENERIC
 SG_ AutoRgen_D_Rq : 34|2@0+ (1,0) [0|3] "SED"  GENERIC
 SG_ W2S_LAMP_OK : 37|1@0+ (1,0) [0|1] "SED"  GENERIC
 SG_ OdoTripRx_B_Actl : 2|1@0+ (1,0) [0|1] "SED"  GENERIC
 SG_ Veh_V_CompLimMx : 47|12@0+ (0.1,0) [0|409.5] "km/h"  GENERIC
 SG_ DrvSlipCtlMde_B_RqMyKey : 38|1@0+ (1,0) [0|1] "SED"  GENERIC
 SG_ FuelLvlWarn_D_Actl : 51|2@0+ (1,0) [0|3] "SED"  GENERIC
 SG_ DieslFuelBio_B_ActlDrv : 19|1@0+ (1,0) [0|1] "SED"  GENERIC
 SG_ FuelSecndActv_B_Actl : 39|1@0+ (1,0) [0|1] "SED"  GENERIC
 SG_ HILL_DESC_SW : 32|1@0+ (1,0) [0|1] "SED"  GENERIC
 SG_ FuelLvlPssvSide_No_Raw : 17|10@0+ (1,0) [0|1023] "unitless"  GENERIC
 SG_ FUEL_SENSOR_NUM : 35|1@0+ (1,0) [0|1] "SED"  GENERIC
 SG_ FuelLvlActvSide_No_Raw : 49|10@0+ (1,0) [0|1023] "unitless"  GENERIC
 SG_ FuelLvl_Pc_Dsply : 1|10@0+ (0.108696,-5.217408) [-5.217408|105.9786] "Percent"  GENERIC
 SG_ DISPLAY_SPEED_SCALING : 23|4@0+ (0.5,100) [100|107.5] "%"  GENERIC
 SG_ TirePReset_B_Rq : 18|1@0+ (1,0) [0|1] "SED"  GENERIC
 SG_ DISPLAY_SPEED_OFFSET : 7|3@0+ (0.5,0) [0|3.5] "kph"  GENERIC

BO_ 1071 Engine_Clutch_Data_FD2: 16 GWM
 SG_ EngAout_N_Dsply : 52|13@0+ (2,0) [0|16382] "rpm"  GENERIC
 SG_ EngMnfld3_P_Actl : 47|8@0+ (10,0) [0|2530] "milibar"  GENERIC
 SG_ CluPdl_PcRate_Actl : 7|8@0+ (0.04,-5) [-5|5.2] "%/ms"  GENERIC
 SG_ CluPdlPosPcMeas_D_Qf : 11|2@0+ (1,0) [0|3] "SED"  GENERIC
 SG_ CluPdlPos_Pc_Meas : 9|10@0+ (0.1,0) [0|102.3] "%"  GENERIC
 SG_ EngAoutIdl_N_Ntrl : 31|11@0+ (2,0) [0|4094] "rpm"  GENERIC

BO_ 1057 PowertrainData_1_FD2: 16 GWM
 SG_ FohEng_D_Rq : 1|2@0+ (1,0) [0|3] "SED"  GENERIC
 SG_ EngIdlShutDwnTxt_D_Rq : 17|2@0+ (1,0) [0|3] "SED"  GENERIC
 SG_ EngIdlShutDown_D_Stat : 9|2@0+ (1,0) [0|3] "SED"  GENERIC
 SG_ FUEL_ALCOHOL_PERCNT : 63|8@0+ (0.393700787,0) [0|99.999899898] "percent"  GENERIC
 SG_ TrnTotTq_Rt_Est : 39|16@0+ (0.001,0) [0|65.533] "unitless"  GENERIC
 SG_ TrnTotLss_Tq_Est : 31|8@0+ (0.5,0) [0|126.5] "Nm"  GENERIC
 SG_ ECMMILRequest : 3|2@0+ (1,0) [0|3] "SED"  GENERIC
 SG_ AirCondFluidHi_P_Actl : 55|8@0+ (0.125,0) [0|31.625] "bar"  GENERIC
 SG_ OilPressureWarning : 18|1@0+ (1,0) [0|1] "SED"  GENERIC
 SG_ VehVLimStat_D_Actl : 6|3@0+ (1,0) [0|7] "SED"  GENERIC
 SG_ VehVLimActv_B_Actl : 7|1@0+ (1,0) [0|1] "SED"  GENERIC
 SG_ CoolantFanStepAct : 23|5@0+ (1,0) [0|31] "Steps"  GENERIC

BO_ 870 Cluster_HEV_Data3_FD2: 16 GWM
 SG_ PolicePurstMde_B_Stat : 0|1@0+ (1,0) [0|1] "SED"  GENERIC
 SG_ RngPerChrgInst_L_Dsply : 45|12@0+ (0.1,0) [0|409.3] "km"  GENERIC
 SG_ ChkPlgtoStrt_D_Dsply : 7|2@0+ (1,0) [0|3] "SED"  GENERIC
 SG_ ElFuelFlw_Vl_Dsply : 49|10@0+ (25,0) [0|25575] "micro-litre"  GENERIC
 SG_ HybMdeLimMsgTxt_D_Rq : 5|2@0+ (1,0) [0|3] "SED"  GENERIC
 SG_ HybMdeMsgTxt_D2_Rq : 31|4@0+ (1,0) [0|15] "SED"  GENERIC
 SG_ EngMdeMsgTxt_D_Rq : 12|3@0+ (1,0) [0|7] "SED"  GENERIC
 SG_ BattPwWhl_Pc_Dsply : 39|10@0+ (0.1,0) [0|102.3] "percent"  GENERIC
 SG_ EffRgenThres_Pc_Dsply : 9|10@0+ (0.1,-102.3) [-102.3|1023] "percent"  GENERIC
 SG_ ShifOutNtrlMsgTxt_D_Rq : 15|3@0+ (1,0) [0|7] "SED"  GENERIC

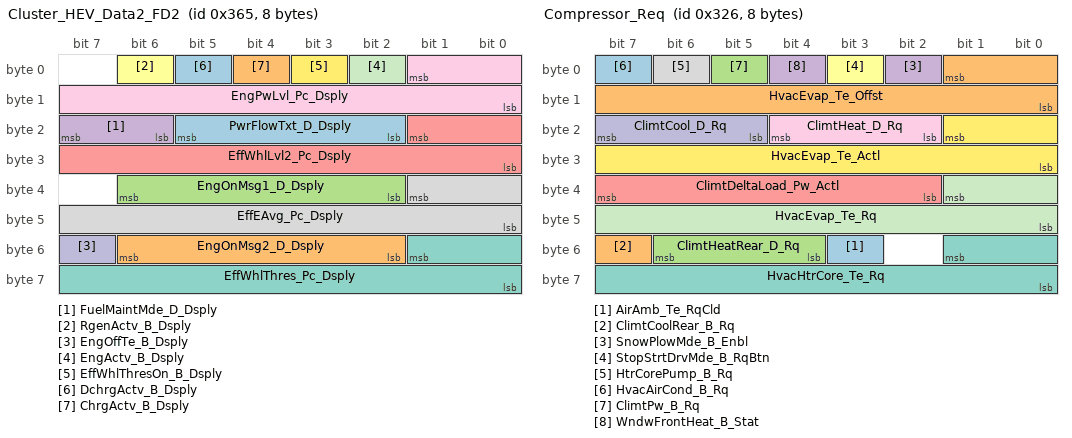
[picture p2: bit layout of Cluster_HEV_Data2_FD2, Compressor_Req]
BO_ 869 Cluster_HEV_Data2_FD2: 8 GWM
 SG_ PwrFlowTxt_D_Dsply : 21|4@0+ (1,0) [0|15] "SED"  GENERIC
 SG_ EngOnMsg2_D_Dsply : 54|5@0+ (1,0) [0|31] "SED"  GENERIC
 SG_ EngOnMsg1_D_Dsply : 38|5@0+ (1,0) [0|31] "SED"  GENERIC
 SG_ FuelMaintMde_D_Dsply : 23|2@0+ (1,0) [0|3] "SED"  GENERIC
 SG_ EffWhlLvl2_Pc_Dsply : 17|10@0+ (0.2,-102.2) [-102.2|102.4] "percent"  GENERIC
 SG_ RgenActv_B_Dsply : 6|1@0+ (1,0) [0|1] "SED"  GENERIC
 SG_ EffWhlThres_Pc_Dsply : 49|10@0+ (0.1,0) [0|102.3] "percent"  GENERIC
 SG_ EffEAvg_Pc_Dsply : 33|10@0+ (0.1,0) [0|102.3] "percent"  GENERIC
 SG_ EngPwLvl_Pc_Dsply : 1|10@0+ (0.1,0) [0|102.3] "percent"  GENERIC
 SG_ EngOffTe_B_Dsply : 55|1@0+ (1,0) [0|1] "SED"  GENERIC
 SG_ EngActv_B_Dsply : 2|1@0+ (1,0) [0|1] "SED"  GENERIC
 SG_ EffWhlThresOn_B_Dsply : 3|1@0+ (1,0) [0|1] "SED"  GENERIC
 SG_ DchrgActv_B_Dsply : 5|1@0+ (1,0) [0|1] "SED"  GENERIC
 SG_ ChrgActv_B_Dsply : 4|1@0+ (1,0) [0|1] "SED"  GENERIC

BO_ 806 Compressor_Req: 8 GWM
 SG_ AirAmb_Te_RqCld : 51|1@0+ (1,0) [0|1] "SED"  GENERIC
 SG_ ClimtCoolRear_B_Rq : 55|1@0+ (1,0) [0|1] "SED"  GENERIC
 SG_ ClimtHeatRear_D_Rq : 54|3@0+ (1,0) [0|7] "SED"  GENERIC
 SG_ SnowPlowMde_B_Enbl : 2|1@0+ (1,0) [0|1] "SED"  GENERIC
 SG_ ClimtDeltaLoad_Pw_Actl : 39|6@0+ (50,-1600) [-1600|1450] "watts"  GENERIC
 SG_ StopStrtDrvMde_B_RqBtn : 3|1@0+ (1,0) [0|1] "SED"  GENERIC
 SG_ HvacHtrCore_Te_Rq : 49|10@0+ (0.25,-50) [-50|205.75] "degC"  GENERIC
 SG_ HtrCorePump_B_Rq : 6|1@0+ (1,0) [0|1] "SED"  GENERIC
 SG_ ClimtHeat_D_Rq : 20|3@0+ (1,0) [0|7] "SED"  GENERIC
 SG_ ClimtCool_D_Rq : 23|3@0+ (1,0) [0|7] "SED"  GENERIC
 SG_ HvacEvap_Te_Rq : 33|10@0+ (0.125,-50) [-50|77.875] "degC"  GENERIC
 SG_ HvacEvap_Te_Actl : 17|10@0+ (0.125,-50) [-50|77.75] "degC"  GENERIC
 SG_ HvacAirCond_B_Rq : 7|1@0+ (1,0) [0|1] "SED"  GENERIC
 SG_ HvacEvap_Te_Offst : 1|10@0+ (0.125,-50) [-50|77.875] "degC"  GENERIC
 SG_ ClimtPw_B_Rq : 5|1@0+ (1,0) [0|1] "SED"  GENERIC
 SG_ WndwFrontHeat_B_Stat : 4|1@0+ (1,0) [0|1] "SED"  GENERIC

BO_ 578 Body_Info_4_FD2: 16 GWM
 SG_ PtLatchActv_B_RqBcm : 56|1@0+ (1,0) [0|1] "SED"  GENERIC
 SG_ immoSecureIdleMode : 61|2@0+ (1,0) [0|3] "SED"  GENERIC
 SG_ ReFuelSwtchStat_D_Actl : 63|2@0+ (1,0) [0|3] "SED"  GENERIC
 SG_ FuelPumpPwr_D_Stat : 50|3@0+ (1,0) [0|7] "SED"  GENERIC
 SG_ BattULo_U_Actl : 39|8@0+ (0.0625,0) [0|15.875] "volt"  GENERIC
 SG_ PrkLckCtl_B_Enbl : 22|1@0+ (1,0) [0|1] "SED"  GENERIC
 SG_ PrkLckCtlMsgTxt_D_Rq : 55|2@0+ (1,0) [0|3] "SED"  GENERIC
 SG_ PrkLckCtlAvail_T_Stat : 47|8@0+ (1,0) [0|255] "second"  GENERIC
 SG_ BrkTrnShifLck_B_Stat : 23|1@0+ (1,0) [0|1] "SED"  GENERIC
 SG_ PrkLckCtlUnlck_D_Stat : 58|2@0+ (1,0) [0|3] "SED"  GENERIC
 SG_ PrkLckCtlTow_B_Enbl : 59|1@0+ (1,0) [0|1] "SED"  GENERIC
 SG_ DriverCrankingReq : 51|1@0+ (1,0) [0|1] "SED"  GENERIC
 SG_ EngOff_T_Actl : 7|16@0+ (1,0) [0|65534] "second^0.5"  GENERIC
 SG_ DcacElPw_D_Rq : 53|2@0+ (1,0) [0|3] "SED"  GENERIC
 SG_ BattULo_I_Actl : 21|14@0+ (0.0625,-512) [-512|511.875] "ampere"  GENERIC

BO_ 377 EngineData_7_FD2: 16 GWM
 SG_ HvacAirFullOut_B_Rq : 23|1@0+ (1,0) [0|1] "SED"  GENERIC
 SG_ TrnManShif_D_IndDrv : 7|3@0+ (1,0) [0|7] "unitless"  GENERIC
 SG_ EngAout_Tq_Actl : 2|11@0+ (1,-500) [-500|1547] "Nm"  GENERIC
 SG_ TrnManShifGear_D_IndDrv : 54|3@0+ (1,0) [0|7] "SED"  GENERIC
 SG_ EngFuelCutFull_B_Inhbt : 22|1@0+ (1,0) [0|1] "SED"  GENERIC
 SG_ EngDecelFuelCut_B_Allw : 21|1@0+ (1,0) [0|1] "SED"  GENERIC
 SG_ FuelFlw_Vl_Dsply : 49|10@0+ (25,0) [0|25575] "Micro_Liter"  GENERIC
 SG_ FuelFillInlet_B_Dsply : 32|1@0+ (1,0) [0|1] "SED"  GENERIC
 SG_ EngSrvcRqd_B_Rq : 19|1@0+ (1,0) [0|1] "SED"  GENERIC
 SG_ OdoCount : 47|8@0+ (0.2,0) [0|50.8] "Meters"  GENERIC
 SG_ EngOilLife_Pc_Actl : 39|7@0+ (1,0) [0|100] "percent"  GENERIC
 SG_ EngTqSlwDly_T_Est : 18|11@0+ (1,0) [0|2047] "ms"  GENERIC
 SG_ TrnKickDown_B_RqDrv : 20|1@0+ (1,0) [0|1] "SED"  GENERIC
 SG_ FuelFilterLamp_B_Dsply : 50|1@0+ (1,0) [0|1] "SED"  GENERIC
 SG_ AirCondRec_B_Rq : 55|1@0+ (1,0) [0|1] "SED"  GENERIC
 SG_ AirCondClutch_B_Stats : 51|1@0+ (1,0) [0|1] "SED"  GENERIC
 SG_ EngAoutTqActl_D_Qf : 4|2@0+ (1,0) [0|3] "SED"  GENERIC

BO_ 376 EngineClimateData_FD2: 16 GWM
 SG_ GasPrtc_D_RqDsply : 22|3@0+ (1,0) [0|7] "SED"  GENERIC
 SG_ LnchCtlSys_D_Stat : 7|3@0+ (1,0) [0|7] "SED"  GENERIC
 SG_ EngAout_Aa_Actl : 17|10@0+ (0.05,-25.6) [-25.6|25.55] "rpm/ms"  GENERIC
 SG_ DynoMde_B_Cmd : 4|1@0+ (1,0) [0|1] "SED"  GENERIC
 SG_ AslChime_B_Rq : 39|1@0+ (1,0) [0|1] "SED"  GENERIC
 SG_ HvacHtrCore2_Te_Actl : 1|10@0+ (0.25,-50) [-50|205.5] "degC"  GENERIC
 SG_ PtcHtr_D_Cmd : 38|2@0+ (1,0) [0|3] "SED"  GENERIC
 SG_ EcssLamp_D_RqDsply : 19|2@0+ (1,0) [0|3] "SED"  GENERIC
 SG_ AirAmbTe_D_Qf : 35|2@0+ (1,0) [0|3] "SED"  GENERIC
 SG_ AirAmb_Te_ActlFilt : 49|10@0+ (0.25,-128) [-128|127.75] "degC"  GENERIC
 SG_ AirAmb_P_Actl : 55|6@0+ (10,500) [500|1110] "mbar"  GENERIC
 SG_ AslIconDsply_D_Rq : 3|2@0+ (1,0) [0|3] "SED"  GENERIC
 SG_ AirAmb_Te_Actl : 33|10@0+ (0.25,-128) [-128|127.75] "degC"  GENERIC

BO_ 342 EngineData_6_FD2: 16 GWM
 SG_ FuelRange_L2_DsplyEng : 47|15@0+ (0.1,0) [0|3276.7] "kilometer"  GENERIC
 SG_ HtrLoop_B_Stat : 34|1@0+ (1,0) [0|1] "SED"  GENERIC
 SG_ TqmTerrMdeChng_D_Rdy : 39|3@0+ (1,0) [0|7] "SED"  GENERIC
 SG_ TqmTerrMde_D_Actl : 23|3@0+ (1,0) [0|7] "SED"  GENERIC
 SG_ EngOvrhtMitgActv_D_Ind : 36|2@0+ (1,0) [0|3] "SED"  GENERIC
 SG_ EngClntTe_D_Qf : 33|2@0+ (1,0) [0|3] "SED"  GENERIC
 SG_ EngAcsyArcPmp_Tq_Actl : 63|8@0+ (0.5,0) [0|126.5] "Nm"  GENERIC
 SG_ EngOilLvlDsply_D_Rq : 20|4@0+ (1,0) [0|15] "SED"  GENERIC
 SG_ EngGoutLss_Tq_Est : 31|8@0+ (1,0) [0|255] "Nm"  GENERIC
 SG_ EngOil_Te_Actl : 15|8@0+ (1,-60) [-60|193] "degC"  GENERIC
 SG_ EngClnt_Te_Actl : 7|8@0+ (1,-60) [-60|195] "degC"  GENERIC
 SG_ EngTeColdPrtct_B_Rq : 16|1@0+ (1,0) [0|1] "SED"  GENERIC

BO_ 573 Body_Info_2_FD2: 16 GWM
 SG_ VehStrtKeyType_D_Stat : 28|2@0+ (1,0) [0|3] "SED"  GENERIC,_delete
 SG_ VehStrtKeySrc_D_Stat : 31|3@0+ (1,0) [0|7] "SED"  GENERIC,_delete
 SG_ VehStrtKeyIndx_No_Actl : 23|8@0+ (1,0) [0|255] "unitless"  GENERIC,_delete
 SG_ NfcDevcSearch_No_Rq : 10|3@0+ (1,0) [0|7] "unitless"  GENERIC,_delete
 SG_ NfcDevcSearch_B_Rq : 11|1@0+ (1,0) [0|1] "SED"  GENERIC,_delete
 SG_ NfcSrchRqMsg_No_Cnt : 15|4@0+ (1,0) [0|15] "unitless"  GENERIC,_delete
 SG_ NfcSrchRqMsg_No_Crc : 7|8@0+ (1,0) [0|255] "unitless"  GENERIC,_delete

CM_ "New CAN FD network (Flexible Data Rate)";
CM_ BU_ RFA_BLEM "Bluetooth Low Energy Module
";
CM_ BU_ TCU "Telematic Control Module";
CM_ BU_ GWM "Gateway Module";
CM_ BU_ GENERIC "Holding pattern ECU for developmental messages";
CM_ BU_ TSTR "Diagnostic Tester";
CM_ BO_ 3221225472 "This is a message for not used signals, created by Vector CANdb++ DBC OLE DB Provider.";
CM_ SG_ 3221225472 APIM_NFAM_Word_Tx "MM ISO 15765-2 Message Catalogue
Section RDISP - CONMP";
CM_ SG_ 3221225472 ECG_NFAM_Word_Tx "MM ISO 15765-2 Message Catalogue
Section MC - Audio";
CM_ SG_ 3221225472 APIM_TCUB_Word_Tx "Tx by HS3 APIM";
CM_ BO_ 581 "TP message";
CM_ BO_ 949 "For 2010MY and beyond, use for SCT (non-CGEA) and CGEA modules";
CM_ SG_ 1044 StePinOffst_An_Est "SASM will transmit these signals on vehicles with SASM and without PSCM.  SCCM will not Tx this signal when SASM is present.";
CM_ SG_ 1044 StePinOffst_No_Cs "Signal not transmitted on gas variants.";
CM_ SG_ 1071 CluPdl_PcRate_Actl "Signal not transmitted on HEV variants.";
CM_ SG_ 1071 CluPdlPosPcMeas_D_Qf "Signal not transmitted on HEV variants.";
CM_ SG_ 1071 CluPdlPos_Pc_Meas "Signal not transmitted on HEV variants.";
CM_ SG_ 1071 EngAoutIdl_N_Ntrl "Signal not transmitted on HEV variants and diesel.";
CM_ SG_ 1057 FohEng_D_Rq "Signal not transmitted on vehicles that do not have the fuel operated heater feature.";
CM_ SG_ 1057 EngIdlShutDown_D_Stat "Signal not transmitted on diesel variants.";
CM_ SG_ 1057 FUEL_ALCOHOL_PERCNT "signal not transmitted on diesel and HEV variants.";
CM_ SG_ 1057 TrnTotTq_Rt_Est "Signal not transmitted on gas and HEV variants.";
CM_ SG_ 1057 TrnTotLss_Tq_Est "Signal not transmitted on gas and HEV variants.";
CM_ SG_ 1057 VehVLimStat_D_Actl "Signal not transmitted on gas and HEV variants.";
CM_ SG_ 1057 VehVLimActv_B_Actl "Signal not transmitted on gas and HEV variants.";
CM_ SG_ 870 PolicePurstMde_B_Stat "Normal SED EP 1000. Using 100FP can result  in100ms w/c latency.  Latency accepted for feature/function by SME since existing FGW msg.";
CM_ SG_ 377 EngFuelCutFull_B_Inhbt "Signal not transmitted on diesel variants.";
CM_ SG_ 377 FuelFlw_Vl_Dsply "Signal not transmitted on diesel variants.";
CM_ SG_ 377 FuelFillInlet_B_Dsply "Signal not transmitted on diesel variants.";
CM_ SG_ 377 OdoCount "Signal not transmitted on diesel variants.";
CM_ SG_ 377 EngOilLife_Pc_Actl "Signal not transmitted on diesel variants.";
CM_ SG_ 377 TrnKickDown_B_RqDrv "Signal not transmitted on diesel variants.";
CM_ SG_ 377 AirCondRec_B_Rq "Signal not transmitted on diesel variants.";
CM_ SG_ 377 AirCondClutch_B_Stats "Signal not transmitted on diesel variants.";
CM_ SG_ 376 EngAout_Aa_Actl "Signal not transmitted on HEV variants.";
CM_ SG_ 342 EngOvrhtMitgActv_D_Ind "Signal not transmitted on diesel.";
CM_ SG_ 342 EngGoutLss_Tq_Est "Signal not transmitted on gas and diesel variants.";
BA_DEF_ BO_  "VFrameFormat" ENUM  "StandardCAN","ExtendedCAN","reserved","reserved","reserved","reserved","reserved","reserved","reserved","reserved","reserved","reserved","reserved","reserved","StandardCAN_FD","ExtendedCAN_FD";
BA_DEF_  "BusType" STRING ;
BA_DEF_ BO_  "FrameRouting" STRING ;
BA_DEF_ BO_  "NetworkInitialization" ENUM  "No","Yes";
BA_DEF_ BO_  "GenMsgStartDelayTime" INT 0 10000;
BA_DEF_ BO_  "GenMsgNrOfRepetition" INT 0 100;
BA_DEF_ BO_  "GenMsgDelayTime" INT 0 1000;
BA_DEF_ BO_  "GenMsgCycleTime" INT 0 100000;
BA_DEF_ BO_  "GenMsgSendType" ENUM  "FixedPeriodic","Event","EnabledPeriodic","NotUsed","NotUsed","EventPeriodic","NotUsed","NotUsed","NoMsgSendType";
BA_DEF_ SG_  "U_P702_MY2024_Tx" ENUM  "No","Yes";
BA_DEF_ SG_  "U_V710_MY2023_Tx" ENUM  "No","Yes";
BA_DEF_ SG_  "U_CDX74X_MY2024_Tx" ENUM  "No","Yes";
BA_DEF_ SG_  "U_CDX707_MY2023_Tx" ENUM  "No","Yes";
BA_DEF_ SG_  "U_P708_MY2023_Tx" ENUM  "No","Yes";
BA_DEF_ SG_  "U_V713AV_MY2022_Tx" ENUM  "No","Yes";
BA_DEF_ SG_  "U_V713N_MY2022_Tx" ENUM  "No","Yes";
BA_DEF_ SG_  "ECGUsedTxSignal" ENUM  "No","Yes";
BA_DEF_ SG_  "U_P702_MY2024_Rx" ENUM  "No","Yes";
BA_DEF_ SG_  "U_V710_MY2023_Rx" ENUM  "No","Yes";
BA_DEF_ SG_  "U_CDX74X_MY2024_Rx" ENUM  "No","Yes";
BA_DEF_ SG_  "U_CDX707_MY2023_Rx" ENUM  "No","Yes";
BA_DEF_ SG_  "U_P708_MY2023_Rx" ENUM  "No","Yes";
BA_DEF_ SG_  "U_V713AV_MY2022_Rx" ENUM  "No","Yes";
BA_DEF_ SG_  "U_V713N_MY2022_Rx" ENUM  "No","Yes";
BA_DEF_ SG_  "ECGUsedRxSignal" ENUM  "No","Yes";
BA_DEF_ SG_  "UsedOnPgmDBC" ENUM  "No","Yes";
BA_DEF_ SG_  "ContentDependant" ENUM  "No","Yes";
BA_DEF_ SG_  "GenSigStartValue" HEX 0 268435455;
BA_DEF_ SG_  "MetaData" ENUM  "No","Yes";
BA_DEF_ SG_  "WakeupSignal" ENUM  "No","Yes";
BA_DEF_ SG_  "GenSigInactiveValue" INT 0 100000;
BA_DEF_ SG_  "GenSigSendType" ENUM  "Cyclic","OnWrite","vector_leerstring","OnChange","vector_leerstring","IfActive","vector_leerstring","NoSigSendType";
BA_DEF_ BO_  "TpTxIndex" INT 0 536870911;
BA_DEF_ BO_  "OvtpPushApplication" ENUM  "FALSE","TRUE";
BA_DEF_ BO_  "SCP_FreshnessValueLength" INT 0 512;
BA_DEF_ BO_  "SCP_DataId" INT 0 17663;
BA_DEF_ BO_  "SCP_FreshnessValueTxLength" INT 0 512;
BA_DEF_ BO_  "SCP_AuthInfoTxLength" INT 0 512;
BA_DEF_ BO_  "SC_Message" ENUM  "No","Yes";
BA_DEF_ BO_  "GenMsgRoutingTimeoutTime" INT 0 5000;
BA_DEF_ BO_  "NmAsrMessage" ENUM  "No","Yes";
BA_DEF_ BO_  "DiagState" ENUM  "No","Yes";
BA_DEF_ BO_  "DiagRequest" ENUM  "No","Yes";
BA_DEF_ BO_  "DiagResponse" ENUM  "No","Yes";
BA_DEF_ BO_  "GenMsgILSupport" ENUM  "No","Yes";
BA_DEF_ BU_  "OvtpOperationMode" ENUM  "SERVER","CLIENT";
BA_DEF_ BU_  "OvtpEcuAddress" INT 0 1022;
BA_DEF_ BU_  "ILUsed" ENUM  "No","Yes";
BA_DEF_ BU_  "Terminator" ENUM  "No","Yes";
BA_DEF_ BU_  "NodeWakeUpTime" INT 0 10000;
BA_DEF_ BU_  "NodeStartUpTime" INT 0 10000;
BA_DEF_ BU_  "NmAsrNodeIdentifier" HEX 0 255;
BA_DEF_ BU_  "NmAsrNode" ENUM  "No","Yes";
BA_DEF_ BU_  "PowerType" ENUM  "Switched","Latched","Sleep","vector_leerstring","vector_leerstring";
BA_DEF_ BU_  "NmNode" ENUM  "No","Yes";
BA_DEF_ BU_  "NmStationAddress" INT 0 255;
BA_DEF_ BU_  "NosPackage" ENUM  "None","I3_1","I3_2","1.0.1","RP","EuCD","Volcano","I3_3","FNOS_Autosar";
BA_DEF_ BU_  "PackageID" STRING ;
BA_DEF_ BU_  "GatewayECU" ENUM  "No","Yes";
BA_DEF_  "NetworkSpeed" ENUM  "500kBits/s","125kBit/s";
BA_DEF_  "VersionNumber" INT 0 10000;
BA_DEF_  "StarNetworkGwType" ENUM  "0=NotDefined","1=HS1","2=HS2","3=HS3","4=HS4","5=HS5","6=MS1","7=HS6","8=HS7","9=MS2","10=FD1","11=FD2","12=FD3","13=FD4","14=FD5","15=FD6","16=FD7","17=FD8";
BA_DEF_  "CMDB_Version" STRING ;
BA_DEF_  "NmType" STRING ;
BA_DEF_  "NmAsrMessageCount" INT 128 256;
BA_DEF_  "NmAsrBaseAddress" HEX 1280 1408;
BA_DEF_  "DBName" STRING ;
BA_DEF_  "VersionDay" INT 1 31;
BA_DEF_  "Manufacturer" STRING ;
BA_DEF_  "VersionMonth" INT 1 12;
BA_DEF_  "VersionYear" INT 2000 3000;
BA_DEF_  "NmBaseAddress" HEX 1280 1280;
BA_DEF_  "NmMessageCount" INT 0 128;
BA_DEF_REL_ BU_SG_REL_  "SC_Verification" ENUM  "No","Yes";
BA_DEF_DEF_  "VFrameFormat" "ExtendedCAN_FD";
BA_DEF_DEF_  "BusType" "";
BA_DEF_DEF_  "FrameRouting" "";
BA_DEF_DEF_  "NetworkInitialization" "Yes";
BA_DEF_DEF_  "GenMsgStartDelayTime" 0;
BA_DEF_DEF_  "GenMsgNrOfRepetition" 1;
BA_DEF_DEF_  "GenMsgDelayTime" 20;
BA_DEF_DEF_  "GenMsgCycleTime" 0;
BA_DEF_DEF_  "GenMsgSendType" "NoMsgSendType";
BA_DEF_DEF_  "U_P702_MY2024_Tx" "No";
BA_DEF_DEF_  "U_V710_MY2023_Tx" "No";
BA_DEF_DEF_  "U_CDX74X_MY2024_Tx" "No";
BA_DEF_DEF_  "U_CDX707_MY2023_Tx" "No";
BA_DEF_DEF_  "U_P708_MY2023_Tx" "No";
BA_DEF_DEF_  "U_V713AV_MY2022_Tx" "No";
BA_DEF_DEF_  "U_V713N_MY2022_Tx" "No";
BA_DEF_DEF_  "ECGUsedTxSignal" "No";
BA_DEF_DEF_  "U_P702_MY2024_Rx" "No";
BA_DEF_DEF_  "U_V710_MY2023_Rx" "No";
BA_DEF_DEF_  "U_CDX74X_MY2024_Rx" "No";
BA_DEF_DEF_  "U_CDX707_MY2023_Rx" "No";
BA_DEF_DEF_  "U_P708_MY2023_Rx" "No";
BA_DEF_DEF_  "U_V713AV_MY2022_Rx" "No";
BA_DEF_DEF_  "U_V713N_MY2022_Rx" "No";
BA_DEF_DEF_  "ECGUsedRxSignal" "No";
BA_DEF_DEF_  "UsedOnPgmDBC" "Yes";
BA_DEF_DEF_  "ContentDependant" "No";
BA_DEF_DEF_  "GenSigStartValue" 0;
BA_DEF_DEF_  "MetaData" "No";
BA_DEF_DEF_  "WakeupSignal" "No";
BA_DEF_DEF_  "GenSigInactiveValue" 0;
BA_DEF_DEF_  "GenSigSendType" "NoSigSendType";
BA_DEF_DEF_  "TpTxIndex" 0;
BA_DEF_DEF_  "OvtpPushApplication" "FALSE";
BA_DEF_DEF_  "SCP_FreshnessValueLength" 64;
BA_DEF_DEF_  "SCP_DataId" 0;
BA_DEF_DEF_  "SCP_FreshnessValueTxLength" 11;
BA_DEF_DEF_  "SCP_AuthInfoTxLength" 53;
BA_DEF_DEF_  "SC_Message" "No";
BA_DEF_DEF_  "GenMsgRoutingTimeoutTime" 0;
BA_DEF_DEF_  "NmAsrMessage" "No";
BA_DEF_DEF_  "DiagState" "No";
BA_DEF_DEF_  "DiagRequest" "No";
BA_DEF_DEF_  "DiagResponse" "No";
BA_DEF_DEF_  "GenMsgILSupport" "Yes";
BA_DEF_DEF_  "OvtpOperationMode" "SERVER";
BA_DEF_DEF_  "OvtpEcuAddress" 0;
BA_DEF_DEF_  "ILUsed" "Yes";
BA_DEF_DEF_  "Terminator" "No";
BA_DEF_DEF_  "NodeWakeUpTime" 10;
BA_DEF_DEF_  "NodeStartUpTime" 250;
BA_DEF_DEF_  "NmAsrNodeIdentifier" 128;
BA_DEF_DEF_  "NmAsrNode" "No";
BA_DEF_DEF_  "PowerType" "Switched";
BA_DEF_DEF_  "NmNode" "No";
BA_DEF_DEF_  "NmStationAddress" 0;
BA_DEF_DEF_  "NosPackage" "I3_3";
BA_DEF_DEF_  "PackageID" "08.05.00.00.71.xx.xx.rr.00.00";
BA_DEF_DEF_  "GatewayECU" "No";
BA_DEF_DEF_  "NetworkSpeed" "500kBits/s";
BA_DEF_DEF_  "VersionNumber" 1;
BA_DEF_DEF_  "StarNetworkGwType" "0=NotDefined";
BA_DEF_DEF_  "CMDB_Version" "v11.01";
BA_DEF_DEF_  "NmType" "Ford-OSEK";
BA_DEF_DEF_  "NmAsrMessageCount" 128;
BA_DEF_DEF_  "NmAsrBaseAddress" 1408;
BA_DEF_DEF_  "DBName" "";
BA_DEF_DEF_  "VersionDay" 1;
BA_DEF_DEF_  "Manufacturer" "Ford";
BA_DEF_DEF_  "VersionMonth" 1;
BA_DEF_DEF_  "VersionYear" 2011;
BA_DEF_DEF_  "NmBaseAddress" 1280;
BA_DEF_DEF_  "NmMessageCount" 128;
BA_DEF_DEF_REL_ "SC_Verification" "No";
BA_ "VersionNumber" 13;
BA_ "BusType" "CAN FD";
BA_ "VersionYear" 2023;
BA_ "VersionMonth" 2;
BA_ "VersionDay" 3;
BA_ "CMDB_Version" "FNV3_v21.03_draft vM";
BA_ "StarNetworkGwType" 11;
BA_ "DBName" "FD2_CAN";
BA_ "OvtpEcuAddress" BU_ RFA_BLEM 76;
BA_ "NmStationAddress" BU_ RFA_BLEM 8;
BA_ "PowerType" BU_ RFA_BLEM 2;
BA_ "NmAsrNode" BU_ RFA_BLEM 1;
BA_ "NmAsrNodeIdentifier" BU_ RFA_BLEM 136;
BA_ "NodeStartUpTime" BU_ RFA_BLEM 1000;
BA_ "NodeWakeUpTime" BU_ RFA_BLEM 200;
BA_ "NmStationAddress" BU_ TCU 16;
BA_ "PowerType" BU_ TCU 2;
BA_ "NmAsrNode" BU_ TCU 1;
BA_ "NmAsrNodeIdentifier" BU_ TCU 144;
BA_ "NodeWakeUpTime" BU_ TCU 60;
BA_ "Terminator" BU_ TCU 1;
BA_ "OvtpEcuAddress" BU_ TCU 145;
BA_ "PackageID" BU_ TCU "08.05.11.3D.03.00.00.00.00.00";
BA_ "NmStationAddress" BU_ GWM 30;
BA_ "PowerType" BU_ GWM 2;
BA_ "NmAsrNode" BU_ GWM 1;
BA_ "NmAsrNodeIdentifier" BU_ GWM 158;
BA_ "NodeStartUpTime" BU_ GWM 100;
BA_ "NodeWakeUpTime" BU_ GWM 100;
BA_ "Terminator" BU_ GWM 1;
BA_ "OvtpEcuAddress" BU_ GWM 216;
BA_ "OvtpOperationMode" BU_ GWM 1;
BA_ "GatewayECU" BU_ GWM 1;
BA_ "NosPackage" BU_ GWM 4;
BA_ "NodeWakeUpTime" BU_ _delete 100;
BA_ "NodeWakeUpTime" BU_ GENERIC 100;
BA_ "NodeWakeUpTime" BU_ TSTR 100;
BA_ "GenMsgCycleTime" BO_ 926 1000;
BA_ "VFrameFormat" BO_ 926 14;
BA_ "TpTxIndex" BO_ 581 30;
BA_ "VFrameFormat" BO_ 581 14;
BA_ "SC_Message" BO_ 1088 1;
BA_ "SCP_DataId" BO_ 1088 9280;
BA_ "FrameRouting" BO_ 1088 "FD1_CAN,0x440;";
BA_ "VFrameFormat" BO_ 1088 14;
BA_ "FrameRouting" BO_ 954 "FD1_CAN,0x3BA;";
BA_ "VFrameFormat" BO_ 954 14;
BA_ "FrameRouting" BO_ 770 "FD1_CAN,0x302;";
BA_ "VFrameFormat" BO_ 770 14;
BA_ "FrameRouting" BO_ 672 "MS1_CAN,0x2A0;";
BA_ "VFrameFormat" BO_ 672 14;
BA_ "TpTxIndex" BO_ 591 49;
BA_ "VFrameFormat" BO_ 591 14;
BA_ "FrameRouting" BO_ 481 "FD1_CAN,0x1E1;";
BA_ "VFrameFormat" BO_ 481 14;
BA_ "FrameRouting" BO_ 388 "FD1_CAN,0x184;";
BA_ "VFrameFormat" BO_ 388 14;
BA_ "SC_Message" BO_ 909 1;
BA_ "SCP_DataId" BO_ 909 9101;
BA_ "FrameRouting" BO_ 909 "FD1_CAN,0x38D;";
BA_ "VFrameFormat" BO_ 909 14;
BA_ "FrameRouting" BO_ 949 "FD1_CAN,0x3B5;";
BA_ "VFrameFormat" BO_ 949 14;
BA_ "FrameRouting" BO_ 952 "FD1_CAN,0x3B8;";
BA_ "VFrameFormat" BO_ 952 14;
BA_ "SC_Message" BO_ 1044 1;
BA_ "SCP_DataId" BO_ 1044 5140;
BA_ "FrameRouting" BO_ 1044 "FD1_CAN,0x414;";
BA_ "VFrameFormat" BO_ 1044 14;
BA_ "FrameRouting" BO_ 1095 "FD1_CAN,0x447;";
BA_ "VFrameFormat" BO_ 1095 14;
BA_ "FrameRouting" BO_ 1076 "HS3_CAN,0x434;";
BA_ "VFrameFormat" BO_ 1076 14;
BA_ "SC_Message" BO_ 1071 1;
BA_ "SCP_DataId" BO_ 1071 5167;
BA_ "FrameRouting" BO_ 1071 "FD1_CAN,0x42F;";
BA_ "VFrameFormat" BO_ 1071 14;
BA_ "SC_Message" BO_ 1057 1;
BA_ "SCP_DataId" BO_ 1057 9249;
BA_ "FrameRouting" BO_ 1057 "FD1_CAN,0x421;";
BA_ "VFrameFormat" BO_ 1057 14;
BA_ "SC_Message" BO_ 870 1;
BA_ "SCP_DataId" BO_ 870 4966;
BA_ "FrameRouting" BO_ 870 "FD1_CAN,0x366;";
BA_ "VFrameFormat" BO_ 870 14;
BA_ "FrameRouting" BO_ 869 "FD1_CAN,0x365;";
BA_ "VFrameFormat" BO_ 869 14;
BA_ "FrameRouting" BO_ 806 "MS1_CAN,0x326;";
BA_ "VFrameFormat" BO_ 806 14;
BA_ "SC_Message" BO_ 578 1;
BA_ "SCP_DataId" BO_ 578 4674;
BA_ "FrameRouting" BO_ 578 "FD1_CAN,0x242;";
BA_ "VFrameFormat" BO_ 578 14;
BA_ "SC_Message" BO_ 377 1;
BA_ "SCP_DataId" BO_ 377 16761;
BA_ "FrameRouting" BO_ 377 "FD1_CAN,0x179;";
BA_ "VFrameFormat" BO_ 377 14;
BA_ "SC_Message" BO_ 376 1;
BA_ "SCP_DataId" BO_ 376 4472;
BA_ "FrameRouting" BO_ 376 "FD1_CAN,0x178;";
BA_ "VFrameFormat" BO_ 376 14;
BA_ "SC_Message" BO_ 342 1;
BA_ "SCP_DataId" BO_ 342 4438;
BA_ "FrameRouting" BO_ 342 "FD1_CAN,0x156;";
BA_ "VFrameFormat" BO_ 342 14;
BA_ "SC_Message" BO_ 573 1;
BA_ "SCP_DataId" BO_ 573 12861;
BA_ "FrameRouting" BO_ 573 "FD1_CAN,0x23D;";
BA_ "VFrameFormat" BO_ 573 14;
BA_ "GenSigSendType" SG_ 3221225472 OTAPhysGWM_ECGtoWBCM 3;
BA_ "ECGUsedTxSignal" SG_ 3221225472 OTAPhysGWM_ECGtoWBCM 1;
BA_ "GenSigSendType" SG_ 3221225472 PARSEDPhysGWM_ECGtoWBCM 3;
BA_ "ECGUsedTxSignal" SG_ 3221225472 PARSEDPhysGWM_ECGtoWBCM 1;
BA_ "GenSigSendType" SG_ 3221225472 PARSEDPushFcGWM_ECGtoWBCM 3;
BA_ "ECGUsedTxSignal" SG_ 3221225472 PARSEDPushFcGWM_ECGtoWBCM 1;
BA_ "GenSigSendType" SG_ 3221225472 OTAPhysGWM_ECGtoNFAM 3;
BA_ "ECGUsedTxSignal" SG_ 3221225472 OTAPhysGWM_ECGtoNFAM 1;
BA_ "U_P708_MY2023_Tx" SG_ 3221225472 OTAPhysGWM_ECGtoNFAM 1;
BA_ "GenSigSendType" SG_ 3221225472 PARSEDPhysGWM_ECGtoNFAM 3;
BA_ "ECGUsedTxSignal" SG_ 3221225472 PARSEDPhysGWM_ECGtoNFAM 1;
BA_ "U_P708_MY2023_Tx" SG_ 3221225472 PARSEDPhysGWM_ECGtoNFAM 1;
BA_ "U_V710_MY2023_Tx" SG_ 3221225472 PARSEDPhysGWM_ECGtoNFAM 1;
BA_ "GenSigSendType" SG_ 3221225472 PARSEDPushFcGWM_ECGtoNFAM 3;
BA_ "ECGUsedTxSignal" SG_ 3221225472 PARSEDPushFcGWM_ECGtoNFAM 1;
BA_ "U_P708_MY2023_Tx" SG_ 3221225472 PARSEDPushFcGWM_ECGtoNFAM 1;
BA_ "U_V710_MY2023_Tx" SG_ 3221225472 PARSEDPushFcGWM_ECGtoNFAM 1;
BA_ "GenSigSendType" SG_ 3221225472 PARSEDPhysGWM_ECGtoRDAPM 3;
BA_ "ECGUsedTxSignal" SG_ 3221225472 PARSEDPhysGWM_ECGtoRDAPM 1;
BA_ "GenSigSendType" SG_ 3221225472 PARSEDPhysGWM_ECGtoLDAPM 3;
BA_ "ECGUsedTxSignal" SG_ 3221225472 PARSEDPhysGWM_ECGtoLDAPM 1;
BA_ "GenSigSendType" SG_ 3221225472 OTAPhysGWM_ECGtoLDAPM 3;
BA_ "ECGUsedTxSignal" SG_ 3221225472 OTAPhysGWM_ECGtoLDAPM 1;
BA_ "GenSigSendType" SG_ 3221225472 OTAPhysGWM_ECGtoRDAPM 3;
BA_ "ECGUsedTxSignal" SG_ 3221225472 OTAPhysGWM_ECGtoRDAPM 1;
BA_ "GenSigSendType" SG_ 3221225472 PARSEDPushFcGWM_ECGtoRDAPM 3;
BA_ "ECGUsedTxSignal" SG_ 3221225472 PARSEDPushFcGWM_ECGtoRDAPM 1;
BA_ "GenSigSendType" SG_ 3221225472 PARSEDPhysGWM_ECGtoTCUB 3;
BA_ "ECGUsedTxSignal" SG_ 3221225472 PARSEDPhysGWM_ECGtoTCUB 1;
BA_ "U_V713AV_MY2022_Tx" SG_ 3221225472 PARSEDPhysGWM_ECGtoTCUB 1;
BA_ "GenSigSendType" SG_ 3221225472 OTAPhysGWM_ECGtoTCUB 3;
BA_ "ECGUsedTxSignal" SG_ 3221225472 OTAPhysGWM_ECGtoTCUB 1;
BA_ "U_V713AV_MY2022_Tx" SG_ 3221225472 OTAPhysGWM_ECGtoTCUB 1;
BA_ "GenSigSendType" SG_ 3221225472 PARSEDPushFcGWM_ECGtoLDAPM 3;
BA_ "ECGUsedTxSignal" SG_ 3221225472 PARSEDPushFcGWM_ECGtoLDAPM 1;
BA_ "GenSigSendType" SG_ 3221225472 PARSEDPushFcGWM_ECGtoTCUB 3;
BA_ "ECGUsedTxSignal" SG_ 3221225472 PARSEDPushFcGWM_ECGtoTCUB 1;
BA_ "U_V713AV_MY2022_Tx" SG_ 3221225472 PARSEDPushFcGWM_ECGtoTCUB 1;
BA_ "GenSigSendType" SG_ 3221225472 SymKeyPhysGWM_ECGtoWBCM 3;
BA_ "ECGUsedTxSignal" SG_ 3221225472 SymKeyPhysGWM_ECGtoWBCM 1;
BA_ "GenSigSendType" SG_ 3221225472 SymKeyPhysGWM_ECGtoNFAM 3;
BA_ "ECGUsedTxSignal" SG_ 3221225472 SymKeyPhysGWM_ECGtoNFAM 1;
BA_ "U_P708_MY2023_Tx" SG_ 3221225472 SymKeyPhysGWM_ECGtoNFAM 1;
BA_ "U_V710_MY2023_Tx" SG_ 3221225472 SymKeyPhysGWM_ECGtoNFAM 1;
BA_ "GenSigSendType" SG_ 3221225472 SymKeyPhysGWM_ECGtoRDAPM 3;
BA_ "ECGUsedTxSignal" SG_ 3221225472 SymKeyPhysGWM_ECGtoRDAPM 1;
BA_ "GenSigSendType" SG_ 3221225472 SymKeyPhysGWM_ECGtoLDAPM 3;
BA_ "ECGUsedTxSignal" SG_ 3221225472 SymKeyPhysGWM_ECGtoLDAPM 1;
BA_ "GenSigSendType" SG_ 3221225472 SymKeyPhysGWM_ECGtoTCUB 3;
BA_ "ECGUsedTxSignal" SG_ 3221225472 SymKeyPhysGWM_ECGtoTCUB 1;
BA_ "U_V713AV_MY2022_Tx" SG_ 3221225472 SymKeyPhysGWM_ECGtoTCUB 1;
BA_ "GenSigStartValue" SG_ 3221225472 EngMnfldChrg_Te_Actl 126;
BA_ "GenSigStartValue" SG_ 3221225472 EngInnrClnt_Te_Actl 126;
BA_ "ECGUsedTxSignal" SG_ 3221225472 ECG_NFAM_Word_Tx 1;
BA_ "ECGUsedTxSignal" SG_ 3221225472 ECG_MRCMB_Word_Tx 1;
BA_ "ECGUsedTxSignal" SG_ 3221225472 ECG_MRCMA_Word_Tx 1;
BA_ "GenSigSendType" SG_ 3221225472 AplPrimForUnload_D_Rq 3;
BA_ "GenSigSendType" SG_ 3221225472 AplPrimForLoad_D_Rq 3;
BA_ "ECGUsedRxSignal" SG_ 3221225472 AplReas_D_Stat 1;
BA_ "GenSigSendType" SG_ 3221225472 AplReas_D_Stat 3;
BA_ "ECGUsedRxSignal" SG_ 3221225472 AplHelpButtn_D_Stat 1;
BA_ "GenSigSendType" SG_ 3221225472 AplHelpButtn_D_Stat 3;
BA_ "ECGUsedRxSignal" SG_ 3221225472 AplReas_No_Actl 1;
BA_ "GenSigSendType" SG_ 3221225472 AplReas_No_Actl 3;
BA_ "GenSigSendType" SG_ 3221225472 AprForNextOrder_D_Rq 3;
BA_ "ECGUsedTxSignal" SG_ 926 UtcDateTZone_No_Actl 1;
BA_ "GenSigSendType" SG_ 926 UtcDateTZone_No_Actl 3;
BA_ "WakeupSignal" SG_ 1088 ChrgStat_D2_Dsply 1;
BA_ "GenSigStartValue" SG_ 1088 BattDcChrgRms_I_Lim 32766;
BA_ "GenSigStartValue" SG_ 1088 TrlrRng_L_Dsply 8190;
BA_ "GenSigStartValue" SG_ 1088 HvacPrecond_Te_Rq 2;
BA_ "WakeupSignal" SG_ 1088 HvacPrecondMode2_D_Rq 1;
BA_ "WakeupSignal" SG_ 1088 HvacPrecondBlwr2_D_Rq 1;
BA_ "WakeupSignal" SG_ 954 TrukBedLght_B_Stat 1;
BA_ "WakeupSignal" SG_ 954 TrlrHitchLamp_D_Stat 1;
BA_ "WakeupSignal" SG_ 954 VehWlcmFrwlMde_D_Stat 1;
BA_ "WakeupSignal" SG_ 954 VehWlcmFrwl_D_Stat 1;
BA_ "GenSigStartValue" SG_ 770 ScMnSoc_Pc_Actl 100;
BA_ "GenSigStartValue" SG_ 770 CurntTrgtSoc_Pc_Dsply 100;
BA_ "GenSigStartValue" SG_ 770 CurntTrgtSoc_Pc_Rq 100;
BA_ "U_V713AV_MY2022_Rx" SG_ 770 FstChrgBulk_T_Est 1;
BA_ "GenSigStartValue" SG_ 672 BtnID_A 255;
BA_ "WakeupSignal" SG_ 672 BtnID_A 1;
BA_ "GenSigStartValue" SG_ 672 BtnID_B 255;
BA_ "WakeupSignal" SG_ 672 BtnID_B 1;
BA_ "GenSigStartValue" SG_ 672 BtnID_C 255;
BA_ "WakeupSignal" SG_ 672 BtnID_C 1;
BA_ "GenSigStartValue" SG_ 672 BtnID_D 255;
BA_ "WakeupSignal" SG_ 672 BtnID_D 1;
BA_ "WakeupSignal" SG_ 672 Coding_BtnID_B 1;
BA_ "WakeupSignal" SG_ 672 Coding_BtnID_A 1;
BA_ "WakeupSignal" SG_ 672 Coding_BtnID_D 1;
BA_ "WakeupSignal" SG_ 672 Coding_BtnID_C 1;
BA_ "GenSigStartValue" SG_ 672 SetVolume 30;
BA_ "WakeupSignal" SG_ 672 SetVolume 1;
BA_ "WakeupSignal" SG_ 672 SetPointVolume 1;
BA_ "GenSigStartValue" SG_ 481 PsCpbltyPrim_B_Stat 1;
BA_ "WakeupSignal" SG_ 909 IgnPsswrdDsply_B_Rq 1;
BA_ "WakeupSignal" SG_ 909 ElPwPoint_D_Rq 1;
BA_ "WakeupSignal" SG_ 909 HazrdLght_B_Stat 1;
BA_ "GenSigStartValue" SG_ 909 WiprFront_D_Stat2 15;
BA_ "GenSigStartValue" SG_ 909 HeadLghtHiPrmsn_D_Stat 3;
BA_ "WakeupSignal" SG_ 909 immoMsgTxt_D_Rq 1;
BA_ "WakeupSignal" SG_ 909 PrsnlDevcChrgEnbl_B_Rq 1;
BA_ "MetaData" SG_ 909 KeyMykeyTot_No_Cnt 1;
BA_ "MetaData" SG_ 909 KeyAdmnTot_No_Cnt 1;
BA_ "GenSigStartValue" SG_ 949 Tire_Press_RR_ORR_Data 65533;
BA_ "GenSigStartValue" SG_ 949 Tire_Press_LR_OLR_Data 65533;
BA_ "GenSigStartValue" SG_ 949 Tire_Press_LF_Data 65533;
BA_ "GenSigStartValue" SG_ 949 Tire_Press_RF_Data 65533;
BA_ "GenSigStartValue" SG_ 952 Tire_Press_IRR_Data 65533;
BA_ "GenSigStartValue" SG_ 952 Tire_Press_ILR_Data 65533;
BA_ "MetaData" SG_ 1044 ApaBrkErrDStat_No_Cnt 1;
BA_ "MetaData" SG_ 1044 ApaBrkErrDStat_No_Cs 1;
BA_ "GenSigStartValue" SG_ 1044 ApaBrkErr_D_Stat 2;
BA_ "GenSigStartValue" SG_ 1044 StePinOffst_An_Est 65533;
BA_ "MetaData" SG_ 1044 StePinOffst_No_Cs 1;
BA_ "MetaData" SG_ 1044 StePinOffst_No_Cnt 1;
BA_ "WakeupSignal" SG_ 1095 HeadLghtOn_D_Rq 1;
BA_ "GenSigStartValue" SG_ 1095 HeadLghtOn_D_Rq 1;
BA_ "GenSigSendType" SG_ 1076 FogLghtRearButtn_B_Rq 3;
BA_ "GenSigSendType" SG_ 1076 FogLghtFrontButtn_B_Rq 3;
BA_ "GenSigStartValue" SG_ 1076 W2S_LAMP_OK 1;
BA_ "GenSigStartValue" SG_ 1076 Veh_V_CompLimMx 4093;
BA_ "GenSigStartValue" SG_ 1071 EngMnfld3_P_Actl 254;
BA_ "MetaData" SG_ 1071 CluPdlPosPcMeas_D_Qf 1;
BA_ "GenSigStartValue" SG_ 1071 CluPdlPosPcMeas_D_Qf 1;
BA_ "GenSigStartValue" SG_ 1057 FohEng_D_Rq 2;
BA_ "GenSigStartValue" SG_ 1057 FUEL_ALCOHOL_PERCNT 255;
BA_ "GenSigStartValue" SG_ 870 RngPerChrgInst_L_Dsply 4093;
BA_ "GenSigStartValue" SG_ 870 EffRgenThres_Pc_Dsply 1023;
BA_ "GenSigSendType" SG_ 806 AirAmb_Te_RqCld 3;
BA_ "WakeupSignal" SG_ 578 ReFuelSwtchStat_D_Actl 1;
BA_ "GenSigStartValue" SG_ 578 BattULo_U_Actl 255;
BA_ "WakeupSignal" SG_ 578 PrkLckCtlMsgTxt_D_Rq 1;
BA_ "WakeupSignal" SG_ 578 PrkLckCtlAvail_T_Stat 1;
BA_ "GenSigStartValue" SG_ 578 BattULo_I_Actl 16383;
BA_ "MetaData" SG_ 377 EngAoutTqActl_D_Qf 1;
BA_ "MetaData" SG_ 376 AirAmbTe_D_Qf 1;
BA_ "GenSigStartValue" SG_ 376 AirAmbTe_D_Qf 1;
BA_ "MetaData" SG_ 342 EngClntTe_D_Qf 1;
BA_ "WakeupSignal" SG_ 573 VehStrtKeyType_D_Stat 1;
BA_ "WakeupSignal" SG_ 573 VehStrtKeySrc_D_Stat 1;
BA_ "WakeupSignal" SG_ 573 VehStrtKeyIndx_No_Actl 1;
VAL_ 3221225472 EngMnfldChrg_Te_Actl 127 "Faulty" 126 "NoDataExists" ;
VAL_ 3221225472 EngInnrClnt_Te_Actl 127 "Faulty" 126 "NoDataExists" ;
VAL_ 3221225472 DcacOut2_Pw2_Dsply 8191 "Faulty" 8190 "NoDataExists" ;
VAL_ 3221225472 DcacOut1_Pw2_Dsply 8191 "Faulty" 8190 "NoDataExists" ;
VAL_ 3221225472 DcacFaltMsgTxt_D2_Rq 35 "NotUsed_1" 34 "FrontTrnkPlgWarnDertExceed" 33 "FrontTrnkPlgWarnDerate" 32 "FrontTrnkPlgWarnFullPw" 31 "IpcPlugWarnDrive" 30 "DcacbOvercurrentLp" 29 "DcacbService" 28 "DcacbNotAvailable" 27 "DcacbAcOnOutput" 26 "DcacbTemperature" 25 "DcacbGfci" 24 "DcacbOvercurrent" 23 "PpoUsageWhenVehlsCharging" 22 "RpsNewKeyCycleWarning" 21 "LowSocRpsWarning" 20 "RpsResetWarn_ChngDrvToPark" 19 "RpsResetWarning" 18 "FirstRpsWarning" 63 "NotUsed_29" 17 "PowerTakeoff" 16 "HevDerate" 15 "HvacOn" 14 "OvercurrentLP" 13 "EngineRun" 12 "Service" 11 "NotAvailable" 10 "PlugWarn" 9 "PlugWarnDrive" 8 "BreakerC" 7 "BreakerB" 6 "BreakerA" 5 "FuelLow" 4 "AcOnOutput" 3 "Temperature" 2 "Gfci" 1 "Overcurrent" 0 "Ok" ;
VAL_ 3221225472 ClimtCool_D_RqPt 3 "NotUsed_2" 2 "NotUsed_1" 1 "On" 0 "Off" ;
VAL_ 3221225472 BtsiShifInhbt_B_RqPt 1 "Yes" 0 "No" ;
VAL_ 3221225472 AplPrimForUnload_D_Rq 0 "NoRequest" 1 "Disable" 2 "Enable" 3 "NotUsed_1" ;
VAL_ 3221225472 AplPrimForLoad_D_Rq 0 "NoRequest" 1 "Disable" 2 "Enable" 3 "NotUsed_1" ;
VAL_ 3221225472 AplReas_D_Stat 0 "Commanded" 1 "Faulted" 2 "SystemOverride" 3 "UserOverride" ;
VAL_ 3221225472 AplHelpButtn_D_Stat 0 "NoCallRequest" 1 "RequestCall" 2 "CancelCall" 3 "PwFailed" ;
VAL_ 3221225472 AprForNextOrder_D_Rq 0 "NoRequest" 1 "Disable" 2 "Enable" 3 "NotUsed_1" ;
VAL_ 1088 ChrgStat_D2_Dsply 0 "NotReady" 1 "FaultInsideCar" 2 "FaultOutsideCar" 3 "EvseNotCompatible" 4 "EvseNotDetected" 5 "EvsePaused" 6 "ChargeScheduled" 7 "ChargingAC" 8 "ChargingDCFastCharge" 9 "ChargingInductive" 10 "ChargingSystemMaintain" 11 "CabinPreconditioning" 12 "DriveConditioning" 13 "ChargeTargetReached" 14 "ChargeStartCommanded" 15 "ChargeStopCommanded" ;
VAL_ 1088 BattDcChrgRms_I_Lim 32766 "NoDataExists" 32767 "Faulty" ;
VAL_ 1088 TrlrRng_L_Dsply 8190 "NoDataExists" 8191 "Faulty" ;
VAL_ 1088 HvacPrecondMode2_D_Rq 0 "Off" 1 "MAX_AC" 2 "Panel" 3 "Panel_Floor" 4 "Floor" 5 "Windshield_Floor" 6 "Windshield" 7 "Windshield_Panel" 8 "Windshield_Panel_Floor" 9 "Max_Defrost" 10 "Auto" 11 "Last_User_Settings" 12 "Low_Blower_Auto" 13 "NotUsed2" 14 "NotUsed3" 15 "NotUsed4" ;
VAL_ 1088 BattChrgInhbt_D_Rq 0 "Enable_Charging" 1 "InhibitChargingThermal" 2 "NotUsed" 3 "MaintainTargetSoc" ;
VAL_ 1088 ChrgTMatch_B_Stat 0 "False" 1 "True" ;
VAL_ 1088 HvacPrecondAC_D_Rq 0 "Off" 1 "On" 2 "Auto" 3 "Last_User_Setting" ;
VAL_ 1088 HvacPrecondBlwr2_D_Rq 0 "Off" 1 "Speed1" 2 "Speed2" 3 "Speed3" 4 "Speed4" 5 "Speed5" 6 "Speed6" 7 "Speed7" 8 "Auto" 9 "Last_User_Setting" 10 "NotUsed1" 11 "NotUsed2" 12 "NotUsed3" 13 "NotUsed4" 14 "NotUsed5" 15 "NotUsed6" ;
VAL_ 1088 HvacPrecondRecirc_D_Rq 0 "Outside" 1 "Recirc" 2 "Auto" 3 "Last_User_Setting" ;
VAL_ 954 ExtLght_D_Falt 0 "Null" 1 "StartEngine" 2 "NoStationary" 3 "Error" ;
VAL_ 954 ExtLghtLeft_D_Stat 0 "Null" 1 "Off" 2 "On" 3 "NotUsed" ;
VAL_ 954 ExtLghtFront_D_Stat 0 "Null" 1 "Off" 2 "On" 3 "NotUsed" ;
VAL_ 954 ExtLghtAlrt_B_Rq 0 "No" 1 "Yes" ;
VAL_ 954 PudSptLghtRight_D_Rq 0 "Null" 1 "Off" 2 "On" 3 "NotUsed" ;
VAL_ 954 PudSptLghtLeft_D_Rq 0 "Null" 1 "Off" 2 "On" 3 "NotUsed" ;
VAL_ 954 ExtLghtRight_D_Stat 0 "Null" 1 "Off" 2 "On" 3 "NotUsed" ;
VAL_ 954 ExtLghtRear_D_Stat 0 "Null" 1 "Off" 2 "On" 3 "NotUsed" ;
VAL_ 954 TrukBedLght_B_Stat 0 "Off" 1 "On" ;
VAL_ 954 TrlrHitchLamp_D_Stat 0 "Off" 1 "On" ;
VAL_ 954 LicPlateLght_B_Stat 0 "Off" 1 "On" ;
VAL_ 954 VehWlcmFrwlMde_D_Stat 0 "Null" 1 "Approach" 2 "IlluminatedEntry" 3 "CourtesyLightingAll" 4 "CourtesyLightingDelayAll" 5 "CourtesyLightingExtended" 6 "CourtesyLightingDelayExt" 7 "IlluminatedExit" ;
VAL_ 954 VehWlcmFrwl_D_Stat 0 "Null" 1 "Welcome" 2 "Farewell" 3 "RunStart" ;
VAL_ 954 TlghtTest_D_Stat 0 "Null" 1 "Completed" 2 "Ended" 3 "InProgress" ;
VAL_ 954 LghtAmbDrvMde_B_Stat 0 "Manual" 1 "Automatic" ;
VAL_ 954 PwRnngBoardPoll_D_Stat 0 "NotPolling" 1 "PkNotPresent" 2 "PkPresent" 3 "NotUsed" ;
VAL_ 954 PoliceDmngLvl_D_Stat 0 "Null" 1 "Decommissioned" 2 "Inactive" 3 "Low1Day" 4 "Low1Night" 5 "Off_Day" 6 "Off_Night" 7 "NotUsed" ;
VAL_ 954 LoadShedRelay_B_Rq 0 "Inactive" 1 "Active" ;
VAL_ 954 KeylessIdl_B_Stat 0 "Not_Pressed" 1 "Pressed" ;
VAL_ 954 TlghtTestLght_D_Stat 0 "Null" 1 "ParkingLightsIlluminated" 2 "TestingRightTurnSignal" 3 "TestingLeftTurnSignal" 4 "TestingBrakeLights" 5 "TestingReverseLights" 6 "AllOff" 7 "Error" ;
VAL_ 954 TlghtTestPrecnd_D_Stat 0 "Null" 1 "IgnitionNotOn" 2 "TailLightsOn" 3 "BattSocLessThan75Percent" 4 "PreconditionsPassed" 5 "InteractionPresent" 6 "NotStationary" 7 "Error" ;
VAL_ 954 PosLghtFr_D_Stat 0 "Off" 1 "On" 2 "Outage" 3 "Faulty" ;
VAL_ 954 PosLghtFl_D_Stat 0 "Off" 1 "On" 2 "Outage" 3 "Faulty" ;
VAL_ 954 LoadShedRelayMde_D_Stat 0 "LoadShed" 1 "SnowPlow" 2 "EngRunRelay" 3 "NotUsed_1" ;
VAL_ 954 CargoLght_D_Stat 0 "Null" 1 "Manual" 2 "Automatic" 3 "NotUsed" ;
VAL_ 954 TrlrHitchLamp_D2_Stat 0 "Null" 1 "Manual" 2 "Automatic" 3 "NotUsed" ;
VAL_ 954 ChildLckMaint_D_Stat 0 "Off" 1 "On" 2 "Overruled" 3 "NotUsed_1" ;
VAL_ 954 ExtLghtFront_D_RqBody 0 "Null" 1 "Off" 2 "On" 3 "NotUsed" ;
VAL_ 954 CrtsyLghtRear_D_Stat 0 "Null" 1 "Manual" 2 "Automatic" 3 "NotUsed_1" ;
VAL_ 770 ScEnbl_B_Stat 1 "On" 0 "Off" ;
VAL_ 770 BattTracVrtOck_B_Stat 0 "No" 1 "Yes" ;
VAL_ 770 ChrgTrgtSocOvrrd_B_Stat 1 "On" 0 "Off" ;
VAL_ 770 ScChrgrPwMax_Pw_Actl 4095 "Faulty" ;
VAL_ 770 ScPayloadUpdate_B_Stat 3 "NotUsed" 2 "Complete" 1 "InProcess" 0 "Null" ;
VAL_ 672 Coding_BtnID_B 0 "Not_Pressed" 1 "Pressed" ;
VAL_ 672 Coding_BtnID_A 0 "Not_Pressed" 1 "Pressed" ;
VAL_ 672 Coding_BtnID_D 0 "Not_Pressed" 1 "Pressed" ;
VAL_ 672 Coding_BtnID_C 0 "Not_Pressed" 1 "Pressed" ;
VAL_ 672 BCP_Audible_Beep_Rq 0 "Inactive" 1 "Active" ;
VAL_ 481 PsPrim_D_Stat 0 "NotDetermined" 1 "WarmUpDisChrg" 2 "WarmUpChrg" 3 "PreDrvDisChrg" 4 "PreDrvPwrTest" 5 "PreDrvChrg" 6 "ActDrvDisChrg" 7 "ActDrvReChrg" 8 "FullCpblty" 9 "LimtdCpblty" 10 "NoCpblty" 11 "PreDrvNeeded" 12 "NotUsed_1" 13 "NotUsed_2" 14 "NotUsed_3" 15 "NotUsed_4" ;
VAL_ 481 PsDiagPrim_B_Falt 0 "Inactive" 1 "Active" ;
VAL_ 481 PsCpbltyPrim_B_Stat 0 "Degraded" 1 "Ok" ;
VAL_ 481 PsShedPrim_B_Rq 0 "False" 1 "True" ;
VAL_ 481 PsSftyPrim_B_Stat 0 "Inactive" 1 "Active" ;
VAL_ 481 PsMainPrim_B_Stat 0 "Inactive" 1 "Active" ;
VAL_ 481 PsMainPrim_B_Falt 0 "NoFault" 1 "Fault" ;
VAL_ 481 PsSftyPrim_B_Falt 0 "NoFault" 1 "Fault" ;
VAL_ 481 StopExcptnl_D_Rq 0 "Inactive" 1 "PsngrEmgcyStopSinglePress" 2 "ConveniencePullOver" 3 "CldLawEnforcementPullOver" 4 "CldStopUnoccupied" 5 "CldStopOccupied" 6 "PsngrEmgcyStop" 7 "Faulty" ;
VAL_ 388 BattDchrg_E_ActlMntr 32767 "Faulty" 32766 "NoDataExists" ;
VAL_ 388 BattFdbck_E_ActlMntr 16383 "Faulty" 16382 "NoDataExists" ;
VAL_ 909 IgnPsswrdDsply_B_Rq 1 "Active" 0 "Inactive" ;
VAL_ 909 ElPwPoint_D_Rq 3 "On" 2 "Off2" 1 "Off1" 0 "Null" ;
VAL_ 909 PoliceIdlMde_D_Stat 15 "NotUsed_7" 14 "NotUsed_6" 13 "NotUsed_5" 12 "NotUsed_4" 11 "NotUsed_3" 10 "UtilityIdleActive" 9 "PepsActive" 8 "Decommissioned" 7 "ActiveFault" 6 "ArmFault" 5 "PrearmedFault" 4 "OffFault" 3 "Active" 2 "Arm" 1 "Prearmed" 0 "Off" ;
VAL_ 909 DrLatchMsgTxt_D_Rq 7 "Message7" 6 "Message6" 5 "Message5" 4 "Message4" 3 "Message3" 2 "Message2" 1 "Message1" 0 "NoMessage" ;
VAL_ 909 HazrdLght_B_Stat 1 "On" 0 "Off" ;
VAL_ 909 WiprFront_D_Stat2 15 "NO_DATA_EXISTS" 14 "STALLED" 13 "NotUsed" 12 "AUTO_ADJUST" 11 "COURTESYWIPE" 10 "AUTO_HIGH" 9 "AUTO_LOW" 8 "WASH" 7 "MIST_FLICK" 6 "MAN_HIGH" 5 "MAN_LOW" 4 "MAN_INT_ON" 3 "MAN_INT_OFF" 2 "OFF_MOVING" 1 "AUTO_OFF" 0 "OFF" ;
VAL_ 909 SecurityMsgTxt_D_Rq 3 "Message3" 2 "Message2" 1 "Message1" 0 "NoMessage" ;
VAL_ 909 PrmtrAlrmEvnt_D_Stat 15 "Diag_Tamper" 14 "Trailer" 13 "Shock_Sensor" 12 "Post_Crash" 11 "Panic" 10 "Intrusion" 9 "Inclination" 8 "Ign_Tamper" 7 "LG_Door" 6 "Decklid" 5 "Hood" 4 "PR_Door" 3 "PF_Door" 2 "DR_Door" 1 "DF_Door" 0 "Null" ;
VAL_ 909 TurnLghtSwtch_D_Stat2 3 "NotUsed" 2 "Right" 1 "Left" 0 "Off" ;
VAL_ 909 HeadLghtHiPrmsn_D_Stat 3 "CancelAndSuppress" 2 "Cancel" 1 "Hold" 0 "AllowChange" ;
VAL_ 909 SteWhlLckMsgTxt_D_Rq 3 "Message_3" 2 "Message_2" 1 "Message_1" 0 "No_Message" ;
VAL_ 909 immoMsgTxt_D_Rq 15 "Immo_Msg_15" 14 "Immo_Msg_14" 13 "Immo_Msg_13" 12 "Immo_Msg_12" 11 "Immo_Msg_11" 10 "Immo_Msg_10" 9 "Immo_Msg_9" 8 "Immo_Msg_8" 7 "Immo_Msg_7" 6 "Immo_Msg_6" 5 "Immo_Msg_5" 4 "Immo_Msg_4" 3 "Immo_Msg_3" 2 "Immo_Msg_2" 1 "Immo_Msg_1" 0 "Immo_Msg_0_Null" ;
VAL_ 909 PrsnlDevcChrgEnbl_B_Rq 1 "Active" 0 "Inactive" ;
VAL_ 909 TracKeyMde_D_Stat 3 "NotUsed" 2 "NotActive" 1 "Active" 0 "ModeNotDetermined" ;
VAL_ 909 PEBackupSlot_Stats 3 "No_Valid_FOB_In_Slot" 2 "MyKey_FOB_In_Slot" 1 "Standard_FOB_In_Slot" 0 "Null" ;
VAL_ 909 KeyMykeyTot_No_Cnt 13 "Thirteen" 12 "Twelve" 11 "Eleven" 10 "Ten" 9 "Nine" 8 "Eight" 7 "Seven" 6 "Six" 5 "Five" 4 "Four" 3 "Three" 2 "Two" 1 "One" 0 "Zero" 15 "Invalid" 14 "Unlimited" ;
VAL_ 909 KeyAdmnTot_No_Cnt 13 "Thirteen" 12 "Twelve" 11 "Eleven" 10 "Ten" 9 "Nine" 8 "Eight" 7 "Seven" 6 "Six" 5 "Five" 4 "Four" 3 "Three" 2 "Two" 1 "One" 0 "Zero" 15 "Invalid" 14 "Unlimited" ;
VAL_ 949 Tire_Press_RR_ORR_Data 65535 "Not_Supported" 65534 "Invalid" 65533 "Unknown" ;
VAL_ 949 Tire_Press_LR_OLR_Data 65535 "Not_Supported" 65534 "Invalid" 65533 "Unknown" ;
VAL_ 949 Tire_Press_LF_Data 65535 "Not_Supported" 65534 "Invalid" 65533 "Unknown" ;
VAL_ 949 Tire_Press_RF_Data 65535 "Not_Supported" 65534 "Invalid" 65533 "Unknown" ;
VAL_ 952 Tire_Press_IRR_Data 65535 "Not_Supported" 65534 "Invalid" 65533 "Unknown" ;
VAL_ 952 Tire_Press_ILR_Data 65535 "Not_Supported" 65534 "Invalid" 65533 "Unknown" ;
VAL_ 1044 ApaBrkErr_D_Stat 3 "Faulty" 2 "NoDataExists" 1 "Yes" 0 "No" ;
VAL_ 1044 StePinOffst_An_Est 65535 "Faulty" 65534 "NoDataExists" ;
VAL_ 1044 StePinOffst_D_Stat 3 "FineOffset" 2 "CoarseOffset" 1 "StoredOffset" 0 "OffsetNotCalculated" ;
VAL_ 1095 Pers4Phone_D_Stat 7 "SevenPhoneAssociated" 6 "SixPhoneAssociated" 5 "FivePhoneAssociated" 4 "FourPhoneAssociated" 3 "ThreePhoneAssociated" 2 "TwoPhoneAssociated" 1 "OnePhoneAssociated" 0 "NoPhoneAssociated" ;
VAL_ 1095 Pers3Phone_D_Stat 7 "SevenPhoneAssociated" 6 "SixPhoneAssociated" 5 "FivePhoneAssociated" 4 "FourPhoneAssociated" 3 "ThreePhoneAssociated" 2 "TwoPhoneAssociated" 1 "OnePhoneAssociated" 0 "NoPhoneAssociated" ;
VAL_ 1095 Pers2Phone_D_Stat 7 "SevenPhoneAssociated" 6 "SixPhoneAssociated" 5 "FivePhoneAssociated" 4 "FourPhoneAssociated" 3 "ThreePhoneAssociated" 2 "TwoPhoneAssociated" 1 "OnePhoneAssociated" 0 "NoPhoneAssociated" ;
VAL_ 1095 Pers1Phone_D_Stat 7 "SevenPhoneAssociated" 6 "SixPhoneAssociated" 5 "FivePhoneAssociated" 4 "FourPhoneAssociated" 3 "ThreePhoneAssociated" 2 "TwoPhoneAssociated" 1 "OnePhoneAssociated" 0 "NoPhoneAssociated" ;
VAL_ 1095 HeadLghtOn_D_Rq 7 "NotUsed2" 6 "NotUsed1" 5 "DrlBoth" 4 "DrlRight" 3 "DrlLeft" 2 "High" 1 "Low" 0 "Off" ;
VAL_ 1095 PepsKeyActv_D_Stat 15 "NotUsed11" 14 "NotUsed10" 13 "NotUsed9" 12 "NotUsed8" 11 "NotUsed7" 10 "NotUsed6" 9 "NotUsed5" 8 "Key4Active" 7 "NotUsed4" 6 "NotUsed3" 5 "NotUsed2" 4 "Key3Active" 3 "NotUsed1" 2 "Key2Active" 1 "Key1Active" 0 "NoKeyActive" ;
VAL_ 1095 VehLck_D_Dsply 3 "Faulty" 2 "Unlock" 1 "Lock" 0 "Off" ;
VAL_ 1076 IpcGearDsplyRdy_B_Stat 0 "No" 1 "Yes" ;
VAL_ 1076 FogLghtRearButtn_B_Rq 0 "NotPressed" 1 "Pressed" ;
VAL_ 1076 FogLghtFrontButtn_B_Rq 0 "NotPressed" 1 "Pressed" ;
VAL_ 1076 AutoRgen_D_Rq 3 "NotUsed" 2 "AutExhFilterCleanOFF" 1 "AutExhFilterCleanON" 0 "No_Mode_Selected" ;
VAL_ 1076 W2S_LAMP_OK 1 "Yes" 0 "No" ;
VAL_ 1076 OdoTripRx_B_Actl 1 "Yes" 0 "No" ;
VAL_ 1076 DrvSlipCtlMde_B_RqMyKey 1 "On" 0 "Off" ;
VAL_ 1076 FuelLvlWarn_D_Actl 3 "NotUsed" 2 "VeryLow" 1 "Low" 0 "OK" ;
VAL_ 1076 DieslFuelBio_B_ActlDrv 1 "Biodiesel_User" 0 "Non_Biodiesel_User" ;
VAL_ 1076 FuelSecndActv_B_Actl 1 "Yes" 0 "No" ;
VAL_ 1076 HILL_DESC_SW 1 "On" 0 "Off" ;
VAL_ 1076 FUEL_SENSOR_NUM 1 "Dual_Sensors" 0 "Single_Sensor" ;
VAL_ 1076 TirePReset_B_Rq 1 "Reset" 0 "Null" ;
VAL_ 1071 EngMnfld3_P_Actl 255 "Faulty" 254 "NoDataExists" ;
VAL_ 1071 CluPdlPosPcMeas_D_Qf 3 "OK" 2 "Not_Within_Specifications" 1 "No_Data_Exists" 0 "Faulty" ;
VAL_ 1057 FohEng_D_Rq 3 "AutoEnable_ParkEnable" 2 "AutoDisable_ParkEnable" 1 "AutoEnable_ParkDisable" 0 "Disable_Stop" ;
VAL_ 1057 EngIdlShutDwnTxt_D_Rq 3 "NotUsed" 2 "EngineShutdownOnPrevDrive" 1 "FeatureDisabledDueToFault" 0 "NoMessage" ;
VAL_ 1057 EngIdlShutDown_D_Stat 3 "Not_used" 2 "Engine_Shutdown" 1 "Initiated_Countdown" 0 "Normal_Operation" ;
VAL_ 1057 FUEL_ALCOHOL_PERCNT 255 "Invalid" ;
VAL_ 1057 TrnTotTq_Rt_Est 65535 "Fault" 65534 "Unknown" ;
VAL_ 1057 TrnTotLss_Tq_Est 255 "Fault" 254 "Unknown" ;
VAL_ 1057 ECMMILRequest 3 "Not_Used" 2 "Flash" 1 "On" 0 "Off" ;
VAL_ 1057 AirCondFluidHi_P_Actl 255 "Fault" 254 "Unknown" ;
VAL_ 1057 OilPressureWarning 1 "Low_Pressure_Lamp_On" 0 "Normal_Pressure_Lamp_Off" ;
VAL_ 1057 VehVLimStat_D_Actl 7 "Undefined_3" 6 "Undefined_2" 5 "Undefined_1" 4 "ASL_Fault_Condition" 3 "Active_and_Limiting" 2 "Active_but_Not_Limiting" 1 "Standby" 0 "Off" ;
VAL_ 1057 VehVLimActv_B_Actl 1 "Active" 0 "Inactive" ;
VAL_ 1057 CoolantFanStepAct 31 "Unused7" 30 "Unused6" 29 "Unused5" 28 "Unused4" 27 "Unused3" 26 "Unused2" 25 "Unused1" 23 "Step23" 22 "Step22" 21 "Step21" 20 "Step20" 19 "Step19" 18 "Step18" 17 "Step17" 16 "Step16" 15 "Step15" 14 "Step14" 13 "Step13" 12 "Step12" 11 "Step11" 10 "Step10" 9 "Step9" 8 "Step8" 7 "Step7" 6 "Step6" 5 "Step5" 4 "Step4" 3 "Step3" 2 "Step2" 1 "Step1" 24 "Max_Fan_Speed_Req" 0 "Fan_Cmd_Off" ;
VAL_ 870 PolicePurstMde_B_Stat 1 "On" 0 "Off" ;
VAL_ 870 RngPerChrgInst_L_Dsply 4095 "Faulty" 4094 "NoDataExists" ;
VAL_ 870 ChkPlgtoStrt_D_Dsply 3 "NotUsed" 2 "Is_VehicleUnplugged_Prompt" 1 "Check_Plug_to_Start" 0 "No_Message_Display" ;
VAL_ 870 HybMdeLimMsgTxt_D_Rq 3 "Limited_Req_Full_Defrost" 2 "Limited_Climate_Defrost" 1 "Limited_System_Performance" 0 "Null" ;
VAL_ 870 HybMdeMsgTxt_D2_Rq 15 "NotUsed_4" 14 "NotUsed_3" 13 "NotUsed_2" 12 "NotUsed_1" 11 "EvOverride_Avail" 10 "EvLaterActv_EvAuto_NowAvai" 9 "EvNowActv_EvAuto_LaterAvai" 8 "EvAutoActv_EvNow_LaterAvai" 7 "EvAutoActv_NoOtherMdeAvail" 6 "EvChrgActv_EvAutoMdeAvail" 5 "EvAutoActv_EvChrgMdeAvail" 4 "EvChrgActv_AllPhevMdeAvail" 3 "EvLaterActv_AllPhevMdeAvai" 2 "EvNowActv_AllPhevMdeAvail" 1 "EvAutoActv_AllPhevMdeAvail" 0 "Null" ;
VAL_ 870 EngMdeMsgTxt_D_Rq 7 "NotUsed_3" 6 "NotUsed_2" 5 "NotUsed_1" 4 "Charge" 3 "GlowingCharge" 2 "Hybrid" 1 "Ev" 0 "NoMessage" ;
VAL_ 870 ShifOutNtrlMsgTxt_D_Rq 7 "Message7" 6 "Message6" 5 "Message5" 4 "Message4" 3 "Message3" 2 "Message2" 1 "Message1" 0 "NoMessage" ;
VAL_ 869 PwrFlowTxt_D_Dsply 15 "NotUsed7" 14 "NotUsed6" 13 "NotUsed5" 12 "NotUsed4" 11 "Disply_Rgen_Chrg_Txt" 10 "Disp_Fast_Charge_Txt" 9 "Disp_Fast_Charge_Cmplt_Txt" 8 "Disp_Charge_Cmplt_Txt" 7 "Disp_Remote_Start_Txt" 6 "Disp_Eng_Drv_Txt" 5 "Disp_Elec_Drv_Txt" 4 "Disp_Idle_with_Chrg_Txt" 3 "Disp_Idle_Txt" 2 "Disp_Charg_HV_Batt_Txt" 1 "Disp_Hyb_Drive_Txt" 0 "No_Text" ;
VAL_ 869 EngOnMsg2_D_Dsply 14 "_0xE_to_1F_NotUsed" 12 "Battery_Temperature" 11 "Hill_Decent_Control" 10 "Fuel_Maintenance" 9 "Oil_Maintenance" 8 "Normal_Operation" 7 "Low_Gear" 6 "Batt_Charging" 5 "Engine_Cold" 4 "Neutral_Gear" 3 "Heater_Setting" 2 "High_Speed" 1 "Acceleration" 0 "No_Display" 13 "Drive_Mode_Selection" ;
VAL_ 869 EngOnMsg1_D_Dsply 14 "_0xE_to_1F_NotUsed" 12 "Battery_Temperature" 11 "Hill_Decent_Control" 10 "Fuel_Maintenance" 9 "Oil_Maintenance" 8 "Normal_Operation" 7 "Low_Gear" 6 "Batt_Charging" 5 "Engine_Cold" 4 "Neutral_Gear" 3 "Heater_Setting" 2 "High_Speed" 1 "Acceleration" 0 "No_Display" 13 "Drive_Mode_Selection" ;
VAL_ 869 FuelMaintMde_D_Dsply 3 "Feature_Not_Present" 2 "In_Fuel_Maint_Mode" 1 "Close_to_Fuel_Maint" 0 "OK" ;
VAL_ 869 RgenActv_B_Dsply 1 "On" 0 "Off" ;
VAL_ 869 EngOffTe_B_Dsply 1 "Eng_warm_engh_for_pd" 0 "Eng_not_warm_engh_for_pd" ;
VAL_ 869 EngActv_B_Dsply 1 "On" 0 "Off" ;
VAL_ 869 EffWhlThresOn_B_Dsply 1 "On" 0 "Off" ;
VAL_ 869 DchrgActv_B_Dsply 1 "On" 0 "Off" ;
VAL_ 869 ChrgActv_B_Dsply 1 "On" 0 "Off" ;
VAL_ 806 AirAmb_Te_RqCld 0 "NoRequest" 1 "Request" ;
VAL_ 806 ClimtCoolRear_B_Rq 1 "On" 0 "Off" ;
VAL_ 806 ClimtHeatRear_D_Rq 7 "NotUsed4" 6 "NotUsed3" 5 "HtrCoreClntFlwOnly" 4 "PtcHtrTestMde" 3 "Defrost_Defog" 2 "FastTempPullDownHeatingReq" 1 "OpportunisticHeatingReq" 0 "NoHeatingRequest" ;
VAL_ 806 SnowPlowMde_B_Enbl 1 "Enable" 0 "Disable" ;
VAL_ 806 ClimtDeltaLoad_Pw_Actl 63 "Faulty" 62 "NoDataExists" ;
VAL_ 806 StopStrtDrvMde_B_RqBtn 1 "Pressed" 0 "Not_Pressed" ;
VAL_ 806 HtrCorePump_B_Rq 1 "On" 0 "Off" ;
VAL_ 806 ClimtHeat_D_Rq 7 "NotUsed4" 6 "NotUsed3" 5 "HtrCoreClntFlwOnly" 4 "PtcHtrTestMde" 3 "Defrost_Defog" 2 "FastTempPullDownHeatingReq" 1 "OpportunisticHeatingReq" 0 "NoHeatingRequest" ;
VAL_ 806 ClimtCool_D_Rq 7 "NotUsed4" 6 "NotUsed3" 5 "NotUsed2" 4 "ElACTestMde" 3 "Defrost_Defog" 2 "FastTempPullDownCoolReq" 1 "OpportunisticCoolingReq" 0 "NoCoolingRequest" ;
VAL_ 806 HvacEvap_Te_Actl 1023 "Fault" ;
VAL_ 806 HvacAirCond_B_Rq 1 "Yes" 0 "No" ;
VAL_ 806 ClimtPw_B_Rq 1 "Yes" 0 "No" ;
VAL_ 806 WndwFrontHeat_B_Stat 1 "On" 0 "Off" ;
VAL_ 578 PtLatchActv_B_RqBcm 1 "On" 0 "Off" ;
VAL_ 578 immoSecureIdleMode 3 "NotUsed2" 2 "NotUsed1" 1 "Active" 0 "Inactive" ;
VAL_ 578 ReFuelSwtchStat_D_Actl 3 "NotUsed2" 2 "NotUsed1" 1 "On" 0 "Off" ;
VAL_ 578 FuelPumpPwr_D_Stat 7 "NotUsed3" 6 "NotUsed2" 5 "NotUsed1" 4 "Power_Off_Default" 3 "Power_Off_Command" 2 "Power_Off_Service" 1 "Power_Off_Impact" 0 "Power_On" ;
VAL_ 578 BattULo_U_Actl 255 "Fault" ;
VAL_ 578 PrkLckCtl_B_Enbl 1 "Enable" 0 "Disable" ;
VAL_ 578 PrkLckCtlMsgTxt_D_Rq 3 "BTSI_DI_3" 2 "BTSI_DI_2" 1 "BTSI_DI_1" 0 "Null_BTSI_DI" ;
VAL_ 578 BrkTrnShifLck_B_Stat 1 "Shift" 0 "NoShift" ;
VAL_ 578 PrkLckCtlUnlck_D_Stat 3 "Trans_And_Steer_Unlckd" 2 "Steering_Unlckd" 1 "Transmission_Unlckd" 0 "Null" ;
VAL_ 578 PrkLckCtlTow_B_Enbl 1 "Enable" 0 "Disable" ;
VAL_ 578 DriverCrankingReq 1 "Crank_Request" 0 "No_Crank_Request" ;
VAL_ 578 EngOff_T_Actl 65535 "Invalid" ;
VAL_ 578 DcacElPw_D_Rq 3 "NotUsed" 2 "AC_HighPower_Requested" 1 "AC_LowPower_Requested" 0 "AC_Power_NotRequested" ;
VAL_ 578 BattULo_I_Actl 16383 "Fault" ;
VAL_ 377 HvacAirFullOut_B_Rq 1 "Yes" 0 "No" ;
VAL_ 377 TrnManShif_D_IndDrv 7 "Undefined_3" 6 "Undefined_2" 5 "Shift_to_Neutral" 4 "Downshift_Recommendation" 3 "Upshift_Warning" 2 "Upshift_Performance" 1 "Upshift_Fuel_Economy" 0 "No_Indication" ;
VAL_ 377 TrnManShifGear_D_IndDrv 7 "Indicate_Reverse_Gear" 6 "Indicate_Gear6" 5 "Indicate_Gear5" 4 "Indicate_Gear4" 3 "Indicate_Gear3" 2 "Indicate_Gear2" 1 "Indicate_Gear1" 0 "No_Indication" ;
VAL_ 377 EngFuelCutFull_B_Inhbt 1 "Inhibit_DFSO" 0 "Normal" ;
VAL_ 377 EngDecelFuelCut_B_Allw 1 "Yes" 0 "No" ;
VAL_ 377 FuelFillInlet_B_Dsply 1 "Yes" 0 "No" ;
VAL_ 377 EngSrvcRqd_B_Rq 1 "Engine_Service_Required" 0 "No_engine_service_required" ;
VAL_ 377 OdoCount 255 "Invalid" ;
VAL_ 377 TrnKickDown_B_RqDrv 1 "Yes" 0 "No" ;
VAL_ 377 FuelFilterLamp_B_Dsply 1 "On" 0 "Off" ;
VAL_ 377 AirCondRec_B_Rq 1 "Yes" 0 "No" ;
VAL_ 377 AirCondClutch_B_Stats 1 "Yes" 0 "No" ;
VAL_ 377 EngAoutTqActl_D_Qf 3 "OK" 2 "Not_Within_Specifications" 1 "No_Data_Exists" 0 "Faulty" ;
VAL_ 376 GasPrtc_D_RqDsply 7 "NotUsed_5" 6 "NotUsed_4" 5 "NotUsed_3" 4 "NotUsed_2" 3 "NotUsed_1" 2 "GpfOverLimit" 1 "GpfAtLimit" 0 "NormalOperation" ;
VAL_ 376 LnchCtlSys_D_Stat 7 "NotUsed" 6 "On_LC_Unavailable_TC_Off" 5 "On_LC_Available_TC_Off" 4 "On_LC_Unavailable_TC_On" 3 "On_LC_Unavailable" 2 "On_LC_Available" 1 "On_LC_Active" 0 "LC_OFF" ;
VAL_ 376 DynoMde_B_Cmd 1 "DynomometerMode" 0 "NormalOperation" ;
VAL_ 376 AslChime_B_Rq 1 "Yes" 0 "No" ;
VAL_ 376 HvacHtrCore2_Te_Actl 1023 "Faulty" ;
VAL_ 376 PtcHtr_D_Cmd 3 "TurnOn" 2 "AutoMode" 1 "TurnOff" 0 "NoDecision_Initializing" ;
VAL_ 376 EcssLamp_D_RqDsply 3 "Not_Used" 2 "Flash" 1 "On" 0 "Off" ;
VAL_ 376 AirAmbTe_D_Qf 3 "OK" 2 "Not_Within_Specifications" 1 "No_Data_Exists" 0 "Faulty" ;
VAL_ 376 AirAmb_P_Actl 63 "Fault" 62 "NoDataExists" ;
VAL_ 376 AslIconDsply_D_Rq 3 "On_Passive_Overridden" 2 "On_Active" 1 "On_Passive" 0 "Off" ;
VAL_ 342 HtrLoop_B_Stat 1 "Fault" 0 "No_Fault" ;
VAL_ 342 TqmTerrMdeChng_D_Rdy 7 "Fault" 6 "Undefined_2" 5 "Undefined_1" 4 "ModeUnavailDrInputRqd" 3 "SpOpModes_NotSupported" 2 "ModeUnavailDynamicCond" 1 "Module_In_Initialization" 0 "Mode_Change_Available" ;
VAL_ 342 TqmTerrMde_D_Actl 7 "Fail_Safe_Default" 6 "Dynamic_Mode" 5 "Rock_Crawl_Mode" 4 "Mud_Ruts_Mode" 3 "Sand_Mode" 2 "Undefined" 1 "Low_Mu_Mode" 0 "Special_Operating_Mode_Off" ;
VAL_ 342 EngOvrhtMitgActv_D_Ind 3 "Undefined" 2 "Mode2" 1 "Mode1" 0 "Normal_Mode" ;
VAL_ 342 EngClntTe_D_Qf 3 "OK" 2 "Not_Within_Specifications" 1 "No_Data_Exists" 0 "Faulty" ;
VAL_ 342 EngAcsyArcPmp_Tq_Actl 255 "Fault" 254 "Unknown" ;
VAL_ 342 EngOilLvlDsply_D_Rq 15 "EngOil_LevelSys_CheckFault" 14 "Reserved_2" 13 "Reserved_1" 12 "Conditions_Unsuitable" 11 "Dipstick_Below_Minimum" 10 "Dipstick_Above_Maximum" 9 "Dipstick_Minimum" 8 "Dipstick_12_5_MinMaxRange" 7 "Dipstick_25_MinMaxRange" 6 "Dipstick_37_5_MinMaxRange" 5 "Dipstick_50_MinMaxRange" 4 "Dipstick_62_5_MinMaxRange" 3 "Dipstick_75_MinMaxRange" 2 "Dipstick_87_5_MinMaxRange" 1 "Dipstick_Maximum_Displayed" 0 "No_Message" ;
VAL_ 342 EngOil_Te_Actl 255 "Fault" 254 "Unknown" ;
VAL_ 342 EngTeColdPrtct_B_Rq 1 "On" 0 "Off" ;
VAL_ 573 VehStrtKeyType_D_Stat 3 "NotUsed_1" 2 "User" 1 "Factory" 0 "Null" ;
VAL_ 573 VehStrtKeySrc_D_Stat 7 "NotUsed_4" 6 "NotUsed_3" 5 "NotUsed_2" 4 "NotUsed_1" 3 "Legacy_Paak" 2 "Peps_and_Ikt" 1 "Digital_Key" 0 "Null" ;
VAL_ 573 NfcDevcSearch_B_Rq 1 "Active" 0 "Inactive" ;
